VERSION ""

NS_ :

BS_:

BU_: SGCP MCPB MCPA IDCM EVCU2 ECM BPCM

BO_ 292 BATTERY_HV_STATUS1: 64 BPCM
 SG_ MessageCounter_BATT_HV_STATUS1 : 435|4@0+ (1,0) [0|15] "-"  SGCP,EVCU2,MCPB,MCPA,IDCM
 SG_ CRC_BATT_HV_STATUS1 : 447|8@0+ (1,0) [0|255] "-"  SGCP,EVCU2,MCPB,MCPA,IDCM
 SG_ HVBatContactorWeldCheck : 302|1@0+ (1,0) [0|1] "" EVCU2
 SG_ HVBatReady : 268|1@0+ (1,0) [0|1] "" EVCU2
 SG_ BPCM_DC_CntctrsMidTrmOpeningWarn : 267|1@0+ (1,0) [0|1] "" EVCU2
 SG_ BPCM_DC_CntctrsShtTrmOpeningWarn : 266|1@0+ (1,0) [0|1] "" EVCU2
 SG_ BPCM_HV_Char_Main_Contac_Sts : 178|3@0+ (1,0) [0|7] "" EVCU2
 SG_ BPCM_HV_Trac_Main_Contac_Sts : 181|3@0+ (1,0) [0|7] "" SGCP,EVCU2,MCPB,MCPA,IDCM
 SG_ BPCM_HV_BalancingMode : 164|2@0+ (1,0) [0|3] "" EVCU2
 SG_ BPCM_HV_ChargingBusVoltage : 162|11@0+ (1,0) [0|2047] "V"  EVCU2
 SG_ BPCM_HV_TractionBusVoltage : 146|11@0+ (1,0) [0|2047] "V"  SGCP,EVCU2,MCPB,MCPA,IDCM
 SG_ BPCM_Pwr_Limp_Home_On : 55|1@0+ (1,0) [0|1] "" EVCU2
 SG_ BPCM_HV_Trac_Bus_Sts : 36|3@0+ (1,0) [0|7] "" SGCP,EVCU2,MCPB,MCPA,IDCM
 SG_ BPCM_HV_Char_Bus_Sts : 39|3@0+ (1,0) [0|7] "" EVCU2
 SG_ BPCM_HV_SOH_Low : 30|7@0+ (1,0) [0|127] "" EVCU2
 SG_ BPCM_HV_SOH : 22|7@0+ (1,0) [0|127] "" EVCU2
 SG_ HVBatContactorOpenTime : 15|8@0+ (0.2,0) [0|51] "Hours"  EVCU2
 SG_ HVBatLastSlept : 7|8@0+ (0.2,0) [0|51] "Days"  EVCU2
 SG_ BPCMInterlockSts : 54|3@0+ (1,0) [0|4] "" EVCU2
 SG_ BPCM_HV_BatIntrlk_InternalStat : 271|3@0+ (1,0) [0|3] "" EVCU2
 SG_ BPCM_HV_Temperature_Min : 218|11@0+ (0.1,-40) [-40|164.7] "°C"  EVCU2
 SG_ BPCM_HV_Temperature_Max : 202|11@0+ (0.1,-40) [-40|164.7] "°C"  EVCU2
 SG_ BPCM_HV_Temperature_Avg : 186|11@0+ (0.1,-40) [-40|164.7] "°C"  EVCU2
 SG_ BPCM_HV_SOC : 33|10@0+ (0.1,0) [0|102.3] "%"  EVCU2
 SG_ BPCM_HV_Outlet_Temp : 250|11@0+ (0.1,-40) [-40|164.7] "°C"  EVCU2
 SG_ BPCM_HV_InternalVoltage : 133|14@0+ (0.1,90.9) [90.9|1729.2] "V"  EVCU2
 SG_ BPCM_HV_Inlet_Temp : 234|11@0+ (0.1,-40) [-40|164.7] "°C"  EVCU2
 SG_ BPCM_HV_Current : 71|16@0+ (0.1,-3276.7) [-3276.7|3276.8] "A"  EVCU2
 SG_ BPCM_HV_Capacity : 51|12@0+ (0.15,0) [0|614.25] "Ah"  EVCU2
 SG_ BPCM_HV_Battery_GFD_Sts : 149|3@0+ (1,0) [0|4] "" EVCU2
 SG_ BPCM_Wakeup_Request : 23|1@0+ (1,0) [0|1] "" EVCU2
 SG_ BPCM_HV_ThermalRunaway : 135|2@0+ (1,0) [0|3] "" EVCU2
 SG_ HVBP_Busbar_Temp : 423|8@0+ (1,-40) [-40|215] "°C"  EVCU2
 SG_ HVBP_BDU_Busbar_Temp : 415|8@0+ (1,-40) [-40|215] "°C"  EVCU2
 SG_ DC_Charge_Type_Status : 319|3@0+ (1,0) [0|7] "" EVCU2
 SG_ BPCM_Series_Voltage : 367|13@0+ (0.1,90.9) [90.9|910] "V"  EVCU2
 SG_ BPCM_Request_for_Aux_Load_off : 313|1@0+ (1,0) [0|1] "" EVCU2
 SG_ BPCM_HV_Trac_Main_Contac_Config : 316|3@0+ (1,0) [0|7] "" EVCU2
 SG_ BPCM_HV_InternalVoltageString2 : 351|13@0+ (0.1,90.9) [90.9|910] "V"  EVCU2
 SG_ BPCM_HV_InternalVoltageString1 : 335|13@0+ (0.1,90.9) [90.9|910] "V"  EVCU2
 SG_ BPCM_HV_DCFC_Isolation_Sts : 167|3@0+ (1,0) [0|7] "" EVCU2
 SG_ BPCM_HV_Trac_PreCha_Contac_Sts : 354|3@0+ (1,0) [0|7] "" EVCU2
 SG_ BPCM_HV_Current_String2 : 399|16@0+ (0.1,-3276.7) [-3276.7|3276.8] "A"  EVCU2

BO_ 485 BATTERY_HV_VLIMITS: 64 BPCM
 SG_ MessageCounter_BATT_HV_VLIMITS : 435|4@0+ (1,0) [0|15] "-"  EVCU2
 SG_ CRC_BATT_HV_VLIMITS : 447|8@0+ (1,0) [0|255] "-"  EVCU2
 SG_ BPCM_HV_NumCellMinTemp : 224|9@0+ (1,0) [0|511] "" EVCU2
 SG_ BPCM_HV_NumCellMaxTemp : 192|9@0+ (1,0) [0|511] "" EVCU2
 SG_ BPCM_HV_NumCellMinVolt : 80|9@0+ (1,0) [0|511] "" EVCU2
 SG_ BPCM_HV_NumCellMaxVolt : 64|9@0+ (1,0) [0|511] "" EVCU2
 SG_ BPCM_Min_Pk_Volt_Allowed : 50|11@0+ (1,0) [0|2047] "V"  EVCU2
 SG_ BPCM_Max_Pk_Volt_Allowed : 18|11@0+ (1,0) [0|2047] "V"  EVCU2
 SG_ BPCM_OCV_Min_Cell_Volt : 180|13@0+ (0.001,0) [0|8.191] "V"  EVCU2
 SG_ BPCM_OCV_Max_Cell_Volt : 164|13@0+ (0.001,0) [0|8.191] "V"  EVCU2
 SG_ BPCM_OCV_Avg_Cell_Volt : 148|13@0+ (0.001,0) [0|8.191] "V"  EVCU2
 SG_ BPCM_Min_Cell_Volt_Allowed : 36|13@0+ (0.001,0) [0|8.191] "V"  EVCU2
 SG_ BPCM_Max_Cell_Volt_Allowed : 132|13@0+ (0.001,0) [0|8.191] "V"  EVCU2
 SG_ BPCM_HV_Insulation_Resistance : 215|16@0+ (1,0) [0|65535] "kOhm"  EVCU2
 SG_ BPCM_Cell_Volt_Min : 116|13@0+ (0.001,0) [0|8.191] "V"  EVCU2
 SG_ BPCM_Cell_Volt_Max : 100|13@0+ (0.001,0) [0|8.191] "V"  EVCU2
 SG_ BPCM_Cell_Volt_Avg : 4|13@0+ (0.001,0) [0|8.191] "V"  EVCU2

BO_ 288 BATTERY_HV_POWERLIMITS: 64 BPCM
 SG_ BPCM_HV_HVBatChargeStat : 215|3@0+ (1,0) [0|7] "" EVCU2
 SG_ BPCM_HV_PwrLmtInstDschg : 245|14@0+ (0.1,0) [0|1638.3] "" EVCU2
 SG_ BPCM_HV_PwrLmtInstChrg : 309|14@0+ (0.1,0) [0|1638.3] "" EVCU2
 SG_ BPCM_HV_Pwr_MaxDischrg_ShrTrm : 69|14@0+ (0.1,0) [0|1638.3] "kW"  EVCU2
 SG_ BPCM_HV_Power_MaxDischarge_MdTrm : 133|14@0+ (0.1,0) [0|1638.3] "kW"  EVCU2
 SG_ BPCM_HV_Power_MaxDischarge_LgTrm : 197|14@0+ (0.1,0) [0|1638.3] "kW"  EVCU2
 SG_ BPCM_HV_Power_MaxCharge_ShrTrm : 53|14@0+ (0.1,0) [0|1638.3] "kW"  EVCU2
 SG_ BPCM_HV_Power_MaxCharge_MdTrm : 117|14@0+ (0.1,0) [0|1638.3] "kW"  EVCU2
 SG_ BPCM_HV_Power_MaxCharge_LgTrm : 181|14@0+ (0.1,0) [0|1638.3] "kW"  EVCU2
 SG_ BPCM_HV_CrntLmtInstDschg : 374|15@0+ (0.1,0) [0|3276.7] "A"  EVCU2
 SG_ BPCM_HV_CrntLmtInstChrg : 390|15@0+ (0.1,0) [0|3276.7] "A"  EVCU2
 SG_ BPCM_HV_ChargingCurrentProfile : 6|15@0+ (0.1,0) [0|3276.7] "A"  EVCU2
 SG_ BPCM_HV_Cell_MinDischrg_Imped : 228|13@0+ (0.01,0) [0|81.91] "Ohm"  EVCU2
 SG_ BPCM_HV_Cell_MaxDischrg_Imped : 212|13@0+ (0.01,0) [0|81.91] "Ohm"  EVCU2
 SG_ BPCM_CntctrsShtTrmOpeningWarn : 417|1@0+ (1,0) [0|1] "" EVCU2,IDCM
 SG_ BPCM_CntctrsMidTrmOpeningWarn : 416|1@0+ (1,0) [0|1] "" EVCU2
 SG_ MessageCounter_BATT_HV_POWERLIMS : 435|4@0+ (1,0) [0|15] "-"  EVCU2
 SG_ CRC_BATT_HV_POWERLIMS : 447|8@0+ (1,0) [0|255] "-"  EVCU2

BO_ 2654339273 PDC_INFO_FD_SGCP: 32 SGCP
 SG_ WakeupSource_FD16_SGCP : 95|8@0+ (1,0) [0|255] "" EVCU2
 SG_ WakeupSource_FD05_SGCP : 23|8@0+ (1,0) [0|255] "" EVCU2
 SG_ StayActiveSource_FD16_SGCP : 111|64@0+ (1,0) [0|0] "" EVCU2
 SG_ StayActiveSource_FD05_SGCP : 31|64@0+ (1,0) [0|0] "" EVCU2
 SG_ PreviousCanNMState_FD16_SGCP : 103|4@0+ (1,0) [0|15] "" EVCU2
 SG_ PreviousCanNMState_FD05_SGCP : 11|4@0+ (1,0) [0|15] "" EVCU2
 SG_ GenericFailSts_FD16_SGCP : 180|1@0+ (1,0) [0|1] "" EVCU2
 SG_ GenericFailSts_FD05_SGCP : 5|1@0+ (1,0) [0|1] "" EVCU2
 SG_ EOL_FD16_SGCP : 2|1@0+ (1,0) [0|1] "-"  EVCU2
 SG_ EOL_FD05_SGCP : 7|1@0+ (1,0) [0|1] "-"  EVCU2
 SG_ DES_FD16_SGCP : 183|2@0+ (1,0) [0|3] "" EVCU2
 SG_ DES_FD05_SGCP : 4|2@0+ (1,0) [0|3] "" EVCU2
 SG_ CurrentFailSts_FD16_SGCP : 181|1@0+ (1,0) [0|1] "" EVCU2
 SG_ CurrentFailSts_FD05_SGCP : 6|1@0+ (1,0) [0|1] "" EVCU2
 SG_ CurrentCanNMState_FD16_SGCP : 99|4@0+ (1,0) [0|15] "" EVCU2
 SG_ CurrentCanNMState_FD05_SGCP : 15|4@0+ (1,0) [0|15] "" EVCU2

BO_ 2654339161 PDC_INFO_FD_MCPB: 32 MCPB
 SG_ WakeupSource_FD16_MCPB : 95|8@0+ (1,0) [0|255] "" EVCU2
 SG_ WakeupSource_FD05_MCPB : 23|8@0+ (1,0) [0|255] "" EVCU2
 SG_ StayActiveSource_FD16_MCPB : 111|64@0+ (1,0) [0|0] "" EVCU2
 SG_ StayActiveSource_FD05_MCPB : 31|64@0+ (1,0) [0|0] "" EVCU2
 SG_ PreviousCanNMState_FD16_MCPB : 103|4@0+ (1,0) [0|15] "" EVCU2
 SG_ PreviousCanNMState_FD05_MCPB : 11|4@0+ (1,0) [0|15] "" EVCU2
 SG_ GenericFailSts_FD05_MCPB : 5|1@0+ (1,0) [0|1] "" EVCU2
 SG_ EOL_FD16_MCPB : 2|1@0+ (1,0) [0|1] "-"  EVCU2
 SG_ EOL_FD05_MCPB : 7|1@0+ (1,0) [0|1] "-"  EVCU2
 SG_ DES_FD05_MCPB : 4|2@0+ (1,0) [0|3] "" EVCU2
 SG_ CurrentFailSts_FD05_MCPB : 6|1@0+ (1,0) [0|1] "" EVCU2
 SG_ CurrentCanNMState_FD16_MCPB : 99|4@0+ (1,0) [0|15] "" EVCU2
 SG_ CurrentCanNMState_FD05_MCPB : 15|4@0+ (1,0) [0|15] "" EVCU2
 SG_ GenericFailSts_FD16_MCPB : 172|1@0+ (1,0) [0|1] "" EVCU2
 SG_ DES_FD16_MCPB : 175|2@0+ (1,0) [0|3] "" EVCU2
 SG_ CurrentFailSts_FD16_MCPB : 173|1@0+ (1,0) [0|1] "" EVCU2

BO_ 2654339160 PDC_INFO_FD_MCPA: 32 MCPA
 SG_ WakeupSource_FD16_MCPA : 95|8@0+ (1,0) [0|255] "" EVCU2
 SG_ WakeupSource_FD05_MCPA : 23|8@0+ (1,0) [0|255] "" EVCU2
 SG_ StayActiveSource_FD16_MCPA : 111|64@0+ (1,0) [0|0] "" EVCU2
 SG_ StayActiveSource_FD05_MCPA : 31|64@0+ (1,0) [0|0] "" EVCU2
 SG_ PreviousCanNMState_FD16_MCPA : 103|4@0+ (1,0) [0|15] "" EVCU2
 SG_ PreviousCanNMState_FD05_MCPA : 11|4@0+ (1,0) [0|15] "" EVCU2
 SG_ GenericFailSts_FD05_MCPA : 5|1@0+ (1,0) [0|1] "" EVCU2
 SG_ EOL_FD16_MCPA : 2|1@0+ (1,0) [0|1] "-"  EVCU2
 SG_ EOL_FD05_MCPA : 7|1@0+ (1,0) [0|1] "-"  EVCU2
 SG_ DES_FD05_MCPA : 4|2@0+ (1,0) [0|3] "" EVCU2
 SG_ CurrentFailSts_FD05_MCPA : 6|1@0+ (1,0) [0|1] "" EVCU2
 SG_ CurrentCanNMState_FD16_MCPA : 99|4@0+ (1,0) [0|15] "" EVCU2
 SG_ CurrentCanNMState_FD05_MCPA : 15|4@0+ (1,0) [0|15] "" EVCU2
 SG_ GenericFailSts_FD16_MCPA : 172|1@0+ (1,0) [0|1] "" EVCU2
 SG_ DES_FD16_MCPA : 175|2@0+ (1,0) [0|3] "" EVCU2
 SG_ CurrentFailSts_FD16_MCPA : 173|1@0+ (1,0) [0|1] "" EVCU2

BO_ 2654339142 PDC_INFO_FD_BPCM: 32 BPCM
 SG_ WakeupSource_FD05_BPCM : 175|8@0+ (1,0) [0|255] "" EVCU2
 SG_ StayActiveSource_FD05_BPCM : 99|64@0+ (1,0) [0|0] "" EVCU2
 SG_ PreviousCanNMState_FD05_BPCM : 103|4@0+ (1,0) [0|15] "" EVCU2
 SG_ GenericFailSts_FD05_BPCM : 89|1@0+ (1,0) [0|1] "" EVCU2
 SG_ EOL_FD05_BPCM : 1|1@0+ (1,0) [0|1] "-"  EVCU2
 SG_ DES_FD05_BPCM : 91|2@0+ (1,0) [0|3] "" EVCU2
 SG_ CurrentFailSts_FD05_BPCM : 6|1@0+ (1,0) [0|1] "" EVCU2
 SG_ CurrentCanNMState_FD05_BPCM : 95|4@0+ (1,0) [0|15] "" EVCU2

BO_ 2564682108 DIAGNOSTIC_ROE_SGCP: 8 SGCP
 SG_ N_PDU_18DDF17C : 7|64@0+ (1,0) [0|0] "" EVCU2

BO_ 2564682364 DIAGNOSTIC_ROE_FD_SGCP: 64 SGCP
 SG_ N_PDU_18DDF27C : 7|64@0+ (1,0) [0|0] "" EVCU2

BO_ 2564485500 DIAGNOSTIC_RESPONSE_SGCP: 8 SGCP
 SG_ N_PDU_18DAF17C : 7|64@0+ (1,0) [0|0] "" EVCU2

BO_ 2564485756 DIAGNOSTIC_RESPONSE_FD_SGCP: 64 SGCP
 SG_ N_PDU_18DAF27C : 7|64@0+ (1,0) [0|0] "" EVCU2

BO_ 2564455665 DIAGNOSTIC_REQUEST_SGCP: 8 EVCU2
 SG_ N_PDU_18DA7CF1 : 7|64@0+ (1,0) [0|0] "" SGCP

BO_ 2564455666 DIAGNOSTIC_REQUEST_FD_SGCP: 64 EVCU2
 SG_ N_PDU_18DA7CF2 : 7|64@0+ (1,0) [0|0] "" SGCP

BO_ 263 PT_SYSTEM_FD_1: 64 EVCU2
 SG_ OptimdStrtReqdActr : 2|3@0+ (1,0) [0|7] "" ECM
 SG_ OptimdEngStrtStpType : 7|5@0+ (1,0) [0|31] "" ECM
 SG_ OptimdEngOnOffCmd : 15|1@0+ (1,0) [0|1] "" ECM
 SG_ Hyb_ProducingTorque : 13|1@0+ (1,0) [0|1] "" ECM
 SG_ HCPFuelDisable : 14|1@0+ (1,0) [0|1] "" ECM
 SG_ PowertrainPrplsnActv_PT : 146|1@0+ (1,0) [0|1] "" MCPB,MCPA,BPCM
 SG_ GearEngagedForDisplay_PT : 12|5@0+ (1,0) [0|31] "" SGCP,MCPB,MCPA,BPCM
 SG_ GearEngaged_PT : 132|4@0+ (1,0) [0|15] "" MCPB
 SG_ DriveReady_PT : 166|1@0+ (1,0) [0|1] "" BPCM
 SG_ MessageCounter_PT_SYSTEM_FD_1 : 435|4@0+ (1,0) [0|15] "-"  SGCP,MCPB,MCPA,ECM
 SG_ GasPedalPositionFailSts_PT : 145|1@0+ (1,0) [0|1] "" ECM
 SG_ GasPedalPosition_PT : 31|8@0+ (0.392,0) [0|99.96] "%"  ECM
 SG_ CRC_PT_SYSTEM_FD_1 : 447|8@0+ (1,0) [0|255] "-"  SGCP,MCPB,MCPA,ECM
 SG_ PropulsionMode_PT : 314|3@0+ (1,0) [0|7] "" ECM
 SG_ PropulsionSystemActive_PT : 209|1@0+ (1,0) [0|1] "-"  ECM

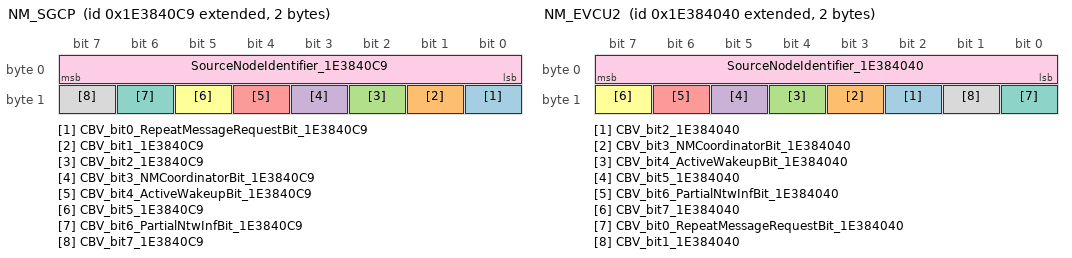
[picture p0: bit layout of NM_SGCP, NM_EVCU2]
BO_ 2654486729 NM_SGCP: 2 SGCP
 SG_ CBV_bit0_RepeatMessageRequestBit_1E3840C9 : 8|1@0+ (1,0) [0|1] "" EVCU2,MCPB,MCPA,IDCM,BPCM,ECM
 SG_ CBV_bit1_1E3840C9 : 9|1@0+ (1,0) [0|1] "" EVCU2,MCPB,MCPA,IDCM,BPCM,ECM
 SG_ CBV_bit2_1E3840C9 : 10|1@0+ (1,0) [0|1] "" EVCU2,MCPB,MCPA,IDCM,BPCM,ECM
 SG_ CBV_bit3_NMCoordinatorBit_1E3840C9 : 11|1@0+ (1,0) [0|1] "" EVCU2,MCPB,MCPA,IDCM,BPCM,ECM
 SG_ CBV_bit4_ActiveWakeupBit_1E3840C9 : 12|1@0+ (1,0) [0|1] "" EVCU2,MCPB,MCPA,IDCM,BPCM,ECM
 SG_ CBV_bit5_1E3840C9 : 13|1@0+ (1,0) [0|1] "" EVCU2,MCPB,MCPA,IDCM,BPCM,ECM
 SG_ CBV_bit6_PartialNtwInfBit_1E3840C9 : 14|1@0+ (1,0) [0|1] "" EVCU2,MCPB,MCPA,IDCM,BPCM,ECM
 SG_ CBV_bit7_1E3840C9 : 15|1@0+ (1,0) [0|1] "" EVCU2,MCPB,MCPA,IDCM,BPCM,ECM
 SG_ SourceNodeIdentifier_1E3840C9 : 7|8@0+ (1,0) [0|255] "-"  EVCU2,MCPB,MCPA,IDCM,BPCM,ECM

BO_ 216 PT_ENERGY_FD_1: 64 EVCU2
 SG_ MC_PT_ENERGY_FD_1 : 435|4@0+ (1,0) [0|15] "-"  IDCM,BPCM
 SG_ DCChrgVoltMin_PT : 55|14@0+ (0.1,0) [0|1638.30] "" Vector__XXX
 SG_ DCChrgVoltMax_PT : 151|14@0+ (0.1,0) [0|1638.30] "V"  Vector__XXX
 SG_ DCChrgPwrLim_PT : 119|14@0+ (0.1,-815) [-815|823.30] "kW"  Vector__XXX
 SG_ DCChrgCurrentRq_PT : 95|14@0+ (0.1,-815) [-815|823.30] "A"  Vector__XXX
 SG_ DCChrgCurrentLimit_PT : 21|14@0+ (0.1,-815) [-815|823.30] "A"  Vector__XXX
 SG_ DCChargeInitialized_PT : 56|1@0+ (1,0) [0|1] "" BPCM
 SG_ DCChargeEnRq_PT : 38|1@0+ (1,0) [0|1] "" Vector__XXX
 SG_ CRC_PT_ENERGY_FD_1 : 447|8@0+ (1,0) [0|255] "-"  IDCM,BPCM
 SG_ BPCM_OBCM_AC_ContactorCmd_PT : 140|3@0+ (1,0) [0|7] "" IDCM,BPCM
 SG_ BMS_HV_TracCntctr_Cmd_PT : 4|3@0+ (1,0) [0|7] "" MCPB,MCPA,IDCM,BPCM
 SG_ BMS_HV_RefTracHVBus_V_Vldty_PT : 23|1@0+ (1,0) [0|1] "" BPCM
 SG_ BMS_HV_RefTracHVBus_V_PT : 1|10@0+ (1,0) [0|1023] "" BPCM
 SG_ BMS_HV_GFD_Inhibition_PT : 39|1@0+ (1,0) [0|1] "" BPCM
 SG_ BMS_HV_DC_Chrgng_Cntct_K_Cmd_PT : 82|3@0+ (1,0) [0|7] "" MCPB,MCPA,IDCM,BPCM
 SG_ BatteryVoltage_Raw_PT : 97|10@0+ (0.2,0) [0|204.60] "V"  MCPB,MCPA,IDCM,BPCM
 SG_ APM_LV_VsetPoint_PT : 135|11@0+ (0.01,0) [0|20.47] "V"  IDCM
 SG_ APM_LV_VActual_PT : 71|9@0+ (0.04,0) [0|20.44] "V"  IDCM
 SG_ APM_LV_IMax_PT : 167|9@0+ (1,0) [0|511] "A"  IDCM
 SG_ APM_HV_IMax_PT : 87|5@0+ (0.8,0) [0|24.8] "A"  IDCM
 SG_ APM_TypeCtrl_PT : 78|4@0+ (1,0) [0|15] "" IDCM
 SG_ EVCU_Resp_AUX_LoadTurned_Off : 174|1@0+ (1,0) [0|1] "" BPCM
 SG_ DC_Charge_Type_Command : 121|2@0+ (1,0) [0|3] "" BPCM
 SG_ BMS_HV_Char_Main_Contac_Cmd_PT : 173|3@0+ (1,0) [0|7] "" BPCM

BO_ 1042 IDCM_ISO15118_STATUS1: 64 IDCM
 SG_ Contract_Certificate_Present : 244|1@0+ (1,0) [0|1] "" EVCU2
 SG_ EVSE_Offered_AC_Single_Phase : 234|1@0+ (1,0) [0|1] "" EVCU2
 SG_ EVSE_Offered_AC_Three_Phase : 233|1@0+ (1,0) [0|1] "" EVCU2

BO_ 1041 EVCU_ISO15118_STATUS1: 64 EVCU2
 SG_ EVMinCurrent : 264|9@0+ (1,0) [0|511] "A"  IDCM
 SG_ EVMaxVoltage : 233|10@0+ (1,0) [0|1023] "V"  IDCM
 SG_ EVMaxCurrent : 248|9@0+ (1,0) [0|511] "A"  IDCM
 SG_ Eamount : 281|18@0+ (1,0) [0|262143] "Wh"  IDCM

BO_ 2654486592 NM_EVCU2: 2 EVCU2
 SG_ CBV_bit2_1E384040 : 10|1@0+ (1,0) [0|1] "" SGCP,MCPB,MCPA,IDCM,BPCM,ECM
 SG_ CBV_bit3_NMCoordinatorBit_1E384040 : 11|1@0+ (1,0) [0|1] "" SGCP,MCPB,MCPA,IDCM,BPCM,ECM
 SG_ CBV_bit4_ActiveWakeupBit_1E384040 : 12|1@0+ (1,0) [0|1] "" SGCP,MCPB,MCPA,IDCM,BPCM,ECM
 SG_ CBV_bit5_1E384040 : 13|1@0+ (1,0) [0|1] "" SGCP,MCPB,MCPA,IDCM,BPCM,ECM
 SG_ CBV_bit6_PartialNtwInfBit_1E384040 : 14|1@0+ (1,0) [0|1] "" SGCP,MCPB,MCPA,IDCM,BPCM,ECM
 SG_ CBV_bit7_1E384040 : 15|1@0+ (1,0) [0|1] "" SGCP,MCPB,MCPA,IDCM,BPCM,ECM
 SG_ CBV_bit0_RepeatMessageRequestBit_1E384040 : 8|1@0+ (1,0) [0|1] "" SGCP,MCPB,MCPA,IDCM,BPCM,ECM
 SG_ CBV_bit1_1E384040 : 9|1@0+ (1,0) [0|1] "" SGCP,MCPB,MCPA,IDCM,BPCM,ECM
 SG_ SourceNodeIdentifier_1E384040 : 7|8@0+ (1,0) [0|255] "-"  SGCP,MCPB,MCPA,IDCM,BPCM,ECM

BO_ 2564455444 DIAGNOSTIC_RESPONSE_FOTA_SGCP: 64 SGCP
 SG_ N_PDU_18DA7C14 : 7|64@0+ (1,0) [0|0] "" EVCU2

BO_ 2564455669 DIAGNOSTIC_REQUEST_FOTA_SGCP: 64 EVCU2
 SG_ N_PDU_18DA7CF5 : 7|64@0+ (1,0) [0|0] "" SGCP

BO_ 1048 RPF_FD_3: 64 EVCU2
 SG_ V2H_HVCMS_EVMax_P_Limit : 21|14@0+ (0.1,-819.1) [-819.1|819.2] "kW"  IDCM

BO_ 1046 RPF_FD_1: 64 IDCM
 SG_ V2H_HVCMS_EVSEMaxPowerLimit : 7|14@0+ (0.1,-819.1) [-819.1|819.2] "kW"  EVCU2

BO_ 1811 REAL_TIME_CLOCK: 64 EVCU2
 SG_ Real_Time_Validity : 39|1@0+ (1,0) [0|1] "" SGCP,MCPB,MCPA
 SG_ Real_Time_Clock : 7|32@0+ (1,0) [0|4294967295] "" SGCP,MCPB,MCPA

BO_ 1070 SGCP_OBD_DTC: 32 SGCP
 SG_ SGCP_DTC_Stat2 : 26|3@0+ (1,0) [0|7] "" EVCU2
 SG_ SGCP_DTC_Stat1 : 18|3@0+ (1,0) [0|7] "" EVCU2
 SG_ SGCP_DTC_Idx2 : 31|5@0+ (1,0) [0|31] "" EVCU2
 SG_ SGCP_DTC_Idx1 : 23|5@0+ (1,0) [0|31] "" EVCU2
 SG_ SGCP_CalChar : 15|8@0+ (1,0) [0|255] "" EVCU2
 SG_ SGCP_Cal_ID_Idx : 7|6@0+ (1,0) [0|63] "" EVCU2
 SG_ MessageCounter_SGCP_OBD_DTC : 179|4@0+ (1,0) [0|15] ""  EVCU2
 SG_ CRC_SGCP_OBD_DTC : 191|8@0+ (1,0) [0|255] ""  EVCU2

BO_ 1065 MCPB_OBD_DTC: 32 MCPB
 SG_ MessageCounter_MCPB_OBD_DTC : 179|4@0+ (1,0) [0|15] ""  EVCU2
 SG_ MCPB_DTC_Stat2 : 26|3@0+ (1,0) [0|7] "" EVCU2
 SG_ MCPB_DTC_Stat1 : 18|3@0+ (1,0) [0|7] "" EVCU2
 SG_ MCPB_DTC_Idx2 : 31|5@0+ (1,0) [0|31] "" EVCU2
 SG_ MCPB_DTC_Idx1 : 23|5@0+ (1,0) [0|31] "" EVCU2
 SG_ MCPB_CalChar : 15|8@0+ (1,0) [0|255] "" EVCU2
 SG_ MCPB_Cal_ID_Idx : 7|6@0+ (1,0) [0|63] "" EVCU2
 SG_ CRC_MCPB_OBD_DTC : 191|8@0+ (1,0) [0|255] ""  EVCU2

BO_ 1057 MCPA_OBD_DTC: 32 MCPA
 SG_ MessageCounter_MCPA_OBD_DTC : 179|4@0+ (1,0) [0|15] ""  EVCU2
 SG_ MCPA_DTC_Stat2 : 26|3@0+ (1,0) [0|7] "" EVCU2
 SG_ MCPA_DTC_Stat1 : 18|3@0+ (1,0) [0|7] "" EVCU2
 SG_ MCPA_DTC_Idx2 : 31|5@0+ (1,0) [0|31] "" EVCU2
 SG_ MCPA_DTC_Idx1 : 23|5@0+ (1,0) [0|31] "" EVCU2
 SG_ MCPA_CalChar : 15|8@0+ (1,0) [0|255] "" EVCU2
 SG_ MCPA_Cal_ID_Idx : 7|6@0+ (1,0) [0|63] "" EVCU2
 SG_ CRC_MCPA_OBD_DTC : 191|8@0+ (1,0) [0|255] ""  EVCU2

CM_ SG_ 292 MessageCounter_BATT_HV_STATUS1 "This signal is a counter used for safety checks strategies. This counter is incremented of 1 (one) unit at each frame transmission.";
CM_ SG_ 292 CRC_BATT_HV_STATUS1 "CRC according to SAE J1850 standard at each frame transmission.";
CM_ SG_ 292 HVBatContactorWeldCheck "Contactor weld check report from BPCM for DC charging.";
CM_ SG_ 292 HVBatReady "High Voltage Battery Ready";
CM_ SG_ 292 BPCM_HV_Char_Main_Contac_Sts "DC Charging main contactor physical relay status.";
CM_ SG_ 292 BPCM_HV_Trac_Main_Contac_Sts "Traction main contactor physical relay status";
CM_ SG_ 292 BPCM_HV_BalancingMode "Balancing Mode";
CM_ SG_ 292 BPCM_HV_ChargingBusVoltage "Voltage measurement between positive main bus (after contactor) and negative charging branch.";
CM_ SG_ 292 BPCM_HV_TractionBusVoltage "Battery link traction bus voltage.";
CM_ SG_ 292 BPCM_Pwr_Limp_Home_On "Traction Battery Limp Home mode flag.";
CM_ SG_ 292 BPCM_HV_SOH_Low "State of Health calculated at low SOC.";
CM_ SG_ 292 BPCM_HV_SOH "Status of Healt";
CM_ SG_ 292 HVBatContactorOpenTime "Time Since Bat contactors last transitioned to Open.";
CM_ SG_ 292 HVBatLastSlept "Time since BPCM last went to sleep.";
CM_ SG_ 485 MessageCounter_BATT_HV_VLIMITS "This signal is a counter used for safety checks strategies. This counter is incremented of 1 (one) unit at each frame transmission.";
CM_ SG_ 485 CRC_BATT_HV_VLIMITS "CRC according to SAE J1850 standard at each frame transmission.";
CM_ SG_ 485 BPCM_HV_NumCellMinTemp "This signal indicates the Numner of the battery cell with the lowest temperature.";
CM_ SG_ 485 BPCM_HV_NumCellMaxTemp "This signal indicates the Number of the battery cell with the highest temperature.";
CM_ SG_ 485 BPCM_HV_NumCellMinVolt "This signal indicates the ID No. of cell with min. voltage";
CM_ SG_ 485 BPCM_HV_NumCellMaxVolt "This signal indicates the ID No. of cell with max. voltage";
CM_ SG_ 485 BPCM_Min_Pk_Volt_Allowed "This signal indicates the Minimum battery peak pack voltage.";
CM_ SG_ 485 BPCM_Max_Pk_Volt_Allowed "This signal indicates the Maximum battery pack voltage allowed.";
CM_ SG_ 292 BPCMInterlockSts "BPCM interlock state";
CM_ SG_ 292 BPCM_HV_BatIntrlk_InternalStat "HVIL Status internal";
CM_ SG_ 485 BPCM_OCV_Min_Cell_Volt "This signal indicates the Cell open circuit minimum voltage.";
CM_ SG_ 485 BPCM_OCV_Max_Cell_Volt "This signal indicates the Cell open circuit  maximum voltage.";
CM_ SG_ 485 BPCM_OCV_Avg_Cell_Volt "This signal indicates the Cell open circuit average voltage .";
CM_ SG_ 485 BPCM_Min_Cell_Volt_Allowed "This signal indicates the Minimum battery pack voltage.";
CM_ SG_ 485 BPCM_Max_Cell_Volt_Allowed "This signal indicates the Max cell voltage allowed.";
CM_ SG_ 485 BPCM_HV_Insulation_Resistance "This signal indicates the Insulation resistance.";
CM_ SG_ 485 BPCM_Cell_Volt_Min "This signal indicates the Min cell voltage.";
CM_ SG_ 485 BPCM_Cell_Volt_Max "This signal indicates the Max cell voltage.";
CM_ SG_ 485 BPCM_Cell_Volt_Avg "This signal indicates the Cell average voltage.";
CM_ SG_ 292 BPCM_HV_Temperature_Min "Battery Minimum Temperature 22/06/2020 Allegra Giordano - changes: Value, Max (previous values: 164,7 - 164,6) (Daniele Zaharia's request)";
CM_ SG_ 292 BPCM_HV_Temperature_Max "Battery Max Temperature 22/06/2020 Allegra Giordano - changes: Value, Max (previous values: 164,7 - 164,6) (Daniele Zaharia's request)";
CM_ SG_ 292 BPCM_HV_Temperature_Avg "Battery Average Temperature 22/06/2020 Allegra Giordano - changes: Value, Max (previous values: 164,7 - 164,6) (Daniele Zaharia' request)";
CM_ SG_ 292 BPCM_HV_SOC "State of Charge";
CM_ SG_ 292 BPCM_HV_Outlet_Temp "Outlet Temperature";
CM_ SG_ 292 BPCM_HV_InternalVoltage "Battery internal voltage.";
CM_ SG_ 292 BPCM_HV_Inlet_Temp "Inlet temperature";
CM_ SG_ 292 BPCM_HV_Current "Battery Current";
CM_ SG_ 292 BPCM_HV_Capacity "Battery Capacity";
CM_ SG_ 292 BPCM_HV_Battery_GFD_Sts "HV Battery ground fault detection(Isolation).";
CM_ SG_ 288 BPCM_HV_PwrLmtInstDschg "Instantaneous power prediction limit in discharge";
CM_ SG_ 288 BPCM_HV_PwrLmtInstChrg "Instantaneous power prediction limit in charge";
CM_ SG_ 288 BPCM_HV_Pwr_MaxDischrg_ShrTrm "This signal indicates the Maximum discharge power available for the next short term.";
CM_ SG_ 288 BPCM_HV_Power_MaxDischarge_MdTrm "This signal indicates the Maximum discharge power available for the next mid term.";
CM_ SG_ 288 BPCM_HV_Power_MaxDischarge_LgTrm "This signal indicates the Maximum discharge power available for the next long term.";
CM_ SG_ 288 BPCM_HV_Power_MaxCharge_ShrTrm "This signal indicates the Maximum charge power available for the next short term.";
CM_ SG_ 288 BPCM_HV_Power_MaxCharge_MdTrm "This signal indicates the Maximum charge power available for the next mid term.";
CM_ SG_ 288 BPCM_HV_Power_MaxCharge_LgTrm "This signal indicates the Maximum charge power available for the next long term.";
CM_ SG_ 288 BPCM_HV_CrntLmtInstDschg "BPCM_HV_CrntLmtInstDschg";
CM_ SG_ 288 BPCM_HV_CrntLmtInstChrg "BPCM_HV_CrntLmtInstChrg";
CM_ SG_ 288 BPCM_HV_ChargingCurrentProfile "This signal indicates the Charging current profile.";
CM_ SG_ 288 BPCM_HV_Cell_MinDischrg_Imped "This signal indicates the Maximum cell discharge impedance.";
CM_ SG_ 288 BPCM_HV_Cell_MaxDischrg_Imped "This signal indicates the Maximum cell discharge impedance.";
CM_ SG_ 288 BPCM_CntctrsShtTrmOpeningWarn "This signal indicates the Battery warning imminent emergency contactors opening.";
CM_ SG_ 288 BPCM_CntctrsMidTrmOpeningWarn "This signal indicates the Battery warning mid term emergency contactors opening.";
CM_ SG_ 2654339273 WakeupSource_FD16_SGCP "Indicates the reason the ECU was most recently awakened";
CM_ SG_ 2654339273 WakeupSource_FD05_SGCP "Indicates the reason the ECU was most recently awakened";
CM_ SG_ 2654339273 StayActiveSource_FD16_SGCP "Indicates the source that requests the ECU to stay active";
CM_ SG_ 2654339273 StayActiveSource_FD05_SGCP "Indicates the source that requests the ECU to stay active";
CM_ SG_ 2654339273 PreviousCanNMState_FD16_SGCP "Indicates the last CanNM state that the ECU existed in";
CM_ SG_ 2654339273 PreviousCanNMState_FD05_SGCP "Indicates the last CanNM state that the ECU existed in";
CM_ SG_ 2654339273 GenericFailSts_FD16_SGCP "Indicates the presence/absent of at least one DTC in the System Memory";
CM_ SG_ 2654339273 GenericFailSts_FD05_SGCP "Indicates the presence/absent of at least one DTC in the System Memory";
CM_ SG_ 2654339273 EOL_FD16_SGCP "Indicates if the ECU requires configuration data at the assembly plant End Of Line";
CM_ SG_ 2654339273 EOL_FD05_SGCP "Indicates if the ECU requires configuration data at the assembly plant End Of Line";
CM_ SG_ 2654339273 DES_FD16_SGCP "Indicates whether the ECU?s CAN cell is in either ErrorActive, or ErrorPassive state OR has just now recovered from a BusOff condition";
CM_ SG_ 2654339273 DES_FD05_SGCP "Indicates whether the ECU?s CAN cell is in either ErrorActive, or ErrorPassive state OR has just now recovered from a BusOff condition";
CM_ SG_ 2654339273 CurrentFailSts_FD16_SGCP "Indicates the presence/absence of at least one DTC with DTCStatus = present in the System Memory";
CM_ SG_ 2654339273 CurrentFailSts_FD05_SGCP "Indicates the presence/absence of at least one DTC with DTCStatus = present in the System Memory";
CM_ SG_ 2654339273 CurrentCanNMState_FD16_SGCP "Indicates that CanNM state the ECU is currently executing";
CM_ SG_ 2654339273 CurrentCanNMState_FD05_SGCP "Indicates that CanNM state the ECU is currently executing";
CM_ SG_ 2654339161 WakeupSource_FD16_MCPB "Indicates the reason the ECU was most recently awakened";
CM_ SG_ 2654339161 WakeupSource_FD05_MCPB "Indicates the reason the ECU was most recently awakened";
CM_ SG_ 2654339161 StayActiveSource_FD16_MCPB "Indicates the source that requests the ECU to stay active";
CM_ SG_ 2654339161 StayActiveSource_FD05_MCPB "Indicates the source that requests the ECU to stay active";
CM_ SG_ 2654339161 PreviousCanNMState_FD16_MCPB "Indicates the last CanNM state that the ECU existed in";
CM_ SG_ 2654339161 PreviousCanNMState_FD05_MCPB "Indicates the last CanNM state that the ECU existed in";
CM_ SG_ 2654339161 GenericFailSts_FD05_MCPB "Indicates the presence/absent of at least one DTC in the System Memory";
CM_ SG_ 2654339161 EOL_FD16_MCPB "Indicates if the ECU requires configuration data at the assembly plant End Of Line";
CM_ SG_ 2654339161 EOL_FD05_MCPB "Indicates if the ECU requires configuration data at the assembly plant End Of Line";
CM_ SG_ 2654339161 DES_FD05_MCPB "Indicates whether the ECU?s CAN cell is in either ErrorActive, or ErrorPassive state OR has just now recovered from a BusOff condition";
CM_ SG_ 2654339161 CurrentFailSts_FD05_MCPB "Indicates the presence/absence of at least one DTC with DTCStatus = present in the System Memory";
CM_ SG_ 2654339161 CurrentCanNMState_FD16_MCPB "Indicates that CanNM state the ECU is currently executing";
CM_ SG_ 2654339161 CurrentCanNMState_FD05_MCPB "Indicates that CanNM state the ECU is currently executing";
CM_ SG_ 2654339160 WakeupSource_FD16_MCPA "Indicates the reason the ECU was most recently awakened";
CM_ SG_ 2654339160 WakeupSource_FD05_MCPA "Indicates the reason the ECU was most recently awakened";
CM_ SG_ 2654339160 StayActiveSource_FD16_MCPA "Indicates the source that requests the ECU to stay active";
CM_ SG_ 2654339160 StayActiveSource_FD05_MCPA "Indicates the source that requests the ECU to stay active";
CM_ SG_ 2654339160 PreviousCanNMState_FD16_MCPA "Indicates the last CanNM state that the ECU existed in";
CM_ SG_ 2654339160 PreviousCanNMState_FD05_MCPA "Indicates the last CanNM state that the ECU existed in";
CM_ SG_ 2654339160 GenericFailSts_FD05_MCPA "Indicates the presence/absent of at least one DTC in the System Memory";
CM_ SG_ 2654339160 EOL_FD16_MCPA "Indicates if the ECU requires configuration data at the assembly plant End Of Line";
CM_ SG_ 2654339160 EOL_FD05_MCPA "Indicates if the ECU requires configuration data at the assembly plant End Of Line";
CM_ SG_ 2654339160 DES_FD05_MCPA "Indicates whether the ECU?s CAN cell is in either ErrorActive, or ErrorPassive state OR has just now recovered from a BusOff condition";
CM_ SG_ 2654339160 CurrentFailSts_FD05_MCPA "Indicates the presence/absence of at least one DTC with DTCStatus = present in the System Memory";
CM_ SG_ 2654339160 CurrentCanNMState_FD16_MCPA "Indicates that CanNM state the ECU is currently executing";
CM_ SG_ 2654339160 CurrentCanNMState_FD05_MCPA "Indicates that CanNM state the ECU is currently executing";
CM_ SG_ 263 OptimdStrtReqdActr "Signal to determine which actuator will be used to spin/crank the engine";
CM_ SG_ 263 OptimdEngStrtStpType "This signal indicates the type of engine start";
CM_ SG_ 263 OptimdEngOnOffCmd "Signal to give the final command on if the engine should be On or Off";
CM_ SG_ 263 Hyb_ProducingTorque "This signal indicates that hybrid control unit is declaring enging producing torque";
CM_ SG_ 263 HCPFuelDisable "Signal to disable fueling for engine ramp or ramp down purposes";
CM_ SG_ 263 PowertrainPrplsnActv_PT "Powertrain Propulsion System Status";
CM_ SG_ 263 GearEngagedForDisplay_PT "Transmission Gear Engaged signal for the instrument cluster display";
CM_ SG_ 263 GearEngaged_PT "Current engaged gear";
CM_ SG_ 263 DriveReady_PT "Drive Ready allowed status";
CM_ SG_ 216 MC_PT_ENERGY_FD_1 "Message counter according to SAE J1850 standard that has to be calculated from bit 63 to bit 8 at each frame transmission.";
CM_ SG_ 216 DCChrgVoltMin_PT "This signal indicates the DC charging voltage min for DC-DC";
CM_ SG_ 216 DCChrgVoltMax_PT "This signal indicates the DC charging voltage max for DC-DC";
CM_ SG_ 216 DCChrgPwrLim_PT "This signal indicates the DC Charging power limit for the DC-DC";
CM_ SG_ 216 DCChrgCurrentRq_PT "This signal indicates the Requested charging current to DC-DC";
CM_ SG_ 216 DCChrgCurrentLimit_PT "This signal indicates the DC charging current limit to DC-DC";
CM_ SG_ 216 DCChargeEnRq_PT "This signal indicates the DC charge enable request";
CM_ SG_ 216 CRC_PT_ENERGY_FD_1 "CRC according to SAE J1850 standard that has to be calculated from bit 63 to bit 8 at each frame transmission.";
CM_ SG_ 216 BPCM_OBCM_AC_ContactorCmd_PT "AC Charging Strategy Status";
CM_ SG_ 216 BMS_HV_TracCntctr_Cmd_PT "This signal indicates the contactor closure command";
CM_ SG_ 216 BMS_HV_RefTracHVBus_V_Vldty_PT "This signal indicates the HV bus voltage reference for HV Precharge validity";
CM_ SG_ 216 BMS_HV_RefTracHVBus_V_PT "This signal indicates the HV bus volatage reference for HV Precharge";
CM_ SG_ 216 BMS_HV_GFD_Inhibition_PT "This signal indicates the Battery GFD Inhibition, used when an external GFD detection is performed";
CM_ SG_ 216 BMS_HV_DC_Chrgng_Cntct_K_Cmd_PT "DC Charging K7 contactor command signal";
CM_ SG_ 216 BatteryVoltage_Raw_PT "Battery Voltage value measured from the electrified powertrain control module pin";
CM_ SG_ 216 APM_LV_VsetPoint_PT "The signal indicates the desired Low Voltage Set Point of Electronic Voltage Regulator";
CM_ SG_ 216 APM_LV_VActual_PT "This signal indicates the Low Voltage bus actual voltage";
CM_ SG_ 216 APM_LV_IMax_PT "This signal indicates the DC-DC maximun current limitations from the LV";
CM_ SG_ 216 APM_HV_IMax_PT "This signal indicates the DC-DC maximum current limitation from HV";
CM_ SG_ 2654339142 WakeupSource_FD05_BPCM "Indicates the reason the ECU was most recently awakened";
CM_ SG_ 2654339142 StayActiveSource_FD05_BPCM "Indicates the source that requests the ECU to stay active";
CM_ SG_ 2654339142 PreviousCanNMState_FD05_BPCM "Indicates the last CanNM state that the ECU existed in";
CM_ SG_ 2654339142 GenericFailSts_FD05_BPCM "Indicates the presence/absent of at least one DTC in the System Memory";
CM_ SG_ 2654339142 EOL_FD05_BPCM "Indicates if the ECU requires configuration data at the assembly plant End Of Line";
CM_ SG_ 2654339142 DES_FD05_BPCM "Indicates whether the ECU?s CAN cell is in either ErrorActive, or ErrorPassive state OR has just now recovered from a BusOff condition";
CM_ SG_ 2654339142 CurrentFailSts_FD05_BPCM "Indicates the presence/absence of at least one DTC with DTCStatus = present in the System Memory";
CM_ SG_ 2654339142 CurrentCanNMState_FD05_BPCM "Indicates that CanNM state the ECU is currently executing";
CM_ SG_ 292 BPCM_Wakeup_Request "BPCM Wakeup event";
CM_ SG_ 292 BPCM_HV_ThermalRunaway "Thermal runaway status";
CM_ SG_ 288 MessageCounter_BATT_HV_POWERLIMS "This signal is a counter used for safety checks strategies. This counter is incremented of 1 (one) unit at each frame transmission.";
CM_ SG_ 288 CRC_BATT_HV_POWERLIMS "CRC according to SAE J1850 standard at each frame transmission.";
CM_ SG_ 2654339161 GenericFailSts_FD16_MCPB "Indicates the presence/absent of at least one DTC in the System Memory";
CM_ SG_ 2654339161 DES_FD16_MCPB "Indicates whether the ECU?s CAN cell is in either ErrorActive, or ErrorPassive state OR has just now recovered from a BusOff condition";
CM_ SG_ 2654339161 CurrentFailSts_FD16_MCPB "Indicates the presence/absence of at least one DTC with DTCStatus = present in the System Memory";
CM_ SG_ 2654339160 GenericFailSts_FD16_MCPA "Indicates the presence/absent of at least one DTC in the System Memory";
CM_ SG_ 2654339160 DES_FD16_MCPA "Indicates whether the ECU?s CAN cell is in either ErrorActive, or ErrorPassive state OR has just now recovered from a BusOff condition";
CM_ SG_ 2654339160 CurrentFailSts_FD16_MCPA "Indicates the presence/absence of at least one DTC with DTCStatus = present in the System Memory";
CM_ SG_ 263 MessageCounter_PT_SYSTEM_FD_1 "This signal is a counter used for safety checks strategies. This counter is incremented of 1 (one) unit at each frame transmission.";
CM_ SG_ 263 GasPedalPositionFailSts_PT "Gas Pedal Position Failure Status";
CM_ SG_ 263 GasPedalPosition_PT "Gas Pedal Position in percentage";
CM_ SG_ 263 CRC_PT_SYSTEM_FD_1 "CRC according to SAE J1850 standard at each frame transmission.";
CM_ SG_ 2564682108 N_PDU_18DDF17C "This signal is used for diagnostic purposes";
CM_ SG_ 2564682364 N_PDU_18DDF27C "This signal is used for diagnostic purposes";
CM_ SG_ 2564485500 N_PDU_18DAF17C "This signal is used for diagnostic purposes";
CM_ SG_ 2564485756 N_PDU_18DAF27C "This signal is used for diagnostic purposes";
CM_ SG_ 2564455665 N_PDU_18DA7CF1 "This signal is used for diagnostic purposes";
CM_ SG_ 2564455666 N_PDU_18DA7CF2 "This signal is used for diagnostic purposes";
CM_ SG_ 2654486729 CBV_bit0_RepeatMessageRequestBit_1E3840C9 "Repeat Message Request Bit";
CM_ SG_ 2654486729 CBV_bit3_NMCoordinatorBit_1E3840C9 "NM Coordinator Sleep Bit";
CM_ SG_ 2654486729 CBV_bit4_ActiveWakeupBit_1E3840C9 "Active Wakeup Bit";
CM_ SG_ 2654486729 CBV_bit6_PartialNtwInfBit_1E3840C9 "Partial Network Information Bit (PNI)";
CM_ SG_ 2654486729 SourceNodeIdentifier_1E3840C9 "Source Node Identifier";
CM_ SG_ 2564455444 N_PDU_18DA7C14 "This signal is used for diagnostic purposes";
CM_ SG_ 2564455669 N_PDU_18DA7CF5 "This signal is used for diagnostic purposes";
CM_ SG_ 1048 V2H_HVCMS_EVMax_P_Limit "This signal indicates the HVCMS EV Max Power Limit.";
CM_ SG_ 1046 V2H_HVCMS_EVSEMaxPowerLimit "This signal indicates the HVCMS EVSE Max Power Limit.";
CM_ SG_ 1041 EVMinCurrent "EV Minumum current below which it is not energy or cost efficient";
CM_ SG_ 1041 EVMaxVoltage "RMS of the maximum voltage vehicle can accept";
CM_ SG_ 1041 EVMaxCurrent "EV Maximum current supported per Phase";
CM_ SG_ 1041 Eamount "Estimated Energy to Full charge";
CM_ SG_ 1811 Real_Time_Validity "EVCU Real Time Clock Validity";
CM_ SG_ 1811 Real_Time_Clock "EVCU Real Time Clock";
CM_ SG_ 216 APM_TypeCtrl_PT "This signal indicates the DC-DC request mode";
CM_ SG_ 292 HVBP_Busbar_Temp "HVBP Busbar temp";
CM_ SG_ 292 HVBP_BDU_Busbar_Temp "HVBP BDU Busbar temp";
CM_ SG_ 1070 SGCP_DTC_Stat2 "SGCP diagnostic trouble code status 1";
CM_ SG_ 1070 SGCP_DTC_Stat1 "SGCP diagnostic trouble code status 1";
CM_ SG_ 1070 SGCP_DTC_Idx2 "SGCP diagnostic trouble code index 2";
CM_ SG_ 1070 SGCP_DTC_Idx1 "SGCP diagnostic trouble code index 1";
CM_ SG_ 1070 SGCP_CalChar "SGCP Calibration CVN";
CM_ SG_ 1070 SGCP_Cal_ID_Idx "SGCP Calibration ID Index";
CM_ SG_ 1070 MessageCounter_SGCP_OBD_DTC "This signal is a counter used for safety checks strategies. This counter is incremented of 1 (one) unit at each frame transmission.";
CM_ SG_ 1070 CRC_SGCP_OBD_DTC "CRC according to SAE J1850 standard at each frame transmission.";
CM_ SG_ 263 PropulsionMode_PT "Propulsion mode of the vehicle";
CM_ SG_ 216 EVCU_Resp_AUX_LoadTurned_Off "Status of AUX load turned off";
CM_ SG_ 216 DC_Charge_Type_Command "800 V charging type information";
CM_ SG_ 1065 MessageCounter_MCPB_OBD_DTC "This signal is a counter used for safety checks strategies. This counter is incremented of 1 (one) unit at each frame transmission.";
CM_ SG_ 1065 MCPB_DTC_Stat2 "MCPB diagnostic trouble code status 1";
CM_ SG_ 1065 MCPB_DTC_Stat1 "MCPB diagnostic trouble code status 1";
CM_ SG_ 1065 MCPB_DTC_Idx2 "MCPB diagnostic trouble code index 2";
CM_ SG_ 1065 MCPB_DTC_Idx1 "MCPB diagnostic trouble code index 1";
CM_ SG_ 1065 MCPB_CalChar "MCPB Calibration CVN";
CM_ SG_ 1065 MCPB_Cal_ID_Idx "MCPB Calibration ID Index";
CM_ SG_ 1065 CRC_MCPB_OBD_DTC "CRC according to SAE J1850 standard at each frame transmission.";
CM_ SG_ 1057 MessageCounter_MCPA_OBD_DTC "This signal is a counter used for safety checks strategies. This counter is incremented of 1 (one) unit at each frame transmission.";
CM_ SG_ 1057 MCPA_DTC_Stat2 "MCPA diagnostic trouble code status 1";
CM_ SG_ 1057 MCPA_DTC_Stat1 "MCPA diagnostic trouble code status 1";
CM_ SG_ 1057 MCPA_DTC_Idx2 "MCPA diagnostic trouble code index 2";
CM_ SG_ 1057 MCPA_DTC_Idx1 "MCPA diagnostic trouble code index 1";
CM_ SG_ 1057 MCPA_CalChar "MCPA Calibration CVN";
CM_ SG_ 1057 MCPA_Cal_ID_Idx "MCPA Calibration ID Index";
CM_ SG_ 1057 CRC_MCPA_OBD_DTC "CRC according to SAE J1850 standard at each frame transmission.";
CM_ SG_ 292 DC_Charge_Type_Status "800 V charging type acknowledgement";
CM_ SG_ 292 BPCM_Series_Voltage "Voltage value of batery pack as per configuration";
CM_ SG_ 292 BPCM_Request_for_Aux_Load_off "Request to turn off AUX load for battery switching operation about to commence";
CM_ SG_ 292 BPCM_HV_Trac_Main_Contac_Config "Breaktor contactor configuration status to confirm DCFC control sequence";
CM_ SG_ 292 BPCM_HV_InternalVoltageString2 "Voltage measured  on battery side of DCFC breaktor";
CM_ SG_ 292 BPCM_HV_InternalVoltageString1 "Voltage measured  on battery side of DCFC breaktor";
CM_ SG_ 263 PropulsionSystemActive_PT "Propulsion system active, [1] = active";
CM_ SG_ 292 BPCM_HV_DCFC_Isolation_Sts "Status of DC Circuit isolation failure";
CM_ SG_ 216 BMS_HV_Char_Main_Contac_Cmd_PT "DC charging main contactor command";
CM_ SG_ 292 BPCM_HV_Trac_PreCha_Contac_Sts "Status of DC Circuit isolation failure";
CM_ SG_ 1042 Contract_Certificate_Present "If a contract certifiacte is available";
CM_ SG_ 1042 EVSE_Offered_AC_Single_Phase "AC Single Phase is offered";
CM_ SG_ 1042 EVSE_Offered_AC_Three_Phase "AC Three Phase is offered";
CM_ SG_ 292 BPCM_HV_Current_String2 "Battery Current (2nd String)";
BA_DEF_ SG_ "GenSigStartValue" INT 0 2147483647;
BA_DEF_ SG_ "GenSigInactiveValue" INT 0 2147483647;
BA_DEF_ SG_ "GenSigSendType" ENUM "NotUsed","OnWrite","OnWriteWithRepetition","OnChange","OnChangeWithRepetition","IfActive","IfActiveWithRepetition","NoSigSendType";
BA_DEF_ SG_ "SystemSignalLongSymbol" STRING ;
BA_DEF_ SG_ "GenSigTimeoutTime_BPCM" INT 0 65535;
BA_DEF_ SG_ "GenSigTimeoutTime_ECM" INT 0 65535;
BA_DEF_ SG_ "GenSigTimeoutTime_EVCU2" INT 0 65535;
BA_DEF_ SG_ "GenSigTimeoutTime_IDCM" INT 0 65535;
BA_DEF_ SG_ "GenSigTimeoutTime_MCPA" INT 0 65535;
BA_DEF_ SG_ "GenSigTimeoutTime_MCPB" INT 0 65535;
BA_DEF_ SG_ "GenSigTimeoutTime_SGCP" INT 0 65535;
BA_DEF_ BO_ "DiagRequest" ENUM "No","Yes";
BA_DEF_ BO_ "Type" ENUM "P","C","PE","COC","PE_Cntrl","E","E_Cntrl","OC","S","BAF","DC","EM","MM","ISO-TP","-";
BA_DEF_ BO_ "DiagResponse" ENUM "No","Yes";
BA_DEF_ BO_ "NmMessage" ENUM "No","Yes";
BA_DEF_ BO_ "GenMsgSendType" ENUM "Cyclic","NotUsed","NotUsed","NotUsed","NotUsed","NotUsed","NotUsed","NotUsed","NoMsgSendType";
BA_DEF_ BO_ "GenMsgNrOfRepetition" INT 0 255;
BA_DEF_ BO_ "GenMsgILSupport" ENUM "No","Yes";
BA_DEF_ BO_ "GenMsgStartDelayTime" INT 0 65535;
BA_DEF_ BO_ "GenMsgCycleTimeFast" INT 0 65535;
BA_DEF_ BO_ "GenMsgCycleTime" INT 0 65535;
BA_DEF_ BO_ "GenMsgDelayTime" INT 0 65535;
BA_DEF_ BO_ "NmAsrMessage" ENUM "No","Yes";
BA_DEF_ BO_ "DiagState" ENUM "No","Yes";
BA_DEF_ BO_ "DiagConnection" HEX 0 65535;
BA_DEF_ BO_ "VFrameFormat" ENUM "StandardCAN","ExtendedCAN","reserved","reserved","reserved","reserved","reserved","reserved","reserved","reserved","reserved","reserved","reserved","reserved","StandardCAN_FD","ExtendedCAN_FD";
BA_DEF_ BO_ "CANFD_BRS" ENUM "0","1";
BA_DEF_DEF_ "GenSigStartValue" 0;
BA_DEF_DEF_ "GenSigInactiveValue" 0;
BA_DEF_DEF_ "GenSigSendType" "NoSigSendType";
BA_DEF_DEF_ "SystemSignalLongSymbol" "";
BA_DEF_DEF_ "GenSigTimeoutTime_BPCM" 2500;
BA_DEF_DEF_ "GenSigTimeoutTime_ECM" 2500;
BA_DEF_DEF_ "GenSigTimeoutTime_EVCU2" 2500;
BA_DEF_DEF_ "GenSigTimeoutTime_IDCM" 2500;
BA_DEF_DEF_ "GenSigTimeoutTime_MCPA" 2500;
BA_DEF_DEF_ "GenSigTimeoutTime_MCPB" 2500;
BA_DEF_DEF_ "GenSigTimeoutTime_SGCP" 2500;
BA_DEF_DEF_ "DiagRequest" "No";
BA_DEF_DEF_ "Type" "-";
BA_DEF_DEF_ "DiagResponse" "No";
BA_DEF_DEF_ "NmMessage" "No";
BA_DEF_DEF_ "GenMsgSendType" "NoMsgSendType";
BA_DEF_DEF_ "GenMsgNrOfRepetition" 0;
BA_DEF_DEF_ "GenMsgILSupport" "No";
BA_DEF_DEF_ "GenMsgStartDelayTime" 0;
BA_DEF_DEF_ "GenMsgCycleTimeFast" 0;
BA_DEF_DEF_ "GenMsgCycleTime" 0;
BA_DEF_DEF_ "GenMsgDelayTime" 0;
BA_DEF_DEF_ "NmAsrMessage" "No";
BA_DEF_DEF_ "DiagState" "No";
BA_DEF_DEF_ "DiagConnection" 0;
BA_DEF_DEF_ "VFrameFormat" "StandardCAN_FD";
BA_DEF_DEF_ "CANFD_BRS" "0";
BA_ "Type" BO_ 292 1;
BA_ "GenMsgSendType" BO_ 292 0;
BA_ "GenMsgILSupport" BO_ 292 1;
BA_ "GenMsgCycleTime" BO_ 292 10;
BA_ "CANFD_BRS" BO_ 292 1;
BA_ "Type" BO_ 485 1;
BA_ "GenMsgSendType" BO_ 485 0;
BA_ "GenMsgILSupport" BO_ 485 1;
BA_ "GenMsgCycleTime" BO_ 485 20;
BA_ "CANFD_BRS" BO_ 485 1;
BA_ "Type" BO_ 288 1;
BA_ "GenMsgSendType" BO_ 288 0;
BA_ "GenMsgILSupport" BO_ 288 1;
BA_ "GenMsgCycleTime" BO_ 288 10;
BA_ "CANFD_BRS" BO_ 288 1;
BA_ "GenMsgSendType" BO_ 2654339273 0;
BA_ "GenMsgILSupport" BO_ 2654339273 1;
BA_ "GenMsgCycleTime" BO_ 2654339273 1000;
BA_ "VFrameFormat" BO_ 2654339273 15;
BA_ "CANFD_BRS" BO_ 2654339273 1;
BA_ "Type" BO_ 2654339273 1;
BA_ "Type" BO_ 2654339161 1;
BA_ "GenMsgSendType" BO_ 2654339161 0;
BA_ "GenMsgILSupport" BO_ 2654339161 1;
BA_ "GenMsgCycleTime" BO_ 2654339161 1000;
BA_ "VFrameFormat" BO_ 2654339161 15;
BA_ "CANFD_BRS" BO_ 2654339161 1;
BA_ "Type" BO_ 2654339160 1;
BA_ "GenMsgSendType" BO_ 2654339160 0;
BA_ "GenMsgILSupport" BO_ 2654339160 1;
BA_ "GenMsgCycleTime" BO_ 2654339160 1000;
BA_ "VFrameFormat" BO_ 2654339160 15;
BA_ "CANFD_BRS" BO_ 2654339160 1;
BA_ "Type" BO_ 2654339142 1;
BA_ "GenMsgSendType" BO_ 2654339142 0;
BA_ "GenMsgILSupport" BO_ 2654339142 1;
BA_ "GenMsgCycleTime" BO_ 2654339142 1000;
BA_ "VFrameFormat" BO_ 2654339142 15;
BA_ "CANFD_BRS" BO_ 2654339142 1;
BA_ "Type" BO_ 2564682108 8;
BA_ "DiagResponse" BO_ 2564682108 1;
BA_ "DiagConnection" BO_ 2564682108 61820;
BA_ "VFrameFormat" BO_ 2564682108 1;
BA_ "Type" BO_ 2564682364 8;
BA_ "DiagResponse" BO_ 2564682364 1;
BA_ "DiagConnection" BO_ 2564682364 62076;
BA_ "VFrameFormat" BO_ 2564682364 15;
BA_ "CANFD_BRS" BO_ 2564682364 1;
BA_ "Type" BO_ 2564485500 8;
BA_ "DiagResponse" BO_ 2564485500 1;
BA_ "DiagConnection" BO_ 2564485500 61820;
BA_ "VFrameFormat" BO_ 2564485500 1;
BA_ "Type" BO_ 2564485756 8;
BA_ "DiagResponse" BO_ 2564485756 1;
BA_ "DiagConnection" BO_ 2564485756 62076;
BA_ "VFrameFormat" BO_ 2564485756 15;
BA_ "CANFD_BRS" BO_ 2564485756 1;
BA_ "DiagRequest" BO_ 2564455665 1;
BA_ "Type" BO_ 2564455665 8;
BA_ "DiagConnection" BO_ 2564455665 61820;
BA_ "VFrameFormat" BO_ 2564455665 1;
BA_ "DiagRequest" BO_ 2564455666 1;
BA_ "Type" BO_ 2564455666 8;
BA_ "DiagConnection" BO_ 2564455666 62076;
BA_ "VFrameFormat" BO_ 2564455666 15;
BA_ "CANFD_BRS" BO_ 2564455666 1;
BA_ "Type" BO_ 263 1;
BA_ "GenMsgSendType" BO_ 263 0;
BA_ "GenMsgILSupport" BO_ 263 1;
BA_ "GenMsgCycleTime" BO_ 263 10;
BA_ "CANFD_BRS" BO_ 263 1;
BA_ "Type" BO_ 2654486729 8;
BA_ "NmMessage" BO_ 2654486729 1;
BA_ "NmAsrMessage" BO_ 2654486729 1;
BA_ "VFrameFormat" BO_ 2654486729 15;
BA_ "CANFD_BRS" BO_ 2654486729 1;
BA_ "Type" BO_ 216 1;
BA_ "GenMsgSendType" BO_ 216 0;
BA_ "GenMsgILSupport" BO_ 216 1;
BA_ "GenMsgCycleTime" BO_ 216 10;
BA_ "CANFD_BRS" BO_ 216 1;
BA_ "Type" BO_ 1042 1;
BA_ "GenMsgSendType" BO_ 1042 0;
BA_ "GenMsgILSupport" BO_ 1042 1;
BA_ "GenMsgCycleTime" BO_ 1042 100;
BA_ "CANFD_BRS" BO_ 1042 1;
BA_ "Type" BO_ 1041 1;
BA_ "GenMsgSendType" BO_ 1041 0;
BA_ "GenMsgILSupport" BO_ 1041 1;
BA_ "GenMsgCycleTime" BO_ 1041 100;
BA_ "CANFD_BRS" BO_ 1041 1;
BA_ "Type" BO_ 2654486592 8;
BA_ "NmMessage" BO_ 2654486592 1;
BA_ "NmAsrMessage" BO_ 2654486592 1;
BA_ "VFrameFormat" BO_ 2654486592 15;
BA_ "CANFD_BRS" BO_ 2654486592 1;
BA_ "Type" BO_ 2564455444 8;
BA_ "DiagResponse" BO_ 2564455444 1;
BA_ "DiagConnection" BO_ 2564455444 31764;
BA_ "VFrameFormat" BO_ 2564455444 15;
BA_ "CANFD_BRS" BO_ 2564455444 1;
BA_ "DiagRequest" BO_ 2564455669 1;
BA_ "Type" BO_ 2564455669 8;
BA_ "DiagConnection" BO_ 2564455669 62844;
BA_ "VFrameFormat" BO_ 2564455669 15;
BA_ "CANFD_BRS" BO_ 2564455669 1;
BA_ "Type" BO_ 1048 1;
BA_ "GenMsgSendType" BO_ 1048 0;
BA_ "GenMsgILSupport" BO_ 1048 1;
BA_ "GenMsgCycleTime" BO_ 1048 100;
BA_ "CANFD_BRS" BO_ 1048 1;
BA_ "Type" BO_ 1046 1;
BA_ "GenMsgSendType" BO_ 1046 0;
BA_ "GenMsgILSupport" BO_ 1046 1;
BA_ "GenMsgCycleTime" BO_ 1046 100;
BA_ "CANFD_BRS" BO_ 1046 1;
BA_ "Type" BO_ 1811 1;
BA_ "GenMsgSendType" BO_ 1811 0;
BA_ "GenMsgILSupport" BO_ 1811 1;
BA_ "GenMsgCycleTime" BO_ 1811 1000;
BA_ "GenMsgDelayTime" BO_ 1811 20;
BA_ "CANFD_BRS" BO_ 1811 1;
BA_ "Type" BO_ 1070 1;
BA_ "GenMsgSendType" BO_ 1070 0;
BA_ "GenMsgILSupport" BO_ 1070 1;
BA_ "GenMsgCycleTime" BO_ 1070 100;
BA_ "CANFD_BRS" BO_ 1070 1;
BA_ "CANFD_BRS" BO_ 1065 1;
BA_ "Type" BO_ 1065 1;
BA_ "GenMsgSendType" BO_ 1065 0;
BA_ "GenMsgILSupport" BO_ 1065 1;
BA_ "GenMsgCycleTime" BO_ 1065 100;
BA_ "Type" BO_ 1057 1;
BA_ "GenMsgSendType" BO_ 1057 0;
BA_ "GenMsgILSupport" BO_ 1057 1;
BA_ "GenMsgCycleTime" BO_ 1057 100;
BA_ "CANFD_BRS" BO_ 1057 1;
BA_ "GenSigTimeoutTime_ECM" SG_ 216 BMS_HV_Char_Main_Contac_Cmd_PT 0;
BA_ "GenSigTimeoutTime_EVCU2" SG_ 216 BMS_HV_Char_Main_Contac_Cmd_PT 0;
BA_ "GenSigTimeoutTime_IDCM" SG_ 216 BMS_HV_Char_Main_Contac_Cmd_PT 0;
BA_ "GenSigTimeoutTime_MCPA" SG_ 216 BMS_HV_Char_Main_Contac_Cmd_PT 0;
BA_ "GenSigTimeoutTime_MCPB" SG_ 216 BMS_HV_Char_Main_Contac_Cmd_PT 0;
BA_ "GenSigTimeoutTime_SGCP" SG_ 216 BMS_HV_Char_Main_Contac_Cmd_PT 0;
BA_ "GenSigTimeoutTime_BPCM" SG_ 216 APM_TypeCtrl_PT 0;
BA_ "GenSigTimeoutTime_ECM" SG_ 216 APM_TypeCtrl_PT 0;
BA_ "GenSigTimeoutTime_EVCU2" SG_ 216 APM_TypeCtrl_PT 0;
BA_ "GenSigTimeoutTime_MCPA" SG_ 216 APM_TypeCtrl_PT 0;
BA_ "GenSigTimeoutTime_MCPB" SG_ 216 APM_TypeCtrl_PT 0;
BA_ "GenSigTimeoutTime_SGCP" SG_ 216 APM_TypeCtrl_PT 0;
BA_ "GenSigTimeoutTime_BPCM" SG_ 2654486729 CBV_bit0_RepeatMessageRequestBit_1E3840C9 0;
BA_ "GenSigTimeoutTime_ECM" SG_ 2654486729 CBV_bit0_RepeatMessageRequestBit_1E3840C9 0;
BA_ "GenSigTimeoutTime_EVCU2" SG_ 2654486729 CBV_bit0_RepeatMessageRequestBit_1E3840C9 0;
BA_ "GenSigTimeoutTime_IDCM" SG_ 2654486729 CBV_bit0_RepeatMessageRequestBit_1E3840C9 0;
BA_ "GenSigTimeoutTime_MCPA" SG_ 2654486729 CBV_bit0_RepeatMessageRequestBit_1E3840C9 0;
BA_ "GenSigTimeoutTime_MCPB" SG_ 2654486729 CBV_bit0_RepeatMessageRequestBit_1E3840C9 0;
BA_ "GenSigTimeoutTime_SGCP" SG_ 2654486729 CBV_bit0_RepeatMessageRequestBit_1E3840C9 0;
BA_ "GenSigTimeoutTime_BPCM" SG_ 2654486729 CBV_bit1_1E3840C9 0;
BA_ "GenSigTimeoutTime_ECM" SG_ 2654486729 CBV_bit1_1E3840C9 0;
BA_ "GenSigTimeoutTime_EVCU2" SG_ 2654486729 CBV_bit1_1E3840C9 0;
BA_ "GenSigTimeoutTime_IDCM" SG_ 2654486729 CBV_bit1_1E3840C9 0;
BA_ "GenSigTimeoutTime_MCPA" SG_ 2654486729 CBV_bit1_1E3840C9 0;
BA_ "GenSigTimeoutTime_MCPB" SG_ 2654486729 CBV_bit1_1E3840C9 0;
BA_ "GenSigTimeoutTime_SGCP" SG_ 2654486729 CBV_bit1_1E3840C9 0;
BA_ "GenSigTimeoutTime_BPCM" SG_ 2654486729 CBV_bit2_1E3840C9 0;
BA_ "GenSigTimeoutTime_ECM" SG_ 2654486729 CBV_bit2_1E3840C9 0;
BA_ "GenSigTimeoutTime_EVCU2" SG_ 2654486729 CBV_bit2_1E3840C9 0;
BA_ "GenSigTimeoutTime_IDCM" SG_ 2654486729 CBV_bit2_1E3840C9 0;
BA_ "GenSigTimeoutTime_MCPA" SG_ 2654486729 CBV_bit2_1E3840C9 0;
BA_ "GenSigTimeoutTime_MCPB" SG_ 2654486729 CBV_bit2_1E3840C9 0;
BA_ "GenSigTimeoutTime_SGCP" SG_ 2654486729 CBV_bit2_1E3840C9 0;
BA_ "GenSigTimeoutTime_BPCM" SG_ 2654486729 CBV_bit3_NMCoordinatorBit_1E3840C9 0;
BA_ "GenSigTimeoutTime_ECM" SG_ 2654486729 CBV_bit3_NMCoordinatorBit_1E3840C9 0;
BA_ "GenSigTimeoutTime_EVCU2" SG_ 2654486729 CBV_bit3_NMCoordinatorBit_1E3840C9 0;
BA_ "GenSigTimeoutTime_IDCM" SG_ 2654486729 CBV_bit3_NMCoordinatorBit_1E3840C9 0;
BA_ "GenSigTimeoutTime_MCPA" SG_ 2654486729 CBV_bit3_NMCoordinatorBit_1E3840C9 0;
BA_ "GenSigTimeoutTime_MCPB" SG_ 2654486729 CBV_bit3_NMCoordinatorBit_1E3840C9 0;
BA_ "GenSigTimeoutTime_SGCP" SG_ 2654486729 CBV_bit3_NMCoordinatorBit_1E3840C9 0;
BA_ "GenSigTimeoutTime_BPCM" SG_ 2654486729 CBV_bit4_ActiveWakeupBit_1E3840C9 0;
BA_ "GenSigTimeoutTime_ECM" SG_ 2654486729 CBV_bit4_ActiveWakeupBit_1E3840C9 0;
BA_ "GenSigTimeoutTime_EVCU2" SG_ 2654486729 CBV_bit4_ActiveWakeupBit_1E3840C9 0;
BA_ "GenSigTimeoutTime_IDCM" SG_ 2654486729 CBV_bit4_ActiveWakeupBit_1E3840C9 0;
BA_ "GenSigTimeoutTime_MCPA" SG_ 2654486729 CBV_bit4_ActiveWakeupBit_1E3840C9 0;
BA_ "GenSigTimeoutTime_MCPB" SG_ 2654486729 CBV_bit4_ActiveWakeupBit_1E3840C9 0;
BA_ "GenSigTimeoutTime_SGCP" SG_ 2654486729 CBV_bit4_ActiveWakeupBit_1E3840C9 0;
BA_ "GenSigTimeoutTime_BPCM" SG_ 2654486729 CBV_bit5_1E3840C9 0;
BA_ "GenSigTimeoutTime_ECM" SG_ 2654486729 CBV_bit5_1E3840C9 0;
BA_ "GenSigTimeoutTime_EVCU2" SG_ 2654486729 CBV_bit5_1E3840C9 0;
BA_ "GenSigTimeoutTime_IDCM" SG_ 2654486729 CBV_bit5_1E3840C9 0;
BA_ "GenSigTimeoutTime_MCPA" SG_ 2654486729 CBV_bit5_1E3840C9 0;
BA_ "GenSigTimeoutTime_MCPB" SG_ 2654486729 CBV_bit5_1E3840C9 0;
BA_ "GenSigTimeoutTime_SGCP" SG_ 2654486729 CBV_bit5_1E3840C9 0;
BA_ "GenSigTimeoutTime_ECM" SG_ 2654486729 CBV_bit6_PartialNtwInfBit_1E3840C9 0;
BA_ "GenSigTimeoutTime_EVCU2" SG_ 2654486729 CBV_bit6_PartialNtwInfBit_1E3840C9 0;
BA_ "GenSigTimeoutTime_IDCM" SG_ 2654486729 CBV_bit6_PartialNtwInfBit_1E3840C9 0;
BA_ "GenSigTimeoutTime_MCPA" SG_ 2654486729 CBV_bit6_PartialNtwInfBit_1E3840C9 0;
BA_ "GenSigTimeoutTime_MCPB" SG_ 2654486729 CBV_bit6_PartialNtwInfBit_1E3840C9 0;
BA_ "GenSigTimeoutTime_SGCP" SG_ 2654486729 CBV_bit6_PartialNtwInfBit_1E3840C9 0;
BA_ "GenSigTimeoutTime_BPCM" SG_ 2654486729 CBV_bit6_PartialNtwInfBit_1E3840C9 0;
BA_ "GenSigTimeoutTime_MCPA" SG_ 2654339161 DES_FD16_MCPB 0;
BA_ "GenSigTimeoutTime_MCPB" SG_ 2654339161 DES_FD16_MCPB 0;
BA_ "GenSigTimeoutTime_SGCP" SG_ 2654339161 DES_FD16_MCPB 0;
BA_ "GenSigTimeoutTime_BPCM" SG_ 2654339161 GenericFailSts_FD16_MCPB 0;
BA_ "GenSigTimeoutTime_ECM" SG_ 2654339161 GenericFailSts_FD16_MCPB 0;
BA_ "GenSigTimeoutTime_IDCM" SG_ 2654339161 GenericFailSts_FD16_MCPB 0;
BA_ "GenSigTimeoutTime_MCPA" SG_ 2654339161 GenericFailSts_FD16_MCPB 0;
BA_ "GenSigTimeoutTime_MCPB" SG_ 2654339161 GenericFailSts_FD16_MCPB 0;
BA_ "GenSigTimeoutTime_SGCP" SG_ 2654339161 GenericFailSts_FD16_MCPB 0;
BA_ "GenSigTimeoutTime_BPCM" SG_ 2654339161 CurrentCanNMState_FD05_MCPB 0;
BA_ "GenSigTimeoutTime_ECM" SG_ 2654339161 CurrentCanNMState_FD05_MCPB 0;
BA_ "GenSigTimeoutTime_IDCM" SG_ 2654339161 CurrentCanNMState_FD05_MCPB 0;
BA_ "GenSigTimeoutTime_MCPA" SG_ 2654339161 CurrentCanNMState_FD05_MCPB 0;
BA_ "GenSigTimeoutTime_MCPB" SG_ 2654339161 CurrentCanNMState_FD05_MCPB 0;
BA_ "GenSigTimeoutTime_SGCP" SG_ 2654339161 CurrentCanNMState_FD05_MCPB 0;
BA_ "GenSigTimeoutTime_BPCM" SG_ 2654339161 CurrentCanNMState_FD16_MCPB 0;
BA_ "GenSigTimeoutTime_ECM" SG_ 2654339161 CurrentCanNMState_FD16_MCPB 0;
BA_ "GenSigTimeoutTime_IDCM" SG_ 2654339161 CurrentCanNMState_FD16_MCPB 0;
BA_ "GenSigTimeoutTime_MCPA" SG_ 2654339161 CurrentCanNMState_FD16_MCPB 0;
BA_ "GenSigTimeoutTime_MCPB" SG_ 2654339161 CurrentCanNMState_FD16_MCPB 0;
BA_ "GenSigTimeoutTime_SGCP" SG_ 2654339161 CurrentCanNMState_FD16_MCPB 0;
BA_ "GenSigTimeoutTime_BPCM" SG_ 2654339161 CurrentFailSts_FD05_MCPB 0;
BA_ "GenSigTimeoutTime_ECM" SG_ 2654339161 CurrentFailSts_FD05_MCPB 0;
BA_ "GenSigTimeoutTime_IDCM" SG_ 2654339161 CurrentFailSts_FD05_MCPB 0;
BA_ "GenSigTimeoutTime_MCPA" SG_ 2654339161 CurrentFailSts_FD05_MCPB 0;
BA_ "GenSigTimeoutTime_MCPB" SG_ 2654339161 CurrentFailSts_FD05_MCPB 0;
BA_ "GenSigTimeoutTime_SGCP" SG_ 2654339161 CurrentFailSts_FD05_MCPB 0;
BA_ "GenSigTimeoutTime_BPCM" SG_ 2654339161 DES_FD05_MCPB 0;
BA_ "GenSigTimeoutTime_ECM" SG_ 2654339161 DES_FD05_MCPB 0;
BA_ "GenSigTimeoutTime_IDCM" SG_ 2654339161 DES_FD05_MCPB 0;
BA_ "GenSigTimeoutTime_MCPA" SG_ 2654339161 DES_FD05_MCPB 0;
BA_ "GenSigTimeoutTime_MCPB" SG_ 2654339161 DES_FD05_MCPB 0;
BA_ "GenSigTimeoutTime_SGCP" SG_ 2654339161 DES_FD05_MCPB 0;
BA_ "GenSigTimeoutTime_BPCM" SG_ 2654339161 EOL_FD05_MCPB 0;
BA_ "GenSigTimeoutTime_ECM" SG_ 2654339161 EOL_FD05_MCPB 0;
BA_ "GenSigTimeoutTime_IDCM" SG_ 2654339161 EOL_FD05_MCPB 0;
BA_ "GenSigTimeoutTime_MCPA" SG_ 2654339161 EOL_FD05_MCPB 0;
BA_ "GenSigTimeoutTime_MCPB" SG_ 2654339161 EOL_FD05_MCPB 0;
BA_ "GenSigTimeoutTime_SGCP" SG_ 2654339161 EOL_FD05_MCPB 0;
BA_ "GenSigTimeoutTime_BPCM" SG_ 2654339161 EOL_FD16_MCPB 0;
BA_ "GenSigTimeoutTime_ECM" SG_ 2654339161 EOL_FD16_MCPB 0;
BA_ "GenSigTimeoutTime_IDCM" SG_ 2654339161 EOL_FD16_MCPB 0;
BA_ "GenSigTimeoutTime_MCPA" SG_ 2654339161 EOL_FD16_MCPB 0;
BA_ "GenSigTimeoutTime_MCPB" SG_ 2654339161 EOL_FD16_MCPB 0;
BA_ "GenSigTimeoutTime_SGCP" SG_ 2654339161 EOL_FD16_MCPB 0;
BA_ "GenSigTimeoutTime_BPCM" SG_ 2654339161 GenericFailSts_FD05_MCPB 0;
BA_ "GenSigTimeoutTime_ECM" SG_ 2654339161 GenericFailSts_FD05_MCPB 0;
BA_ "GenSigTimeoutTime_IDCM" SG_ 2654339161 GenericFailSts_FD05_MCPB 0;
BA_ "GenSigTimeoutTime_MCPA" SG_ 2654339161 GenericFailSts_FD05_MCPB 0;
BA_ "GenSigTimeoutTime_MCPB" SG_ 2654339161 GenericFailSts_FD05_MCPB 0;
BA_ "GenSigTimeoutTime_SGCP" SG_ 2654339161 GenericFailSts_FD05_MCPB 0;
BA_ "GenSigTimeoutTime_BPCM" SG_ 2654339161 PreviousCanNMState_FD05_MCPB 0;
BA_ "GenSigTimeoutTime_ECM" SG_ 2654339161 PreviousCanNMState_FD05_MCPB 0;
BA_ "GenSigTimeoutTime_IDCM" SG_ 2654339161 PreviousCanNMState_FD05_MCPB 0;
BA_ "GenSigTimeoutTime_MCPA" SG_ 2654339161 PreviousCanNMState_FD05_MCPB 0;
BA_ "GenSigTimeoutTime_MCPB" SG_ 2654339161 PreviousCanNMState_FD05_MCPB 0;
BA_ "GenSigTimeoutTime_SGCP" SG_ 2654339161 PreviousCanNMState_FD05_MCPB 0;
BA_ "GenSigTimeoutTime_BPCM" SG_ 2654339161 PreviousCanNMState_FD16_MCPB 0;
BA_ "GenSigTimeoutTime_ECM" SG_ 2654339161 PreviousCanNMState_FD16_MCPB 0;
BA_ "GenSigTimeoutTime_IDCM" SG_ 2654339161 PreviousCanNMState_FD16_MCPB 0;
BA_ "GenSigTimeoutTime_MCPA" SG_ 2654339161 PreviousCanNMState_FD16_MCPB 0;
BA_ "GenSigTimeoutTime_MCPB" SG_ 2654339161 PreviousCanNMState_FD16_MCPB 0;
BA_ "GenSigTimeoutTime_SGCP" SG_ 2654339161 PreviousCanNMState_FD16_MCPB 0;
BA_ "GenSigTimeoutTime_BPCM" SG_ 2654339161 StayActiveSource_FD05_MCPB 0;
BA_ "GenSigTimeoutTime_ECM" SG_ 2654339161 StayActiveSource_FD05_MCPB 0;
BA_ "GenSigTimeoutTime_IDCM" SG_ 2654339161 StayActiveSource_FD05_MCPB 0;
BA_ "GenSigTimeoutTime_MCPA" SG_ 2654339161 StayActiveSource_FD05_MCPB 0;
BA_ "GenSigTimeoutTime_MCPB" SG_ 2654339161 StayActiveSource_FD05_MCPB 0;
BA_ "GenSigTimeoutTime_SGCP" SG_ 2654339161 StayActiveSource_FD05_MCPB 0;
BA_ "GenSigTimeoutTime_BPCM" SG_ 2654339161 StayActiveSource_FD16_MCPB 0;
BA_ "GenSigTimeoutTime_ECM" SG_ 2654339161 StayActiveSource_FD16_MCPB 0;
BA_ "GenSigTimeoutTime_IDCM" SG_ 2654339161 StayActiveSource_FD16_MCPB 0;
BA_ "GenSigTimeoutTime_MCPA" SG_ 2654339161 StayActiveSource_FD16_MCPB 0;
BA_ "GenSigTimeoutTime_MCPB" SG_ 2654339161 StayActiveSource_FD16_MCPB 0;
BA_ "GenSigTimeoutTime_SGCP" SG_ 2654339161 StayActiveSource_FD16_MCPB 0;
BA_ "GenSigTimeoutTime_BPCM" SG_ 2654339161 WakeupSource_FD05_MCPB 0;
BA_ "GenSigTimeoutTime_ECM" SG_ 2654339161 WakeupSource_FD05_MCPB 0;
BA_ "GenSigTimeoutTime_IDCM" SG_ 2654339161 WakeupSource_FD05_MCPB 0;
BA_ "GenSigTimeoutTime_MCPA" SG_ 2654339161 WakeupSource_FD05_MCPB 0;
BA_ "GenSigTimeoutTime_MCPB" SG_ 2654339161 WakeupSource_FD05_MCPB 0;
BA_ "GenSigTimeoutTime_SGCP" SG_ 2654339161 WakeupSource_FD05_MCPB 0;
BA_ "GenSigTimeoutTime_BPCM" SG_ 2654339161 WakeupSource_FD16_MCPB 0;
BA_ "GenSigTimeoutTime_ECM" SG_ 2654339161 WakeupSource_FD16_MCPB 0;
BA_ "GenSigTimeoutTime_IDCM" SG_ 2654339161 WakeupSource_FD16_MCPB 0;
BA_ "GenSigTimeoutTime_MCPA" SG_ 2654339161 WakeupSource_FD16_MCPB 0;
BA_ "GenSigTimeoutTime_MCPB" SG_ 2654339161 WakeupSource_FD16_MCPB 0;
BA_ "GenSigTimeoutTime_SGCP" SG_ 2654339161 WakeupSource_FD16_MCPB 0;
BA_ "GenSigTimeoutTime_BPCM" SG_ 2654339273 CurrentCanNMState_FD05_SGCP 0;
BA_ "GenSigTimeoutTime_ECM" SG_ 2654339273 CurrentCanNMState_FD05_SGCP 0;
BA_ "GenSigTimeoutTime_IDCM" SG_ 2654339273 CurrentCanNMState_FD05_SGCP 0;
BA_ "GenSigTimeoutTime_MCPA" SG_ 2654339273 CurrentCanNMState_FD05_SGCP 0;
BA_ "GenSigTimeoutTime_MCPB" SG_ 2654339273 CurrentCanNMState_FD05_SGCP 0;
BA_ "GenSigTimeoutTime_SGCP" SG_ 2654339273 CurrentCanNMState_FD05_SGCP 0;
BA_ "GenSigTimeoutTime_BPCM" SG_ 2654339273 CurrentCanNMState_FD16_SGCP 0;
BA_ "GenSigTimeoutTime_ECM" SG_ 2654339273 CurrentCanNMState_FD16_SGCP 0;
BA_ "GenSigTimeoutTime_IDCM" SG_ 2654339273 CurrentCanNMState_FD16_SGCP 0;
BA_ "GenSigTimeoutTime_MCPA" SG_ 2654339273 CurrentCanNMState_FD16_SGCP 0;
BA_ "GenSigTimeoutTime_MCPB" SG_ 2654339273 CurrentCanNMState_FD16_SGCP 0;
BA_ "GenSigTimeoutTime_SGCP" SG_ 2654339273 CurrentCanNMState_FD16_SGCP 0;
BA_ "GenSigTimeoutTime_BPCM" SG_ 2654339160 CurrentFailSts_FD05_MCPA 0;
BA_ "GenSigTimeoutTime_ECM" SG_ 2654339160 CurrentFailSts_FD05_MCPA 0;
BA_ "GenSigTimeoutTime_IDCM" SG_ 2654339160 CurrentFailSts_FD05_MCPA 0;
BA_ "GenSigTimeoutTime_MCPA" SG_ 2654339160 CurrentFailSts_FD05_MCPA 0;
BA_ "GenSigTimeoutTime_MCPB" SG_ 2654339160 CurrentFailSts_FD05_MCPA 0;
BA_ "GenSigTimeoutTime_SGCP" SG_ 2654339160 CurrentFailSts_FD05_MCPA 0;
BA_ "GenSigTimeoutTime_ECM" SG_ 2654339160 CurrentCanNMState_FD05_MCPA 0;
BA_ "GenSigTimeoutTime_IDCM" SG_ 2654339160 CurrentCanNMState_FD05_MCPA 0;
BA_ "GenSigTimeoutTime_MCPA" SG_ 2654339160 CurrentCanNMState_FD05_MCPA 0;
BA_ "GenSigTimeoutTime_MCPB" SG_ 2654339160 CurrentCanNMState_FD05_MCPA 0;
BA_ "GenSigTimeoutTime_SGCP" SG_ 2654339160 CurrentCanNMState_FD05_MCPA 0;
BA_ "GenSigTimeoutTime_BPCM" SG_ 2654339160 CurrentCanNMState_FD16_MCPA 0;
BA_ "GenSigTimeoutTime_ECM" SG_ 2654339160 CurrentCanNMState_FD16_MCPA 0;
BA_ "GenSigTimeoutTime_IDCM" SG_ 2654339160 CurrentCanNMState_FD16_MCPA 0;
BA_ "GenSigTimeoutTime_MCPA" SG_ 2654339160 CurrentCanNMState_FD16_MCPA 0;
BA_ "GenSigTimeoutTime_MCPB" SG_ 2654339160 CurrentCanNMState_FD16_MCPA 0;
BA_ "GenSigTimeoutTime_SGCP" SG_ 2654339160 CurrentCanNMState_FD16_MCPA 0;
BA_ "GenSigTimeoutTime_BPCM" SG_ 2654339273 EOL_FD05_SGCP 0;
BA_ "GenSigTimeoutTime_ECM" SG_ 2654339273 EOL_FD05_SGCP 0;
BA_ "GenSigTimeoutTime_IDCM" SG_ 2654339273 EOL_FD05_SGCP 0;
BA_ "GenSigTimeoutTime_MCPA" SG_ 2654339273 EOL_FD05_SGCP 0;
BA_ "GenSigTimeoutTime_MCPB" SG_ 2654339273 EOL_FD05_SGCP 0;
BA_ "GenSigTimeoutTime_SGCP" SG_ 2654339273 EOL_FD05_SGCP 0;
BA_ "GenSigTimeoutTime_BPCM" SG_ 2654339273 EOL_FD16_SGCP 0;
BA_ "GenSigTimeoutTime_ECM" SG_ 2654339273 EOL_FD16_SGCP 0;
BA_ "GenSigTimeoutTime_IDCM" SG_ 2654339273 EOL_FD16_SGCP 0;
BA_ "GenSigTimeoutTime_MCPA" SG_ 2654339273 EOL_FD16_SGCP 0;
BA_ "GenSigTimeoutTime_MCPB" SG_ 2654339273 EOL_FD16_SGCP 0;
BA_ "GenSigTimeoutTime_SGCP" SG_ 2654339273 EOL_FD16_SGCP 0;
BA_ "GenSigTimeoutTime_BPCM" SG_ 2654339273 GenericFailSts_FD05_SGCP 0;
BA_ "GenSigTimeoutTime_ECM" SG_ 2654339273 GenericFailSts_FD05_SGCP 0;
BA_ "GenSigTimeoutTime_IDCM" SG_ 2654339273 GenericFailSts_FD05_SGCP 0;
BA_ "GenSigTimeoutTime_MCPA" SG_ 2654339273 GenericFailSts_FD05_SGCP 0;
BA_ "GenSigTimeoutTime_MCPB" SG_ 2654339273 GenericFailSts_FD05_SGCP 0;
BA_ "GenSigTimeoutTime_SGCP" SG_ 2654339273 GenericFailSts_FD05_SGCP 0;
BA_ "GenSigTimeoutTime_BPCM" SG_ 2654339273 GenericFailSts_FD16_SGCP 0;
BA_ "GenSigTimeoutTime_ECM" SG_ 2654339273 GenericFailSts_FD16_SGCP 0;
BA_ "GenSigTimeoutTime_IDCM" SG_ 2654339273 GenericFailSts_FD16_SGCP 0;
BA_ "GenSigTimeoutTime_MCPA" SG_ 2654339273 GenericFailSts_FD16_SGCP 0;
BA_ "GenSigTimeoutTime_MCPB" SG_ 2654339273 GenericFailSts_FD16_SGCP 0;
BA_ "GenSigTimeoutTime_SGCP" SG_ 2654339273 GenericFailSts_FD16_SGCP 0;
BA_ "GenSigTimeoutTime_BPCM" SG_ 2654339273 DES_FD05_SGCP 0;
BA_ "GenSigTimeoutTime_ECM" SG_ 2654339273 DES_FD05_SGCP 0;
BA_ "GenSigTimeoutTime_IDCM" SG_ 2654339273 DES_FD05_SGCP 0;
BA_ "GenSigTimeoutTime_MCPA" SG_ 2654339273 DES_FD05_SGCP 0;
BA_ "GenSigTimeoutTime_MCPB" SG_ 2654339273 DES_FD05_SGCP 0;
BA_ "GenSigTimeoutTime_SGCP" SG_ 2654339273 DES_FD05_SGCP 0;
BA_ "GenSigTimeoutTime_BPCM" SG_ 2654339273 DES_FD16_SGCP 0;
BA_ "GenSigTimeoutTime_ECM" SG_ 2654339273 DES_FD16_SGCP 0;
BA_ "GenSigTimeoutTime_IDCM" SG_ 2654339273 DES_FD16_SGCP 0;
BA_ "GenSigTimeoutTime_MCPA" SG_ 2654339273 DES_FD16_SGCP 0;
BA_ "GenSigTimeoutTime_MCPB" SG_ 2654339273 DES_FD16_SGCP 0;
BA_ "GenSigTimeoutTime_SGCP" SG_ 2654339273 DES_FD16_SGCP 0;
BA_ "GenSigTimeoutTime_SGCP" SG_ 2654339273 CurrentFailSts_FD16_SGCP 0;
BA_ "GenSigTimeoutTime_BPCM" SG_ 2654339273 CurrentFailSts_FD16_SGCP 0;
BA_ "GenSigTimeoutTime_ECM" SG_ 2654339273 CurrentFailSts_FD16_SGCP 0;
BA_ "GenSigTimeoutTime_IDCM" SG_ 2654339273 CurrentFailSts_FD16_SGCP 0;
BA_ "GenSigTimeoutTime_MCPA" SG_ 2654339273 CurrentFailSts_FD16_SGCP 0;
BA_ "GenSigTimeoutTime_MCPB" SG_ 2654339273 CurrentFailSts_FD16_SGCP 0;
BA_ "GenSigTimeoutTime_BPCM" SG_ 2654339273 CurrentFailSts_FD05_SGCP 0;
BA_ "GenSigTimeoutTime_ECM" SG_ 2654339273 CurrentFailSts_FD05_SGCP 0;
BA_ "GenSigTimeoutTime_IDCM" SG_ 2654339273 CurrentFailSts_FD05_SGCP 0;
BA_ "GenSigTimeoutTime_MCPA" SG_ 2654339273 CurrentFailSts_FD05_SGCP 0;
BA_ "GenSigTimeoutTime_MCPB" SG_ 2654339273 CurrentFailSts_FD05_SGCP 0;
BA_ "GenSigTimeoutTime_SGCP" SG_ 2654339273 CurrentFailSts_FD05_SGCP 0;
BA_ "GenSigTimeoutTime_BPCM" SG_ 2654339273 StayActiveSource_FD16_SGCP 0;
BA_ "GenSigTimeoutTime_ECM" SG_ 2654339273 StayActiveSource_FD16_SGCP 0;
BA_ "GenSigTimeoutTime_IDCM" SG_ 2654339273 StayActiveSource_FD16_SGCP 0;
BA_ "GenSigTimeoutTime_MCPA" SG_ 2654339273 StayActiveSource_FD16_SGCP 0;
BA_ "GenSigTimeoutTime_MCPB" SG_ 2654339273 StayActiveSource_FD16_SGCP 0;
BA_ "GenSigTimeoutTime_SGCP" SG_ 2654339273 StayActiveSource_FD16_SGCP 0;
BA_ "GenSigTimeoutTime_BPCM" SG_ 2654339273 StayActiveSource_FD05_SGCP 0;
BA_ "GenSigTimeoutTime_ECM" SG_ 2654339273 StayActiveSource_FD05_SGCP 0;
BA_ "GenSigTimeoutTime_IDCM" SG_ 2654339273 StayActiveSource_FD05_SGCP 0;
BA_ "GenSigTimeoutTime_MCPA" SG_ 2654339273 StayActiveSource_FD05_SGCP 0;
BA_ "GenSigTimeoutTime_MCPB" SG_ 2654339273 StayActiveSource_FD05_SGCP 0;
BA_ "GenSigTimeoutTime_SGCP" SG_ 2654339273 StayActiveSource_FD05_SGCP 0;
BA_ "GenSigTimeoutTime_BPCM" SG_ 2654339273 PreviousCanNMState_FD05_SGCP 0;
BA_ "GenSigTimeoutTime_ECM" SG_ 2654339273 PreviousCanNMState_FD05_SGCP 0;
BA_ "GenSigTimeoutTime_IDCM" SG_ 2654339273 PreviousCanNMState_FD05_SGCP 0;
BA_ "GenSigTimeoutTime_MCPA" SG_ 2654339273 PreviousCanNMState_FD05_SGCP 0;
BA_ "GenSigTimeoutTime_MCPB" SG_ 2654339273 PreviousCanNMState_FD05_SGCP 0;
BA_ "GenSigTimeoutTime_SGCP" SG_ 2654339273 PreviousCanNMState_FD05_SGCP 0;
BA_ "GenSigTimeoutTime_BPCM" SG_ 2654339273 PreviousCanNMState_FD16_SGCP 0;
BA_ "GenSigTimeoutTime_ECM" SG_ 2654339273 PreviousCanNMState_FD16_SGCP 0;
BA_ "GenSigTimeoutTime_IDCM" SG_ 2654339273 PreviousCanNMState_FD16_SGCP 0;
BA_ "GenSigTimeoutTime_MCPA" SG_ 2654339273 PreviousCanNMState_FD16_SGCP 0;
BA_ "GenSigTimeoutTime_MCPB" SG_ 2654339273 PreviousCanNMState_FD16_SGCP 0;
BA_ "GenSigTimeoutTime_SGCP" SG_ 2654339273 PreviousCanNMState_FD16_SGCP 0;
BA_ "GenSigTimeoutTime_BPCM" SG_ 292 BPCM_HV_Battery_GFD_Sts 0;
BA_ "GenSigTimeoutTime_ECM" SG_ 292 BPCM_HV_Battery_GFD_Sts 0;
BA_ "GenSigTimeoutTime_IDCM" SG_ 292 BPCM_HV_Battery_GFD_Sts 0;
BA_ "GenSigTimeoutTime_MCPA" SG_ 292 BPCM_HV_Battery_GFD_Sts 0;
BA_ "GenSigTimeoutTime_MCPB" SG_ 292 BPCM_HV_Battery_GFD_Sts 0;
BA_ "GenSigTimeoutTime_SGCP" SG_ 292 BPCM_HV_Battery_GFD_Sts 0;
BA_ "GenSigTimeoutTime_BPCM" SG_ 292 BPCM_HV_Capacity 0;
BA_ "GenSigTimeoutTime_ECM" SG_ 292 BPCM_HV_Capacity 0;
BA_ "GenSigTimeoutTime_IDCM" SG_ 292 BPCM_HV_Capacity 0;
BA_ "GenSigTimeoutTime_MCPA" SG_ 292 BPCM_HV_Capacity 0;
BA_ "GenSigTimeoutTime_MCPB" SG_ 292 BPCM_HV_Capacity 0;
BA_ "GenSigTimeoutTime_SGCP" SG_ 292 BPCM_HV_Capacity 0;
BA_ "GenSigTimeoutTime_BPCM" SG_ 292 BPCM_HV_Current 0;
BA_ "GenSigTimeoutTime_ECM" SG_ 292 BPCM_HV_Current 0;
BA_ "GenSigTimeoutTime_IDCM" SG_ 292 BPCM_HV_Current 0;
BA_ "GenSigTimeoutTime_MCPA" SG_ 292 BPCM_HV_Current 0;
BA_ "GenSigTimeoutTime_MCPB" SG_ 292 BPCM_HV_Current 0;
BA_ "GenSigTimeoutTime_SGCP" SG_ 292 BPCM_HV_Current 0;
BA_ "GenSigTimeoutTime_BPCM" SG_ 292 HVBatLastSlept 0;
BA_ "GenSigTimeoutTime_ECM" SG_ 292 HVBatLastSlept 0;
BA_ "GenSigTimeoutTime_IDCM" SG_ 292 HVBatLastSlept 0;
BA_ "GenSigTimeoutTime_MCPA" SG_ 292 HVBatLastSlept 0;
BA_ "GenSigTimeoutTime_MCPB" SG_ 292 HVBatLastSlept 0;
BA_ "GenSigTimeoutTime_SGCP" SG_ 292 HVBatLastSlept 0;
BA_ "GenSigTimeoutTime_BPCM" SG_ 292 HVBatContactorOpenTime 0;
BA_ "GenSigTimeoutTime_ECM" SG_ 292 HVBatContactorOpenTime 0;
BA_ "GenSigTimeoutTime_IDCM" SG_ 292 HVBatContactorOpenTime 0;
BA_ "GenSigTimeoutTime_MCPA" SG_ 292 HVBatContactorOpenTime 0;
BA_ "GenSigTimeoutTime_MCPB" SG_ 292 HVBatContactorOpenTime 0;
BA_ "GenSigTimeoutTime_SGCP" SG_ 292 HVBatContactorOpenTime 0;
BA_ "GenSigTimeoutTime_BPCM" SG_ 292 BPCM_HV_BatIntrlk_InternalStat 0;
BA_ "GenSigTimeoutTime_ECM" SG_ 292 BPCM_HV_BatIntrlk_InternalStat 0;
BA_ "GenSigTimeoutTime_IDCM" SG_ 292 BPCM_HV_BatIntrlk_InternalStat 0;
BA_ "GenSigTimeoutTime_MCPA" SG_ 292 BPCM_HV_BatIntrlk_InternalStat 0;
BA_ "GenSigTimeoutTime_MCPB" SG_ 292 BPCM_HV_BatIntrlk_InternalStat 0;
BA_ "GenSigTimeoutTime_SGCP" SG_ 292 BPCM_HV_BatIntrlk_InternalStat 0;
BA_ "GenSigTimeoutTime_BPCM" SG_ 292 BPCMInterlockSts 0;
BA_ "GenSigTimeoutTime_ECM" SG_ 292 BPCMInterlockSts 0;
BA_ "GenSigTimeoutTime_IDCM" SG_ 292 BPCMInterlockSts 0;
BA_ "GenSigTimeoutTime_MCPA" SG_ 292 BPCMInterlockSts 0;
BA_ "GenSigTimeoutTime_MCPB" SG_ 292 BPCMInterlockSts 0;
BA_ "GenSigTimeoutTime_SGCP" SG_ 292 BPCMInterlockSts 0;
BA_ "GenSigTimeoutTime_BPCM" SG_ 485 BPCM_Max_Cell_Volt_Allowed 0;
BA_ "GenSigTimeoutTime_ECM" SG_ 485 BPCM_Max_Cell_Volt_Allowed 0;
BA_ "GenSigTimeoutTime_IDCM" SG_ 485 BPCM_Max_Cell_Volt_Allowed 0;
BA_ "GenSigTimeoutTime_MCPA" SG_ 485 BPCM_Max_Cell_Volt_Allowed 0;
BA_ "GenSigTimeoutTime_MCPB" SG_ 485 BPCM_Max_Cell_Volt_Allowed 0;
BA_ "GenSigTimeoutTime_SGCP" SG_ 485 BPCM_Max_Cell_Volt_Allowed 0;
BA_ "GenSigTimeoutTime_BPCM" SG_ 485 BPCM_HV_Insulation_Resistance 0;
BA_ "GenSigTimeoutTime_ECM" SG_ 485 BPCM_HV_Insulation_Resistance 0;
BA_ "GenSigTimeoutTime_IDCM" SG_ 485 BPCM_HV_Insulation_Resistance 0;
BA_ "GenSigTimeoutTime_MCPA" SG_ 485 BPCM_HV_Insulation_Resistance 0;
BA_ "GenSigTimeoutTime_MCPB" SG_ 485 BPCM_HV_Insulation_Resistance 0;
BA_ "GenSigTimeoutTime_SGCP" SG_ 485 BPCM_HV_Insulation_Resistance 0;
BA_ "GenSigTimeoutTime_BPCM" SG_ 485 BPCM_Cell_Volt_Max 0;
BA_ "GenSigTimeoutTime_ECM" SG_ 485 BPCM_Cell_Volt_Max 0;
BA_ "GenSigTimeoutTime_IDCM" SG_ 485 BPCM_Cell_Volt_Max 0;
BA_ "GenSigTimeoutTime_MCPA" SG_ 485 BPCM_Cell_Volt_Max 0;
BA_ "GenSigTimeoutTime_MCPB" SG_ 485 BPCM_Cell_Volt_Max 0;
BA_ "GenSigTimeoutTime_SGCP" SG_ 485 BPCM_Cell_Volt_Max 0;
BA_ "GenSigTimeoutTime_BPCM" SG_ 485 BPCM_Cell_Volt_Min 0;
BA_ "GenSigTimeoutTime_ECM" SG_ 485 BPCM_Cell_Volt_Min 0;
BA_ "GenSigTimeoutTime_IDCM" SG_ 485 BPCM_Cell_Volt_Min 0;
BA_ "GenSigTimeoutTime_MCPA" SG_ 485 BPCM_Cell_Volt_Min 0;
BA_ "GenSigTimeoutTime_MCPB" SG_ 485 BPCM_Cell_Volt_Min 0;
BA_ "GenSigTimeoutTime_SGCP" SG_ 485 BPCM_Cell_Volt_Min 0;
BA_ "GenSigTimeoutTime_BPCM" SG_ 292 BPCM_HV_Temperature_Min 0;
BA_ "GenSigTimeoutTime_ECM" SG_ 292 BPCM_HV_Temperature_Min 0;
BA_ "GenSigTimeoutTime_IDCM" SG_ 292 BPCM_HV_Temperature_Min 0;
BA_ "GenSigTimeoutTime_MCPA" SG_ 292 BPCM_HV_Temperature_Min 0;
BA_ "GenSigTimeoutTime_MCPB" SG_ 292 BPCM_HV_Temperature_Min 0;
BA_ "GenSigTimeoutTime_SGCP" SG_ 292 BPCM_HV_Temperature_Min 0;
BA_ "GenSigTimeoutTime_BPCM" SG_ 292 BPCM_HV_Temperature_Avg 0;
BA_ "GenSigTimeoutTime_ECM" SG_ 292 BPCM_HV_Temperature_Avg 0;
BA_ "GenSigTimeoutTime_IDCM" SG_ 292 BPCM_HV_Temperature_Avg 0;
BA_ "GenSigTimeoutTime_MCPA" SG_ 292 BPCM_HV_Temperature_Avg 0;
BA_ "GenSigTimeoutTime_MCPB" SG_ 292 BPCM_HV_Temperature_Avg 0;
BA_ "GenSigTimeoutTime_SGCP" SG_ 292 BPCM_HV_Temperature_Avg 0;
BA_ "GenSigTimeoutTime_BPCM" SG_ 292 BPCM_HV_Temperature_Max 0;
BA_ "GenSigTimeoutTime_ECM" SG_ 292 BPCM_HV_Temperature_Max 0;
BA_ "GenSigTimeoutTime_IDCM" SG_ 292 BPCM_HV_Temperature_Max 0;
BA_ "GenSigTimeoutTime_MCPA" SG_ 292 BPCM_HV_Temperature_Max 0;
BA_ "GenSigTimeoutTime_MCPB" SG_ 292 BPCM_HV_Temperature_Max 0;
BA_ "GenSigTimeoutTime_SGCP" SG_ 292 BPCM_HV_Temperature_Max 0;
BA_ "GenSigStartValue" SG_ 292 BPCM_HV_Inlet_Temp 40;
BA_ "GenSigTimeoutTime_BPCM" SG_ 292 BPCM_HV_Inlet_Temp 0;
BA_ "GenSigTimeoutTime_ECM" SG_ 292 BPCM_HV_Inlet_Temp 0;
BA_ "GenSigTimeoutTime_IDCM" SG_ 292 BPCM_HV_Inlet_Temp 0;
BA_ "GenSigTimeoutTime_MCPA" SG_ 292 BPCM_HV_Inlet_Temp 0;
BA_ "GenSigTimeoutTime_MCPB" SG_ 292 BPCM_HV_Inlet_Temp 0;
BA_ "GenSigTimeoutTime_SGCP" SG_ 292 BPCM_HV_Inlet_Temp 0;
BA_ "GenSigTimeoutTime_BPCM" SG_ 292 BPCM_HV_InternalVoltage 0;
BA_ "GenSigTimeoutTime_ECM" SG_ 292 BPCM_HV_InternalVoltage 0;
BA_ "GenSigTimeoutTime_IDCM" SG_ 292 BPCM_HV_InternalVoltage 0;
BA_ "GenSigTimeoutTime_MCPA" SG_ 292 BPCM_HV_InternalVoltage 0;
BA_ "GenSigTimeoutTime_MCPB" SG_ 292 BPCM_HV_InternalVoltage 0;
BA_ "GenSigTimeoutTime_SGCP" SG_ 292 BPCM_HV_InternalVoltage 0;
BA_ "GenSigStartValue" SG_ 292 BPCM_HV_Outlet_Temp 40;
BA_ "GenSigTimeoutTime_BPCM" SG_ 292 BPCM_HV_Outlet_Temp 0;
BA_ "GenSigTimeoutTime_BPCM" SG_ 292 BPCM_HV_SOC 0;
BA_ "GenSigTimeoutTime_ECM" SG_ 292 BPCM_HV_SOC 0;
BA_ "GenSigTimeoutTime_IDCM" SG_ 292 BPCM_HV_SOC 0;
BA_ "GenSigTimeoutTime_MCPA" SG_ 292 BPCM_HV_SOC 0;
BA_ "GenSigTimeoutTime_MCPB" SG_ 292 BPCM_HV_SOC 0;
BA_ "GenSigTimeoutTime_SGCP" SG_ 292 BPCM_HV_SOC 0;
BA_ "GenSigTimeoutTime_BPCM" SG_ 292 BPCM_HV_Char_Main_Contac_Sts 0;
BA_ "GenSigTimeoutTime_ECM" SG_ 292 BPCM_HV_Char_Main_Contac_Sts 0;
BA_ "GenSigTimeoutTime_IDCM" SG_ 292 BPCM_HV_Char_Main_Contac_Sts 0;
BA_ "GenSigTimeoutTime_MCPA" SG_ 292 BPCM_HV_Char_Main_Contac_Sts 0;
BA_ "GenSigTimeoutTime_MCPB" SG_ 292 BPCM_HV_Char_Main_Contac_Sts 0;
BA_ "GenSigTimeoutTime_SGCP" SG_ 292 BPCM_HV_Char_Main_Contac_Sts 0;
BA_ "GenSigTimeoutTime_BPCM" SG_ 292 BPCM_HV_SOH 0;
BA_ "GenSigTimeoutTime_ECM" SG_ 292 BPCM_HV_SOH 0;
BA_ "GenSigTimeoutTime_IDCM" SG_ 292 BPCM_HV_SOH 0;
BA_ "GenSigTimeoutTime_MCPA" SG_ 292 BPCM_HV_SOH 0;
BA_ "GenSigTimeoutTime_MCPB" SG_ 292 BPCM_HV_SOH 0;
BA_ "GenSigTimeoutTime_SGCP" SG_ 292 BPCM_HV_SOH 0;
BA_ "GenSigTimeoutTime_BPCM" SG_ 292 BPCM_HV_SOH_Low 0;
BA_ "GenSigTimeoutTime_ECM" SG_ 292 BPCM_HV_SOH_Low 0;
BA_ "GenSigTimeoutTime_IDCM" SG_ 292 BPCM_HV_SOH_Low 0;
BA_ "GenSigTimeoutTime_MCPA" SG_ 292 BPCM_HV_SOH_Low 0;
BA_ "GenSigTimeoutTime_MCPB" SG_ 292 BPCM_HV_SOH_Low 0;
BA_ "GenSigTimeoutTime_SGCP" SG_ 292 BPCM_HV_SOH_Low 0;
BA_ "GenSigTimeoutTime_BPCM" SG_ 292 BPCM_HV_Char_Bus_Sts 0;
BA_ "GenSigTimeoutTime_ECM" SG_ 292 BPCM_HV_Char_Bus_Sts 0;
BA_ "GenSigTimeoutTime_IDCM" SG_ 292 BPCM_HV_Char_Bus_Sts 0;
BA_ "GenSigTimeoutTime_MCPA" SG_ 292 BPCM_HV_Char_Bus_Sts 0;
BA_ "GenSigTimeoutTime_MCPB" SG_ 292 BPCM_HV_Char_Bus_Sts 0;
BA_ "GenSigTimeoutTime_SGCP" SG_ 292 BPCM_HV_Char_Bus_Sts 0;
BA_ "GenSigTimeoutTime_BPCM" SG_ 292 BPCM_HV_Trac_Bus_Sts 0;
BA_ "GenSigTimeoutTime_ECM" SG_ 292 BPCM_HV_Trac_Bus_Sts 0;
BA_ "GenSigTimeoutTime_BPCM" SG_ 292 BPCM_HV_TractionBusVoltage 0;
BA_ "GenSigTimeoutTime_ECM" SG_ 292 BPCM_HV_TractionBusVoltage 0;
BA_ "GenSigTimeoutTime_BPCM" SG_ 292 BPCM_Pwr_Limp_Home_On 0;
BA_ "GenSigTimeoutTime_ECM" SG_ 292 BPCM_Pwr_Limp_Home_On 0;
BA_ "GenSigTimeoutTime_IDCM" SG_ 292 BPCM_Pwr_Limp_Home_On 0;
BA_ "GenSigTimeoutTime_MCPA" SG_ 292 BPCM_Pwr_Limp_Home_On 0;
BA_ "GenSigTimeoutTime_MCPB" SG_ 292 BPCM_Pwr_Limp_Home_On 0;
BA_ "GenSigTimeoutTime_SGCP" SG_ 292 BPCM_Pwr_Limp_Home_On 0;
BA_ "GenSigTimeoutTime_BPCM" SG_ 292 BPCM_HV_ChargingBusVoltage 0;
BA_ "GenSigTimeoutTime_ECM" SG_ 292 BPCM_HV_ChargingBusVoltage 0;
BA_ "GenSigTimeoutTime_IDCM" SG_ 292 BPCM_HV_ChargingBusVoltage 0;
BA_ "GenSigTimeoutTime_MCPA" SG_ 292 BPCM_HV_ChargingBusVoltage 0;
BA_ "GenSigTimeoutTime_MCPB" SG_ 292 BPCM_HV_ChargingBusVoltage 0;
BA_ "GenSigTimeoutTime_SGCP" SG_ 292 BPCM_HV_ChargingBusVoltage 0;
BA_ "GenSigTimeoutTime_BPCM" SG_ 292 BPCM_HV_BalancingMode 0;
BA_ "GenSigTimeoutTime_ECM" SG_ 292 BPCM_HV_BalancingMode 0;
BA_ "GenSigTimeoutTime_IDCM" SG_ 292 BPCM_HV_BalancingMode 0;
BA_ "GenSigTimeoutTime_MCPA" SG_ 292 BPCM_HV_BalancingMode 0;
BA_ "GenSigTimeoutTime_MCPB" SG_ 292 BPCM_HV_BalancingMode 0;
BA_ "GenSigTimeoutTime_SGCP" SG_ 292 BPCM_HV_BalancingMode 0;
BA_ "GenSigTimeoutTime_BPCM" SG_ 292 BPCM_HV_Trac_Main_Contac_Sts 0;
BA_ "GenSigTimeoutTime_ECM" SG_ 292 BPCM_HV_Trac_Main_Contac_Sts 0;
BA_ "GenSigTimeoutTime_BPCM" SG_ 292 BPCM_HV_InternalVoltageString1 0;
BA_ "GenSigTimeoutTime_ECM" SG_ 292 BPCM_HV_InternalVoltageString1 0;
BA_ "GenSigTimeoutTime_IDCM" SG_ 292 BPCM_HV_InternalVoltageString1 0;
BA_ "GenSigTimeoutTime_MCPA" SG_ 292 BPCM_HV_InternalVoltageString1 0;
BA_ "GenSigTimeoutTime_MCPB" SG_ 292 BPCM_HV_InternalVoltageString1 0;
BA_ "GenSigTimeoutTime_SGCP" SG_ 292 BPCM_HV_InternalVoltageString1 0;
BA_ "GenSigTimeoutTime_BPCM" SG_ 292 BPCM_HV_InternalVoltageString2 0;
BA_ "GenSigTimeoutTime_ECM" SG_ 292 BPCM_HV_InternalVoltageString2 0;
BA_ "GenSigTimeoutTime_IDCM" SG_ 292 BPCM_HV_InternalVoltageString2 0;
BA_ "GenSigTimeoutTime_MCPA" SG_ 292 BPCM_HV_InternalVoltageString2 0;
BA_ "GenSigTimeoutTime_MCPB" SG_ 292 BPCM_HV_InternalVoltageString2 0;
BA_ "GenSigTimeoutTime_SGCP" SG_ 292 BPCM_HV_InternalVoltageString2 0;
BA_ "GenSigStartValue" SG_ 292 BPCM_HV_Trac_Main_Contac_Config 1;
BA_ "GenSigTimeoutTime_BPCM" SG_ 292 BPCM_HV_Trac_Main_Contac_Config 0;
BA_ "GenSigTimeoutTime_ECM" SG_ 292 BPCM_HV_Trac_Main_Contac_Config 0;
BA_ "GenSigTimeoutTime_IDCM" SG_ 292 BPCM_HV_Trac_Main_Contac_Config 0;
BA_ "GenSigTimeoutTime_MCPA" SG_ 292 BPCM_HV_Trac_Main_Contac_Config 0;
BA_ "GenSigTimeoutTime_MCPB" SG_ 292 BPCM_HV_Trac_Main_Contac_Config 0;
BA_ "GenSigTimeoutTime_SGCP" SG_ 292 BPCM_HV_Trac_Main_Contac_Config 0;
BA_ "GenSigTimeoutTime_BPCM" SG_ 292 BPCM_Request_for_Aux_Load_off 0;
BA_ "GenSigTimeoutTime_ECM" SG_ 292 BPCM_Request_for_Aux_Load_off 0;
BA_ "GenSigTimeoutTime_IDCM" SG_ 292 BPCM_Request_for_Aux_Load_off 0;
BA_ "GenSigTimeoutTime_MCPA" SG_ 292 BPCM_Request_for_Aux_Load_off 0;
BA_ "GenSigTimeoutTime_MCPB" SG_ 292 BPCM_Request_for_Aux_Load_off 0;
BA_ "GenSigTimeoutTime_SGCP" SG_ 292 BPCM_Request_for_Aux_Load_off 0;
BA_ "GenSigTimeoutTime_BPCM" SG_ 292 DC_Charge_Type_Status 0;
BA_ "GenSigTimeoutTime_ECM" SG_ 292 DC_Charge_Type_Status 0;
BA_ "GenSigTimeoutTime_IDCM" SG_ 292 DC_Charge_Type_Status 0;
BA_ "GenSigTimeoutTime_MCPA" SG_ 292 DC_Charge_Type_Status 0;
BA_ "GenSigTimeoutTime_MCPB" SG_ 292 DC_Charge_Type_Status 0;
BA_ "GenSigTimeoutTime_SGCP" SG_ 292 DC_Charge_Type_Status 0;
BA_ "GenSigTimeoutTime_BPCM" SG_ 292 BPCM_Series_Voltage 0;
BA_ "GenSigTimeoutTime_ECM" SG_ 292 BPCM_Series_Voltage 0;
BA_ "GenSigTimeoutTime_IDCM" SG_ 292 BPCM_Series_Voltage 0;
BA_ "GenSigTimeoutTime_MCPA" SG_ 292 BPCM_Series_Voltage 0;
BA_ "GenSigTimeoutTime_MCPB" SG_ 292 BPCM_Series_Voltage 0;
BA_ "GenSigTimeoutTime_SGCP" SG_ 292 BPCM_Series_Voltage 0;
BA_ "GenSigTimeoutTime_BPCM" SG_ 292 BPCM_HV_Current_String2 0;
BA_ "GenSigTimeoutTime_ECM" SG_ 292 BPCM_HV_Current_String2 0;
BA_ "GenSigTimeoutTime_IDCM" SG_ 292 BPCM_HV_Current_String2 0;
BA_ "GenSigTimeoutTime_MCPA" SG_ 292 BPCM_HV_Current_String2 0;
BA_ "GenSigTimeoutTime_MCPB" SG_ 292 BPCM_HV_Current_String2 0;
BA_ "GenSigTimeoutTime_SGCP" SG_ 292 BPCM_HV_Current_String2 0;
BA_ "GenSigTimeoutTime_BPCM" SG_ 292 BPCM_HV_DCFC_Isolation_Sts 0;
BA_ "GenSigTimeoutTime_ECM" SG_ 292 BPCM_HV_DCFC_Isolation_Sts 0;
BA_ "GenSigTimeoutTime_IDCM" SG_ 292 BPCM_HV_DCFC_Isolation_Sts 0;
BA_ "GenSigTimeoutTime_MCPA" SG_ 292 BPCM_HV_DCFC_Isolation_Sts 0;
BA_ "GenSigTimeoutTime_MCPB" SG_ 292 BPCM_HV_DCFC_Isolation_Sts 0;
BA_ "GenSigTimeoutTime_SGCP" SG_ 292 BPCM_HV_DCFC_Isolation_Sts 0;
BA_ "GenSigTimeoutTime_BPCM" SG_ 292 BPCM_HV_Trac_PreCha_Contac_Sts 0;
BA_ "GenSigTimeoutTime_ECM" SG_ 292 BPCM_HV_Trac_PreCha_Contac_Sts 0;
BA_ "GenSigTimeoutTime_IDCM" SG_ 292 BPCM_HV_Trac_PreCha_Contac_Sts 0;
BA_ "GenSigTimeoutTime_MCPA" SG_ 292 BPCM_HV_Trac_PreCha_Contac_Sts 0;
BA_ "GenSigTimeoutTime_MCPB" SG_ 292 BPCM_HV_Trac_PreCha_Contac_Sts 0;
BA_ "GenSigTimeoutTime_SGCP" SG_ 292 BPCM_HV_Trac_PreCha_Contac_Sts 0;
BA_ "GenSigSendType" SG_ 292 BPCM_Wakeup_Request 3;
BA_ "GenSigTimeoutTime_BPCM" SG_ 292 BPCM_Wakeup_Request 0;
BA_ "GenSigTimeoutTime_ECM" SG_ 292 BPCM_Wakeup_Request 0;
BA_ "GenSigTimeoutTime_IDCM" SG_ 292 BPCM_Wakeup_Request 0;
BA_ "GenSigTimeoutTime_MCPA" SG_ 292 BPCM_Wakeup_Request 0;
BA_ "GenSigTimeoutTime_MCPB" SG_ 292 BPCM_Wakeup_Request 0;
BA_ "GenSigTimeoutTime_SGCP" SG_ 292 BPCM_Wakeup_Request 0;
BA_ "GenSigSendType" SG_ 292 BPCM_HV_ThermalRunaway 3;
BA_ "GenSigTimeoutTime_BPCM" SG_ 292 BPCM_HV_ThermalRunaway 0;
BA_ "GenSigTimeoutTime_ECM" SG_ 292 BPCM_HV_ThermalRunaway 0;
BA_ "GenSigTimeoutTime_IDCM" SG_ 292 BPCM_HV_ThermalRunaway 0;
BA_ "GenSigTimeoutTime_MCPA" SG_ 292 BPCM_HV_ThermalRunaway 0;
BA_ "GenSigTimeoutTime_MCPB" SG_ 292 BPCM_HV_ThermalRunaway 0;
BA_ "GenSigTimeoutTime_SGCP" SG_ 292 BPCM_HV_ThermalRunaway 0;
BA_ "GenSigTimeoutTime_BPCM" SG_ 292 HVBP_BDU_Busbar_Temp 0;
BA_ "GenSigTimeoutTime_ECM" SG_ 292 HVBP_BDU_Busbar_Temp 0;
BA_ "GenSigTimeoutTime_IDCM" SG_ 292 HVBP_BDU_Busbar_Temp 0;
BA_ "GenSigTimeoutTime_MCPA" SG_ 292 HVBP_BDU_Busbar_Temp 0;
BA_ "GenSigTimeoutTime_MCPB" SG_ 292 HVBP_BDU_Busbar_Temp 0;
BA_ "GenSigTimeoutTime_SGCP" SG_ 292 HVBP_BDU_Busbar_Temp 0;
BA_ "GenSigTimeoutTime_BPCM" SG_ 292 HVBP_Busbar_Temp 0;
BA_ "GenSigTimeoutTime_ECM" SG_ 292 HVBP_Busbar_Temp 0;
BA_ "GenSigTimeoutTime_IDCM" SG_ 292 HVBP_Busbar_Temp 0;
BA_ "GenSigTimeoutTime_MCPA" SG_ 292 HVBP_Busbar_Temp 0;
BA_ "GenSigTimeoutTime_MCPB" SG_ 292 HVBP_Busbar_Temp 0;
BA_ "GenSigTimeoutTime_SGCP" SG_ 292 HVBP_Busbar_Temp 0;
BA_ "GenSigTimeoutTime_BPCM" SG_ 292 CRC_BATT_HV_STATUS1 0;
BA_ "GenSigTimeoutTime_ECM" SG_ 292 CRC_BATT_HV_STATUS1 0;
BA_ "GenSigTimeoutTime_BPCM" SG_ 292 BPCM_DC_CntctrsShtTrmOpeningWarn 0;
BA_ "GenSigTimeoutTime_ECM" SG_ 292 BPCM_DC_CntctrsShtTrmOpeningWarn 0;
BA_ "GenSigTimeoutTime_IDCM" SG_ 292 BPCM_DC_CntctrsShtTrmOpeningWarn 0;
BA_ "GenSigTimeoutTime_MCPA" SG_ 292 BPCM_DC_CntctrsShtTrmOpeningWarn 0;
BA_ "GenSigTimeoutTime_MCPB" SG_ 292 BPCM_DC_CntctrsShtTrmOpeningWarn 0;
BA_ "GenSigTimeoutTime_SGCP" SG_ 292 BPCM_DC_CntctrsShtTrmOpeningWarn 0;
BA_ "GenSigTimeoutTime_BPCM" SG_ 292 BPCM_DC_CntctrsMidTrmOpeningWarn 0;
BA_ "GenSigTimeoutTime_ECM" SG_ 292 BPCM_DC_CntctrsMidTrmOpeningWarn 0;
BA_ "GenSigTimeoutTime_IDCM" SG_ 292 BPCM_DC_CntctrsMidTrmOpeningWarn 0;
BA_ "GenSigTimeoutTime_MCPA" SG_ 292 BPCM_DC_CntctrsMidTrmOpeningWarn 0;
BA_ "GenSigTimeoutTime_MCPB" SG_ 292 BPCM_DC_CntctrsMidTrmOpeningWarn 0;
BA_ "GenSigTimeoutTime_SGCP" SG_ 292 BPCM_DC_CntctrsMidTrmOpeningWarn 0;
BA_ "GenSigTimeoutTime_BPCM" SG_ 292 HVBatReady 0;
BA_ "GenSigTimeoutTime_ECM" SG_ 292 HVBatReady 0;
BA_ "GenSigTimeoutTime_IDCM" SG_ 292 HVBatReady 0;
BA_ "GenSigTimeoutTime_MCPA" SG_ 292 HVBatReady 0;
BA_ "GenSigTimeoutTime_MCPB" SG_ 292 HVBatReady 0;
BA_ "GenSigTimeoutTime_SGCP" SG_ 292 HVBatReady 0;
BA_ "GenSigTimeoutTime_BPCM" SG_ 292 MessageCounter_BATT_HV_STATUS1 0;
BA_ "GenSigTimeoutTime_ECM" SG_ 292 MessageCounter_BATT_HV_STATUS1 0;
BA_ "GenSigTimeoutTime_BPCM" SG_ 292 HVBatContactorWeldCheck 0;
BA_ "GenSigTimeoutTime_ECM" SG_ 292 HVBatContactorWeldCheck 0;
BA_ "GenSigTimeoutTime_IDCM" SG_ 292 HVBatContactorWeldCheck 0;
BA_ "GenSigTimeoutTime_MCPA" SG_ 292 HVBatContactorWeldCheck 0;
BA_ "GenSigTimeoutTime_MCPB" SG_ 292 HVBatContactorWeldCheck 0;
BA_ "GenSigTimeoutTime_SGCP" SG_ 292 HVBatContactorWeldCheck 0;
BA_ "GenSigTimeoutTime_ECM" SG_ 292 BPCM_HV_Outlet_Temp 0;
BA_ "GenSigTimeoutTime_IDCM" SG_ 292 BPCM_HV_Outlet_Temp 0;
BA_ "GenSigTimeoutTime_MCPA" SG_ 292 BPCM_HV_Outlet_Temp 0;
BA_ "GenSigTimeoutTime_MCPB" SG_ 292 BPCM_HV_Outlet_Temp 0;
BA_ "GenSigTimeoutTime_SGCP" SG_ 292 BPCM_HV_Outlet_Temp 0;
BA_ "GenSigTimeoutTime_BPCM" SG_ 2654486729 SourceNodeIdentifier_1E3840C9 0;
BA_ "GenSigTimeoutTime_ECM" SG_ 2654486729 SourceNodeIdentifier_1E3840C9 0;
BA_ "GenSigTimeoutTime_EVCU2" SG_ 2654486729 SourceNodeIdentifier_1E3840C9 0;
BA_ "GenSigTimeoutTime_IDCM" SG_ 2654486729 SourceNodeIdentifier_1E3840C9 0;
BA_ "GenSigTimeoutTime_MCPA" SG_ 2654486729 SourceNodeIdentifier_1E3840C9 0;
BA_ "GenSigTimeoutTime_MCPB" SG_ 2654486729 SourceNodeIdentifier_1E3840C9 0;
BA_ "GenSigTimeoutTime_SGCP" SG_ 2654486729 SourceNodeIdentifier_1E3840C9 0;
BA_ "GenSigTimeoutTime_BPCM" SG_ 2654486729 CBV_bit7_1E3840C9 0;
BA_ "GenSigTimeoutTime_ECM" SG_ 2654486729 CBV_bit7_1E3840C9 0;
BA_ "GenSigTimeoutTime_EVCU2" SG_ 2654486729 CBV_bit7_1E3840C9 0;
BA_ "GenSigTimeoutTime_IDCM" SG_ 2654486729 CBV_bit7_1E3840C9 0;
BA_ "GenSigTimeoutTime_MCPA" SG_ 2654486729 CBV_bit7_1E3840C9 0;
BA_ "GenSigTimeoutTime_MCPB" SG_ 2654486729 CBV_bit7_1E3840C9 0;
BA_ "GenSigTimeoutTime_SGCP" SG_ 2654486729 CBV_bit7_1E3840C9 0;
BA_ "GenSigTimeoutTime_ECM" SG_ 216 BatteryVoltage_Raw_PT 0;
BA_ "GenSigTimeoutTime_EVCU2" SG_ 216 BatteryVoltage_Raw_PT 0;
BA_ "GenSigTimeoutTime_SGCP" SG_ 216 BatteryVoltage_Raw_PT 0;
BA_ "GenSigTimeoutTime_MCPA" SG_ 263 MessageCounter_PT_SYSTEM_FD_1 0;
BA_ "GenSigTimeoutTime_MCPB" SG_ 263 MessageCounter_PT_SYSTEM_FD_1 0;
BA_ "GenSigTimeoutTime_SGCP" SG_ 263 MessageCounter_PT_SYSTEM_FD_1 0;
BA_ "GenSigTimeoutTime_MCPA" SG_ 263 CRC_PT_SYSTEM_FD_1 0;
BA_ "GenSigTimeoutTime_MCPB" SG_ 263 CRC_PT_SYSTEM_FD_1 0;
BA_ "GenSigTimeoutTime_SGCP" SG_ 263 CRC_PT_SYSTEM_FD_1 0;
BA_ "GenSigTimeoutTime_ECM" SG_ 216 BMS_HV_TracCntctr_Cmd_PT 0;
BA_ "GenSigTimeoutTime_EVCU2" SG_ 216 BMS_HV_TracCntctr_Cmd_PT 0;
BA_ "GenSigTimeoutTime_SGCP" SG_ 216 BMS_HV_TracCntctr_Cmd_PT 0;
BA_ "GenSigTimeoutTime_ECM" SG_ 216 BPCM_OBCM_AC_ContactorCmd_PT 0;
BA_ "GenSigTimeoutTime_EVCU2" SG_ 216 BPCM_OBCM_AC_ContactorCmd_PT 0;
BA_ "GenSigTimeoutTime_MCPA" SG_ 216 BPCM_OBCM_AC_ContactorCmd_PT 0;
BA_ "GenSigTimeoutTime_MCPB" SG_ 216 BPCM_OBCM_AC_ContactorCmd_PT 0;
BA_ "GenSigTimeoutTime_SGCP" SG_ 216 BPCM_OBCM_AC_ContactorCmd_PT 0;
BA_ "GenSigTimeoutTime_BPCM" SG_ 216 DCChargeEnRq_PT 0;
BA_ "GenSigTimeoutTime_ECM" SG_ 216 DCChargeEnRq_PT 0;
BA_ "GenSigTimeoutTime_EVCU2" SG_ 216 DCChargeEnRq_PT 0;
BA_ "GenSigTimeoutTime_IDCM" SG_ 216 DCChargeEnRq_PT 0;
BA_ "GenSigTimeoutTime_MCPA" SG_ 216 DCChargeEnRq_PT 0;
BA_ "GenSigTimeoutTime_MCPB" SG_ 216 DCChargeEnRq_PT 0;
BA_ "GenSigTimeoutTime_SGCP" SG_ 216 DCChargeEnRq_PT 0;
BA_ "GenSigTimeoutTime_ECM" SG_ 216 CRC_PT_ENERGY_FD_1 0;
BA_ "GenSigTimeoutTime_EVCU2" SG_ 216 CRC_PT_ENERGY_FD_1 0;
BA_ "GenSigTimeoutTime_MCPA" SG_ 216 CRC_PT_ENERGY_FD_1 0;
BA_ "GenSigTimeoutTime_MCPB" SG_ 216 CRC_PT_ENERGY_FD_1 0;
BA_ "GenSigTimeoutTime_SGCP" SG_ 216 CRC_PT_ENERGY_FD_1 0;
BA_ "GenSigStartValue" SG_ 216 DCChrgPwrLim_PT 815;
BA_ "GenSigTimeoutTime_BPCM" SG_ 216 DCChrgPwrLim_PT 0;
BA_ "GenSigTimeoutTime_ECM" SG_ 216 DCChrgPwrLim_PT 0;
BA_ "GenSigTimeoutTime_EVCU2" SG_ 216 DCChrgPwrLim_PT 0;
BA_ "GenSigTimeoutTime_IDCM" SG_ 216 DCChrgPwrLim_PT 0;
BA_ "GenSigTimeoutTime_MCPA" SG_ 216 DCChrgPwrLim_PT 0;
BA_ "GenSigTimeoutTime_MCPB" SG_ 216 DCChrgPwrLim_PT 0;
BA_ "GenSigTimeoutTime_SGCP" SG_ 216 DCChrgPwrLim_PT 0;
BA_ "GenSigStartValue" SG_ 216 DCChrgCurrentRq_PT 815;
BA_ "GenSigTimeoutTime_BPCM" SG_ 216 DCChrgCurrentRq_PT 0;
BA_ "GenSigTimeoutTime_ECM" SG_ 216 DCChrgCurrentRq_PT 0;
BA_ "GenSigTimeoutTime_EVCU2" SG_ 216 DCChrgCurrentRq_PT 0;
BA_ "GenSigTimeoutTime_IDCM" SG_ 216 DCChrgCurrentRq_PT 0;
BA_ "GenSigTimeoutTime_MCPA" SG_ 216 DCChrgCurrentRq_PT 0;
BA_ "GenSigTimeoutTime_MCPB" SG_ 216 DCChrgCurrentRq_PT 0;
BA_ "GenSigTimeoutTime_SGCP" SG_ 216 DCChrgCurrentRq_PT 0;
BA_ "GenSigStartValue" SG_ 216 DCChrgCurrentLimit_PT 815;
BA_ "GenSigTimeoutTime_BPCM" SG_ 216 DCChrgCurrentLimit_PT 0;
BA_ "GenSigTimeoutTime_ECM" SG_ 216 DCChrgCurrentLimit_PT 0;
BA_ "GenSigTimeoutTime_EVCU2" SG_ 216 DCChrgCurrentLimit_PT 0;
BA_ "GenSigTimeoutTime_IDCM" SG_ 216 DCChrgCurrentLimit_PT 0;
BA_ "GenSigTimeoutTime_MCPA" SG_ 216 DCChrgCurrentLimit_PT 0;
BA_ "GenSigTimeoutTime_MCPB" SG_ 216 DCChrgCurrentLimit_PT 0;
BA_ "GenSigTimeoutTime_SGCP" SG_ 216 DCChrgCurrentLimit_PT 0;
BA_ "GenSigTimeoutTime_ECM" SG_ 216 DCChargeInitialized_PT 0;
BA_ "GenSigTimeoutTime_EVCU2" SG_ 216 DCChargeInitialized_PT 0;
BA_ "GenSigTimeoutTime_IDCM" SG_ 216 DCChargeInitialized_PT 0;
BA_ "GenSigTimeoutTime_MCPA" SG_ 216 DCChargeInitialized_PT 0;
BA_ "GenSigTimeoutTime_MCPB" SG_ 216 DCChargeInitialized_PT 0;
BA_ "GenSigTimeoutTime_SGCP" SG_ 216 DCChargeInitialized_PT 0;
BA_ "GenSigTimeoutTime_EVCU2" SG_ 263 PowertrainPrplsnActv_PT 0;
BA_ "GenSigTimeoutTime_IDCM" SG_ 263 PowertrainPrplsnActv_PT 0;
BA_ "GenSigTimeoutTime_ECM" SG_ 216 MC_PT_ENERGY_FD_1 0;
BA_ "GenSigTimeoutTime_EVCU2" SG_ 216 MC_PT_ENERGY_FD_1 0;
BA_ "GenSigTimeoutTime_MCPA" SG_ 216 MC_PT_ENERGY_FD_1 0;
BA_ "GenSigTimeoutTime_MCPB" SG_ 216 MC_PT_ENERGY_FD_1 0;
BA_ "GenSigTimeoutTime_SGCP" SG_ 216 MC_PT_ENERGY_FD_1 0;
BA_ "GenSigTimeoutTime_BPCM" SG_ 216 DCChrgVoltMin_PT 0;
BA_ "GenSigTimeoutTime_ECM" SG_ 216 DCChrgVoltMin_PT 0;
BA_ "GenSigTimeoutTime_EVCU2" SG_ 216 DCChrgVoltMin_PT 0;
BA_ "GenSigTimeoutTime_IDCM" SG_ 216 DCChrgVoltMin_PT 0;
BA_ "GenSigTimeoutTime_MCPA" SG_ 216 DCChrgVoltMin_PT 0;
BA_ "GenSigTimeoutTime_MCPB" SG_ 216 DCChrgVoltMin_PT 0;
BA_ "GenSigTimeoutTime_SGCP" SG_ 216 DCChrgVoltMin_PT 0;
BA_ "GenSigTimeoutTime_BPCM" SG_ 216 DCChrgVoltMax_PT 0;
BA_ "GenSigTimeoutTime_ECM" SG_ 216 DCChrgVoltMax_PT 0;
BA_ "GenSigTimeoutTime_EVCU2" SG_ 216 DCChrgVoltMax_PT 0;
BA_ "GenSigTimeoutTime_IDCM" SG_ 216 DCChrgVoltMax_PT 0;
BA_ "GenSigTimeoutTime_MCPA" SG_ 216 DCChrgVoltMax_PT 0;
BA_ "GenSigTimeoutTime_MCPB" SG_ 216 DCChrgVoltMax_PT 0;
BA_ "GenSigTimeoutTime_SGCP" SG_ 216 DCChrgVoltMax_PT 0;
BA_ "GenSigTimeoutTime_ECM" SG_ 216 BMS_HV_RefTracHVBus_V_Vldty_PT 0;
BA_ "GenSigTimeoutTime_EVCU2" SG_ 216 BMS_HV_RefTracHVBus_V_Vldty_PT 0;
BA_ "GenSigTimeoutTime_IDCM" SG_ 216 BMS_HV_RefTracHVBus_V_Vldty_PT 0;
BA_ "GenSigTimeoutTime_MCPA" SG_ 216 BMS_HV_RefTracHVBus_V_Vldty_PT 0;
BA_ "GenSigTimeoutTime_MCPB" SG_ 216 BMS_HV_RefTracHVBus_V_Vldty_PT 0;
BA_ "GenSigTimeoutTime_SGCP" SG_ 216 BMS_HV_RefTracHVBus_V_Vldty_PT 0;
BA_ "GenSigTimeoutTime_ECM" SG_ 216 BMS_HV_RefTracHVBus_V_PT 0;
BA_ "GenSigTimeoutTime_EVCU2" SG_ 216 BMS_HV_RefTracHVBus_V_PT 0;
BA_ "GenSigTimeoutTime_IDCM" SG_ 216 BMS_HV_RefTracHVBus_V_PT 0;
BA_ "GenSigTimeoutTime_MCPA" SG_ 216 BMS_HV_RefTracHVBus_V_PT 0;
BA_ "GenSigTimeoutTime_MCPB" SG_ 216 BMS_HV_RefTracHVBus_V_PT 0;
BA_ "GenSigTimeoutTime_SGCP" SG_ 216 BMS_HV_RefTracHVBus_V_PT 0;
BA_ "GenSigTimeoutTime_ECM" SG_ 216 BMS_HV_GFD_Inhibition_PT 0;
BA_ "GenSigTimeoutTime_EVCU2" SG_ 216 BMS_HV_GFD_Inhibition_PT 0;
BA_ "GenSigTimeoutTime_IDCM" SG_ 216 BMS_HV_GFD_Inhibition_PT 0;
BA_ "GenSigTimeoutTime_MCPA" SG_ 216 BMS_HV_GFD_Inhibition_PT 0;
BA_ "GenSigTimeoutTime_MCPB" SG_ 216 BMS_HV_GFD_Inhibition_PT 0;
BA_ "GenSigTimeoutTime_SGCP" SG_ 216 BMS_HV_GFD_Inhibition_PT 0;
BA_ "GenSigTimeoutTime_ECM" SG_ 216 BMS_HV_DC_Chrgng_Cntct_K_Cmd_PT 0;
BA_ "GenSigTimeoutTime_EVCU2" SG_ 216 BMS_HV_DC_Chrgng_Cntct_K_Cmd_PT 0;
BA_ "GenSigTimeoutTime_SGCP" SG_ 216 BMS_HV_DC_Chrgng_Cntct_K_Cmd_PT 0;
BA_ "GenSigTimeoutTime_BPCM" SG_ 216 APM_LV_VsetPoint_PT 0;
BA_ "GenSigTimeoutTime_ECM" SG_ 216 APM_LV_VsetPoint_PT 0;
BA_ "GenSigTimeoutTime_EVCU2" SG_ 216 APM_LV_VsetPoint_PT 0;
BA_ "GenSigTimeoutTime_MCPA" SG_ 216 APM_LV_VsetPoint_PT 0;
BA_ "GenSigTimeoutTime_MCPB" SG_ 216 APM_LV_VsetPoint_PT 0;
BA_ "GenSigTimeoutTime_SGCP" SG_ 216 APM_LV_VsetPoint_PT 0;
BA_ "GenSigTimeoutTime_BPCM" SG_ 216 APM_LV_VActual_PT 0;
BA_ "GenSigTimeoutTime_ECM" SG_ 216 APM_LV_VActual_PT 0;
BA_ "GenSigTimeoutTime_EVCU2" SG_ 216 APM_LV_VActual_PT 0;
BA_ "GenSigTimeoutTime_MCPA" SG_ 216 APM_LV_VActual_PT 0;
BA_ "GenSigTimeoutTime_MCPB" SG_ 216 APM_LV_VActual_PT 0;
BA_ "GenSigTimeoutTime_SGCP" SG_ 216 APM_LV_VActual_PT 0;
BA_ "GenSigTimeoutTime_BPCM" SG_ 216 APM_LV_IMax_PT 0;
BA_ "GenSigTimeoutTime_ECM" SG_ 216 APM_LV_IMax_PT 0;
BA_ "GenSigTimeoutTime_EVCU2" SG_ 216 APM_LV_IMax_PT 0;
BA_ "GenSigTimeoutTime_MCPA" SG_ 216 APM_LV_IMax_PT 0;
BA_ "GenSigTimeoutTime_MCPB" SG_ 216 APM_LV_IMax_PT 0;
BA_ "GenSigTimeoutTime_SGCP" SG_ 216 APM_LV_IMax_PT 0;
BA_ "GenSigTimeoutTime_BPCM" SG_ 216 APM_HV_IMax_PT 0;
BA_ "GenSigTimeoutTime_ECM" SG_ 216 APM_HV_IMax_PT 0;
BA_ "GenSigTimeoutTime_EVCU2" SG_ 216 APM_HV_IMax_PT 0;
BA_ "GenSigTimeoutTime_MCPA" SG_ 216 APM_HV_IMax_PT 0;
BA_ "GenSigTimeoutTime_MCPB" SG_ 216 APM_HV_IMax_PT 0;
BA_ "GenSigTimeoutTime_SGCP" SG_ 216 APM_HV_IMax_PT 0;
BA_ "GenSigTimeoutTime_BPCM" SG_ 288 MessageCounter_BATT_HV_POWERLIMS 0;
BA_ "GenSigTimeoutTime_ECM" SG_ 288 MessageCounter_BATT_HV_POWERLIMS 0;
BA_ "GenSigTimeoutTime_IDCM" SG_ 288 MessageCounter_BATT_HV_POWERLIMS 0;
BA_ "GenSigTimeoutTime_MCPA" SG_ 288 MessageCounter_BATT_HV_POWERLIMS 0;
BA_ "GenSigTimeoutTime_MCPB" SG_ 288 MessageCounter_BATT_HV_POWERLIMS 0;
BA_ "GenSigTimeoutTime_SGCP" SG_ 288 MessageCounter_BATT_HV_POWERLIMS 0;
BA_ "GenSigTimeoutTime_BPCM" SG_ 288 CRC_BATT_HV_POWERLIMS 0;
BA_ "GenSigTimeoutTime_ECM" SG_ 288 CRC_BATT_HV_POWERLIMS 0;
BA_ "GenSigTimeoutTime_IDCM" SG_ 288 CRC_BATT_HV_POWERLIMS 0;
BA_ "GenSigTimeoutTime_MCPA" SG_ 288 CRC_BATT_HV_POWERLIMS 0;
BA_ "GenSigTimeoutTime_MCPB" SG_ 288 CRC_BATT_HV_POWERLIMS 0;
BA_ "GenSigTimeoutTime_SGCP" SG_ 288 CRC_BATT_HV_POWERLIMS 0;
BA_ "GenSigTimeoutTime_BPCM" SG_ 2654339273 WakeupSource_FD16_SGCP 0;
BA_ "GenSigTimeoutTime_ECM" SG_ 2654339273 WakeupSource_FD16_SGCP 0;
BA_ "GenSigTimeoutTime_IDCM" SG_ 2654339273 WakeupSource_FD16_SGCP 0;
BA_ "GenSigTimeoutTime_MCPA" SG_ 2654339273 WakeupSource_FD16_SGCP 0;
BA_ "GenSigTimeoutTime_MCPB" SG_ 2654339273 WakeupSource_FD16_SGCP 0;
BA_ "GenSigTimeoutTime_SGCP" SG_ 2654339273 WakeupSource_FD16_SGCP 0;
BA_ "GenSigTimeoutTime_BPCM" SG_ 2654339273 WakeupSource_FD05_SGCP 0;
BA_ "GenSigTimeoutTime_ECM" SG_ 2654339273 WakeupSource_FD05_SGCP 0;
BA_ "GenSigTimeoutTime_IDCM" SG_ 2654339273 WakeupSource_FD05_SGCP 0;
BA_ "GenSigTimeoutTime_MCPA" SG_ 2654339273 WakeupSource_FD05_SGCP 0;
BA_ "GenSigTimeoutTime_MCPB" SG_ 2654339273 WakeupSource_FD05_SGCP 0;
BA_ "GenSigTimeoutTime_SGCP" SG_ 2654339273 WakeupSource_FD05_SGCP 0;
BA_ "GenSigTimeoutTime_BPCM" SG_ 288 BPCM_CntctrsMidTrmOpeningWarn 0;
BA_ "GenSigTimeoutTime_ECM" SG_ 288 BPCM_CntctrsMidTrmOpeningWarn 0;
BA_ "GenSigTimeoutTime_IDCM" SG_ 288 BPCM_CntctrsMidTrmOpeningWarn 0;
BA_ "GenSigTimeoutTime_MCPA" SG_ 288 BPCM_CntctrsMidTrmOpeningWarn 0;
BA_ "GenSigTimeoutTime_MCPB" SG_ 288 BPCM_CntctrsMidTrmOpeningWarn 0;
BA_ "GenSigTimeoutTime_SGCP" SG_ 288 BPCM_CntctrsMidTrmOpeningWarn 0;
BA_ "GenSigTimeoutTime_IDCM" SG_ 288 BPCM_CntctrsShtTrmOpeningWarn 0;
BA_ "GenSigTimeoutTime_BPCM" SG_ 288 BPCM_CntctrsShtTrmOpeningWarn 0;
BA_ "GenSigTimeoutTime_ECM" SG_ 288 BPCM_CntctrsShtTrmOpeningWarn 0;
BA_ "GenSigTimeoutTime_MCPA" SG_ 288 BPCM_CntctrsShtTrmOpeningWarn 0;
BA_ "GenSigTimeoutTime_MCPB" SG_ 288 BPCM_CntctrsShtTrmOpeningWarn 0;
BA_ "GenSigTimeoutTime_SGCP" SG_ 288 BPCM_CntctrsShtTrmOpeningWarn 0;
BA_ "GenSigTimeoutTime_BPCM" SG_ 288 BPCM_HV_Cell_MaxDischrg_Imped 0;
BA_ "GenSigTimeoutTime_ECM" SG_ 288 BPCM_HV_Cell_MaxDischrg_Imped 0;
BA_ "GenSigTimeoutTime_IDCM" SG_ 288 BPCM_HV_Cell_MaxDischrg_Imped 0;
BA_ "GenSigTimeoutTime_MCPA" SG_ 288 BPCM_HV_Cell_MaxDischrg_Imped 0;
BA_ "GenSigTimeoutTime_MCPB" SG_ 288 BPCM_HV_Cell_MaxDischrg_Imped 0;
BA_ "GenSigTimeoutTime_SGCP" SG_ 288 BPCM_HV_Cell_MaxDischrg_Imped 0;
BA_ "GenSigTimeoutTime_BPCM" SG_ 288 BPCM_HV_Cell_MinDischrg_Imped 0;
BA_ "GenSigTimeoutTime_ECM" SG_ 288 BPCM_HV_Cell_MinDischrg_Imped 0;
BA_ "GenSigTimeoutTime_IDCM" SG_ 288 BPCM_HV_Cell_MinDischrg_Imped 0;
BA_ "GenSigTimeoutTime_MCPA" SG_ 288 BPCM_HV_Cell_MinDischrg_Imped 0;
BA_ "GenSigTimeoutTime_MCPB" SG_ 288 BPCM_HV_Cell_MinDischrg_Imped 0;
BA_ "GenSigTimeoutTime_SGCP" SG_ 288 BPCM_HV_Cell_MinDischrg_Imped 0;
BA_ "GenSigTimeoutTime_BPCM" SG_ 288 BPCM_HV_ChargingCurrentProfile 0;
BA_ "GenSigTimeoutTime_ECM" SG_ 288 BPCM_HV_ChargingCurrentProfile 0;
BA_ "GenSigTimeoutTime_IDCM" SG_ 288 BPCM_HV_ChargingCurrentProfile 0;
BA_ "GenSigTimeoutTime_MCPA" SG_ 288 BPCM_HV_ChargingCurrentProfile 0;
BA_ "GenSigTimeoutTime_MCPB" SG_ 288 BPCM_HV_ChargingCurrentProfile 0;
BA_ "GenSigTimeoutTime_SGCP" SG_ 288 BPCM_HV_ChargingCurrentProfile 0;
BA_ "GenSigTimeoutTime_BPCM" SG_ 288 BPCM_HV_CrntLmtInstChrg 0;
BA_ "GenSigTimeoutTime_ECM" SG_ 288 BPCM_HV_CrntLmtInstChrg 0;
BA_ "GenSigTimeoutTime_IDCM" SG_ 288 BPCM_HV_CrntLmtInstChrg 0;
BA_ "GenSigTimeoutTime_MCPA" SG_ 288 BPCM_HV_CrntLmtInstChrg 0;
BA_ "GenSigTimeoutTime_MCPB" SG_ 288 BPCM_HV_CrntLmtInstChrg 0;
BA_ "GenSigTimeoutTime_SGCP" SG_ 288 BPCM_HV_CrntLmtInstChrg 0;
BA_ "GenSigTimeoutTime_BPCM" SG_ 288 BPCM_HV_CrntLmtInstDschg 0;
BA_ "GenSigTimeoutTime_ECM" SG_ 288 BPCM_HV_CrntLmtInstDschg 0;
BA_ "GenSigTimeoutTime_IDCM" SG_ 288 BPCM_HV_CrntLmtInstDschg 0;
BA_ "GenSigTimeoutTime_MCPA" SG_ 288 BPCM_HV_CrntLmtInstDschg 0;
BA_ "GenSigTimeoutTime_MCPB" SG_ 288 BPCM_HV_CrntLmtInstDschg 0;
BA_ "GenSigTimeoutTime_SGCP" SG_ 288 BPCM_HV_CrntLmtInstDschg 0;
BA_ "GenSigTimeoutTime_BPCM" SG_ 288 BPCM_HV_Power_MaxCharge_LgTrm 0;
BA_ "GenSigTimeoutTime_ECM" SG_ 288 BPCM_HV_Power_MaxCharge_LgTrm 0;
BA_ "GenSigTimeoutTime_IDCM" SG_ 288 BPCM_HV_Power_MaxCharge_LgTrm 0;
BA_ "GenSigTimeoutTime_MCPA" SG_ 288 BPCM_HV_Power_MaxCharge_LgTrm 0;
BA_ "GenSigTimeoutTime_MCPB" SG_ 288 BPCM_HV_Power_MaxCharge_LgTrm 0;
BA_ "GenSigTimeoutTime_SGCP" SG_ 288 BPCM_HV_Power_MaxCharge_LgTrm 0;
BA_ "GenSigTimeoutTime_BPCM" SG_ 288 BPCM_HV_Power_MaxCharge_MdTrm 0;
BA_ "GenSigTimeoutTime_ECM" SG_ 288 BPCM_HV_Power_MaxCharge_MdTrm 0;
BA_ "GenSigTimeoutTime_IDCM" SG_ 288 BPCM_HV_Power_MaxCharge_MdTrm 0;
BA_ "GenSigTimeoutTime_MCPA" SG_ 288 BPCM_HV_Power_MaxCharge_MdTrm 0;
BA_ "GenSigTimeoutTime_MCPB" SG_ 288 BPCM_HV_Power_MaxCharge_MdTrm 0;
BA_ "GenSigTimeoutTime_SGCP" SG_ 288 BPCM_HV_Power_MaxCharge_MdTrm 0;
BA_ "GenSigTimeoutTime_BPCM" SG_ 288 BPCM_HV_Power_MaxCharge_ShrTrm 0;
BA_ "GenSigTimeoutTime_ECM" SG_ 288 BPCM_HV_Power_MaxCharge_ShrTrm 0;
BA_ "GenSigTimeoutTime_IDCM" SG_ 288 BPCM_HV_Power_MaxCharge_ShrTrm 0;
BA_ "GenSigTimeoutTime_MCPA" SG_ 288 BPCM_HV_Power_MaxCharge_ShrTrm 0;
BA_ "GenSigTimeoutTime_MCPB" SG_ 288 BPCM_HV_Power_MaxCharge_ShrTrm 0;
BA_ "GenSigTimeoutTime_SGCP" SG_ 288 BPCM_HV_Power_MaxCharge_ShrTrm 0;
BA_ "GenSigTimeoutTime_BPCM" SG_ 288 BPCM_HV_Power_MaxDischarge_LgTrm 0;
BA_ "GenSigTimeoutTime_ECM" SG_ 288 BPCM_HV_Power_MaxDischarge_LgTrm 0;
BA_ "GenSigTimeoutTime_IDCM" SG_ 288 BPCM_HV_Power_MaxDischarge_LgTrm 0;
BA_ "GenSigTimeoutTime_MCPA" SG_ 288 BPCM_HV_Power_MaxDischarge_LgTrm 0;
BA_ "GenSigTimeoutTime_MCPB" SG_ 288 BPCM_HV_Power_MaxDischarge_LgTrm 0;
BA_ "GenSigTimeoutTime_SGCP" SG_ 288 BPCM_HV_Power_MaxDischarge_LgTrm 0;
BA_ "GenSigTimeoutTime_BPCM" SG_ 288 BPCM_HV_Power_MaxDischarge_MdTrm 0;
BA_ "GenSigTimeoutTime_ECM" SG_ 288 BPCM_HV_Power_MaxDischarge_MdTrm 0;
BA_ "GenSigTimeoutTime_IDCM" SG_ 288 BPCM_HV_Power_MaxDischarge_MdTrm 0;
BA_ "GenSigTimeoutTime_MCPA" SG_ 288 BPCM_HV_Power_MaxDischarge_MdTrm 0;
BA_ "GenSigTimeoutTime_MCPB" SG_ 288 BPCM_HV_Power_MaxDischarge_MdTrm 0;
BA_ "GenSigTimeoutTime_SGCP" SG_ 288 BPCM_HV_Power_MaxDischarge_MdTrm 0;
BA_ "GenSigTimeoutTime_BPCM" SG_ 288 BPCM_HV_Pwr_MaxDischrg_ShrTrm 0;
BA_ "GenSigTimeoutTime_ECM" SG_ 288 BPCM_HV_Pwr_MaxDischrg_ShrTrm 0;
BA_ "GenSigTimeoutTime_IDCM" SG_ 288 BPCM_HV_Pwr_MaxDischrg_ShrTrm 0;
BA_ "GenSigTimeoutTime_MCPA" SG_ 288 BPCM_HV_Pwr_MaxDischrg_ShrTrm 0;
BA_ "GenSigTimeoutTime_MCPB" SG_ 288 BPCM_HV_Pwr_MaxDischrg_ShrTrm 0;
BA_ "GenSigTimeoutTime_SGCP" SG_ 288 BPCM_HV_Pwr_MaxDischrg_ShrTrm 0;
BA_ "GenSigTimeoutTime_BPCM" SG_ 288 BPCM_HV_PwrLmtInstChrg 0;
BA_ "GenSigTimeoutTime_ECM" SG_ 288 BPCM_HV_PwrLmtInstChrg 0;
BA_ "GenSigTimeoutTime_IDCM" SG_ 288 BPCM_HV_PwrLmtInstChrg 0;
BA_ "GenSigTimeoutTime_MCPA" SG_ 288 BPCM_HV_PwrLmtInstChrg 0;
BA_ "GenSigTimeoutTime_MCPB" SG_ 288 BPCM_HV_PwrLmtInstChrg 0;
BA_ "GenSigTimeoutTime_SGCP" SG_ 288 BPCM_HV_PwrLmtInstChrg 0;
BA_ "GenSigTimeoutTime_BPCM" SG_ 288 BPCM_HV_PwrLmtInstDschg 0;
BA_ "GenSigTimeoutTime_ECM" SG_ 288 BPCM_HV_PwrLmtInstDschg 0;
BA_ "GenSigTimeoutTime_IDCM" SG_ 288 BPCM_HV_PwrLmtInstDschg 0;
BA_ "GenSigTimeoutTime_MCPA" SG_ 288 BPCM_HV_PwrLmtInstDschg 0;
BA_ "GenSigTimeoutTime_MCPB" SG_ 288 BPCM_HV_PwrLmtInstDschg 0;
BA_ "GenSigTimeoutTime_SGCP" SG_ 288 BPCM_HV_PwrLmtInstDschg 0;
BA_ "GenSigTimeoutTime_BPCM" SG_ 485 BPCM_Cell_Volt_Avg 0;
BA_ "GenSigTimeoutTime_ECM" SG_ 485 BPCM_Cell_Volt_Avg 0;
BA_ "GenSigTimeoutTime_IDCM" SG_ 485 BPCM_Cell_Volt_Avg 0;
BA_ "GenSigTimeoutTime_MCPA" SG_ 485 BPCM_Cell_Volt_Avg 0;
BA_ "GenSigTimeoutTime_MCPB" SG_ 485 BPCM_Cell_Volt_Avg 0;
BA_ "GenSigTimeoutTime_SGCP" SG_ 485 BPCM_Cell_Volt_Avg 0;
BA_ "GenSigTimeoutTime_BPCM" SG_ 485 BPCM_OCV_Avg_Cell_Volt 0;
BA_ "GenSigTimeoutTime_ECM" SG_ 485 BPCM_OCV_Avg_Cell_Volt 0;
BA_ "GenSigTimeoutTime_IDCM" SG_ 485 BPCM_OCV_Avg_Cell_Volt 0;
BA_ "GenSigTimeoutTime_MCPA" SG_ 485 BPCM_OCV_Avg_Cell_Volt 0;
BA_ "GenSigTimeoutTime_MCPB" SG_ 485 BPCM_OCV_Avg_Cell_Volt 0;
BA_ "GenSigTimeoutTime_SGCP" SG_ 485 BPCM_OCV_Avg_Cell_Volt 0;
BA_ "GenSigTimeoutTime_BPCM" SG_ 485 BPCM_Min_Cell_Volt_Allowed 0;
BA_ "GenSigTimeoutTime_ECM" SG_ 485 BPCM_Min_Cell_Volt_Allowed 0;
BA_ "GenSigTimeoutTime_IDCM" SG_ 485 BPCM_Min_Cell_Volt_Allowed 0;
BA_ "GenSigTimeoutTime_MCPA" SG_ 485 BPCM_Min_Cell_Volt_Allowed 0;
BA_ "GenSigTimeoutTime_MCPB" SG_ 485 BPCM_Min_Cell_Volt_Allowed 0;
BA_ "GenSigTimeoutTime_SGCP" SG_ 485 BPCM_Min_Cell_Volt_Allowed 0;
BA_ "GenSigTimeoutTime_MCPB" SG_ 485 BPCM_OCV_Max_Cell_Volt 0;
BA_ "GenSigTimeoutTime_SGCP" SG_ 485 BPCM_OCV_Max_Cell_Volt 0;
BA_ "GenSigTimeoutTime_BPCM" SG_ 485 BPCM_OCV_Max_Cell_Volt 0;
BA_ "GenSigTimeoutTime_ECM" SG_ 485 BPCM_OCV_Max_Cell_Volt 0;
BA_ "GenSigTimeoutTime_IDCM" SG_ 485 BPCM_OCV_Max_Cell_Volt 0;
BA_ "GenSigTimeoutTime_MCPA" SG_ 485 BPCM_OCV_Max_Cell_Volt 0;
BA_ "GenSigTimeoutTime_BPCM" SG_ 485 BPCM_OCV_Min_Cell_Volt 0;
BA_ "GenSigTimeoutTime_ECM" SG_ 485 BPCM_OCV_Min_Cell_Volt 0;
BA_ "GenSigTimeoutTime_IDCM" SG_ 485 BPCM_OCV_Min_Cell_Volt 0;
BA_ "GenSigTimeoutTime_MCPA" SG_ 485 BPCM_OCV_Min_Cell_Volt 0;
BA_ "GenSigTimeoutTime_MCPB" SG_ 485 BPCM_OCV_Min_Cell_Volt 0;
BA_ "GenSigTimeoutTime_SGCP" SG_ 485 BPCM_OCV_Min_Cell_Volt 0;
BA_ "GenSigTimeoutTime_BPCM" SG_ 288 BPCM_HV_HVBatChargeStat 0;
BA_ "GenSigTimeoutTime_ECM" SG_ 288 BPCM_HV_HVBatChargeStat 0;
BA_ "GenSigTimeoutTime_IDCM" SG_ 288 BPCM_HV_HVBatChargeStat 0;
BA_ "GenSigTimeoutTime_MCPA" SG_ 288 BPCM_HV_HVBatChargeStat 0;
BA_ "GenSigTimeoutTime_MCPB" SG_ 288 BPCM_HV_HVBatChargeStat 0;
BA_ "GenSigTimeoutTime_SGCP" SG_ 288 BPCM_HV_HVBatChargeStat 0;
BA_ "GenSigTimeoutTime_BPCM" SG_ 485 BPCM_Max_Pk_Volt_Allowed 0;
BA_ "GenSigTimeoutTime_ECM" SG_ 485 BPCM_Max_Pk_Volt_Allowed 0;
BA_ "GenSigTimeoutTime_IDCM" SG_ 485 BPCM_Max_Pk_Volt_Allowed 0;
BA_ "GenSigTimeoutTime_MCPA" SG_ 485 BPCM_Max_Pk_Volt_Allowed 0;
BA_ "GenSigTimeoutTime_MCPB" SG_ 485 BPCM_Max_Pk_Volt_Allowed 0;
BA_ "GenSigTimeoutTime_SGCP" SG_ 485 BPCM_Max_Pk_Volt_Allowed 0;
BA_ "GenSigTimeoutTime_BPCM" SG_ 485 BPCM_Min_Pk_Volt_Allowed 0;
BA_ "GenSigTimeoutTime_ECM" SG_ 485 BPCM_Min_Pk_Volt_Allowed 0;
BA_ "GenSigTimeoutTime_IDCM" SG_ 485 BPCM_Min_Pk_Volt_Allowed 0;
BA_ "GenSigTimeoutTime_MCPA" SG_ 485 BPCM_Min_Pk_Volt_Allowed 0;
BA_ "GenSigTimeoutTime_MCPB" SG_ 485 BPCM_Min_Pk_Volt_Allowed 0;
BA_ "GenSigTimeoutTime_SGCP" SG_ 485 BPCM_Min_Pk_Volt_Allowed 0;
BA_ "GenSigTimeoutTime_BPCM" SG_ 485 BPCM_HV_NumCellMaxVolt 0;
BA_ "GenSigTimeoutTime_ECM" SG_ 485 BPCM_HV_NumCellMaxVolt 0;
BA_ "GenSigTimeoutTime_IDCM" SG_ 485 BPCM_HV_NumCellMaxVolt 0;
BA_ "GenSigTimeoutTime_MCPA" SG_ 485 BPCM_HV_NumCellMaxVolt 0;
BA_ "GenSigTimeoutTime_MCPB" SG_ 485 BPCM_HV_NumCellMaxVolt 0;
BA_ "GenSigTimeoutTime_SGCP" SG_ 485 BPCM_HV_NumCellMaxVolt 0;
BA_ "GenSigTimeoutTime_BPCM" SG_ 485 BPCM_HV_NumCellMinVolt 0;
BA_ "GenSigTimeoutTime_ECM" SG_ 485 BPCM_HV_NumCellMinVolt 0;
BA_ "GenSigTimeoutTime_IDCM" SG_ 485 BPCM_HV_NumCellMinVolt 0;
BA_ "GenSigTimeoutTime_MCPA" SG_ 485 BPCM_HV_NumCellMinVolt 0;
BA_ "GenSigTimeoutTime_MCPB" SG_ 485 BPCM_HV_NumCellMinVolt 0;
BA_ "GenSigTimeoutTime_SGCP" SG_ 485 BPCM_HV_NumCellMinVolt 0;
BA_ "GenSigTimeoutTime_BPCM" SG_ 485 BPCM_HV_NumCellMaxTemp 0;
BA_ "GenSigTimeoutTime_ECM" SG_ 485 BPCM_HV_NumCellMaxTemp 0;
BA_ "GenSigTimeoutTime_IDCM" SG_ 485 BPCM_HV_NumCellMaxTemp 0;
BA_ "GenSigTimeoutTime_MCPA" SG_ 485 BPCM_HV_NumCellMaxTemp 0;
BA_ "GenSigTimeoutTime_MCPB" SG_ 485 BPCM_HV_NumCellMaxTemp 0;
BA_ "GenSigTimeoutTime_SGCP" SG_ 485 BPCM_HV_NumCellMaxTemp 0;
BA_ "GenSigTimeoutTime_BPCM" SG_ 485 BPCM_HV_NumCellMinTemp 0;
BA_ "GenSigTimeoutTime_ECM" SG_ 485 BPCM_HV_NumCellMinTemp 0;
BA_ "GenSigTimeoutTime_IDCM" SG_ 485 BPCM_HV_NumCellMinTemp 0;
BA_ "GenSigTimeoutTime_MCPA" SG_ 485 BPCM_HV_NumCellMinTemp 0;
BA_ "GenSigTimeoutTime_MCPB" SG_ 485 BPCM_HV_NumCellMinTemp 0;
BA_ "GenSigTimeoutTime_SGCP" SG_ 485 BPCM_HV_NumCellMinTemp 0;
BA_ "GenSigTimeoutTime_BPCM" SG_ 485 CRC_BATT_HV_VLIMITS 0;
BA_ "GenSigTimeoutTime_ECM" SG_ 485 CRC_BATT_HV_VLIMITS 0;
BA_ "GenSigTimeoutTime_IDCM" SG_ 485 CRC_BATT_HV_VLIMITS 0;
BA_ "GenSigTimeoutTime_MCPA" SG_ 485 CRC_BATT_HV_VLIMITS 0;
BA_ "GenSigTimeoutTime_MCPB" SG_ 485 CRC_BATT_HV_VLIMITS 0;
BA_ "GenSigTimeoutTime_SGCP" SG_ 485 CRC_BATT_HV_VLIMITS 0;
BA_ "GenSigTimeoutTime_BPCM" SG_ 485 MessageCounter_BATT_HV_VLIMITS 0;
BA_ "GenSigTimeoutTime_ECM" SG_ 485 MessageCounter_BATT_HV_VLIMITS 0;
BA_ "GenSigTimeoutTime_IDCM" SG_ 485 MessageCounter_BATT_HV_VLIMITS 0;
BA_ "GenSigTimeoutTime_MCPA" SG_ 485 MessageCounter_BATT_HV_VLIMITS 0;
BA_ "GenSigTimeoutTime_MCPB" SG_ 485 MessageCounter_BATT_HV_VLIMITS 0;
BA_ "GenSigTimeoutTime_SGCP" SG_ 485 MessageCounter_BATT_HV_VLIMITS 0;
BA_ "GenSigTimeoutTime_BPCM" SG_ 1057 CRC_MCPA_OBD_DTC 0;
BA_ "GenSigTimeoutTime_ECM" SG_ 1057 CRC_MCPA_OBD_DTC 0;
BA_ "GenSigTimeoutTime_IDCM" SG_ 1057 CRC_MCPA_OBD_DTC 0;
BA_ "GenSigTimeoutTime_MCPA" SG_ 1057 CRC_MCPA_OBD_DTC 0;
BA_ "GenSigTimeoutTime_MCPB" SG_ 1057 CRC_MCPA_OBD_DTC 0;
BA_ "GenSigTimeoutTime_SGCP" SG_ 1057 CRC_MCPA_OBD_DTC 0;
BA_ "GenSigTimeoutTime_BPCM" SG_ 1057 MCPA_Cal_ID_Idx 0;
BA_ "GenSigTimeoutTime_ECM" SG_ 1057 MCPA_Cal_ID_Idx 0;
BA_ "GenSigTimeoutTime_IDCM" SG_ 1057 MCPA_Cal_ID_Idx 0;
BA_ "GenSigTimeoutTime_MCPA" SG_ 1057 MCPA_Cal_ID_Idx 0;
BA_ "GenSigTimeoutTime_MCPB" SG_ 1057 MCPA_Cal_ID_Idx 0;
BA_ "GenSigTimeoutTime_SGCP" SG_ 1057 MCPA_Cal_ID_Idx 0;
BA_ "GenSigTimeoutTime_BPCM" SG_ 1057 MCPA_CalChar 0;
BA_ "GenSigTimeoutTime_ECM" SG_ 1057 MCPA_CalChar 0;
BA_ "GenSigTimeoutTime_IDCM" SG_ 1057 MCPA_CalChar 0;
BA_ "GenSigTimeoutTime_MCPA" SG_ 1057 MCPA_CalChar 0;
BA_ "GenSigTimeoutTime_MCPB" SG_ 1057 MCPA_CalChar 0;
BA_ "GenSigTimeoutTime_SGCP" SG_ 1057 MCPA_CalChar 0;
BA_ "GenSigTimeoutTime_BPCM" SG_ 1057 MCPA_DTC_Idx1 0;
BA_ "GenSigTimeoutTime_ECM" SG_ 1057 MCPA_DTC_Idx1 0;
BA_ "GenSigTimeoutTime_IDCM" SG_ 1057 MCPA_DTC_Idx1 0;
BA_ "GenSigTimeoutTime_MCPA" SG_ 1057 MCPA_DTC_Idx1 0;
BA_ "GenSigTimeoutTime_MCPB" SG_ 1057 MCPA_DTC_Idx1 0;
BA_ "GenSigTimeoutTime_SGCP" SG_ 1057 MCPA_DTC_Idx1 0;
BA_ "GenSigTimeoutTime_BPCM" SG_ 1057 MCPA_DTC_Idx2 0;
BA_ "GenSigTimeoutTime_ECM" SG_ 1057 MCPA_DTC_Idx2 0;
BA_ "GenSigTimeoutTime_IDCM" SG_ 1057 MCPA_DTC_Idx2 0;
BA_ "GenSigTimeoutTime_MCPA" SG_ 1057 MCPA_DTC_Idx2 0;
BA_ "GenSigTimeoutTime_MCPB" SG_ 1057 MCPA_DTC_Idx2 0;
BA_ "GenSigTimeoutTime_SGCP" SG_ 1057 MCPA_DTC_Idx2 0;
BA_ "GenSigTimeoutTime_BPCM" SG_ 1057 MCPA_DTC_Stat1 0;
BA_ "GenSigTimeoutTime_ECM" SG_ 1057 MCPA_DTC_Stat1 0;
BA_ "GenSigTimeoutTime_IDCM" SG_ 1057 MCPA_DTC_Stat1 0;
BA_ "GenSigTimeoutTime_MCPA" SG_ 1057 MCPA_DTC_Stat1 0;
BA_ "GenSigTimeoutTime_MCPB" SG_ 1057 MCPA_DTC_Stat1 0;
BA_ "GenSigTimeoutTime_SGCP" SG_ 1057 MCPA_DTC_Stat1 0;
BA_ "GenSigTimeoutTime_BPCM" SG_ 1057 MCPA_DTC_Stat2 0;
BA_ "GenSigTimeoutTime_ECM" SG_ 1057 MCPA_DTC_Stat2 0;
BA_ "GenSigTimeoutTime_IDCM" SG_ 1057 MCPA_DTC_Stat2 0;
BA_ "GenSigTimeoutTime_MCPA" SG_ 1057 MCPA_DTC_Stat2 0;
BA_ "GenSigTimeoutTime_MCPB" SG_ 1057 MCPA_DTC_Stat2 0;
BA_ "GenSigTimeoutTime_SGCP" SG_ 1057 MCPA_DTC_Stat2 0;
BA_ "GenSigTimeoutTime_BPCM" SG_ 1057 MessageCounter_MCPA_OBD_DTC 0;
BA_ "GenSigTimeoutTime_ECM" SG_ 1057 MessageCounter_MCPA_OBD_DTC 0;
BA_ "GenSigTimeoutTime_IDCM" SG_ 1057 MessageCounter_MCPA_OBD_DTC 0;
BA_ "GenSigTimeoutTime_MCPA" SG_ 1057 MessageCounter_MCPA_OBD_DTC 0;
BA_ "GenSigTimeoutTime_MCPB" SG_ 1057 MessageCounter_MCPA_OBD_DTC 0;
BA_ "GenSigTimeoutTime_SGCP" SG_ 1057 MessageCounter_MCPA_OBD_DTC 0;
BA_ "GenSigTimeoutTime_BPCM" SG_ 1065 CRC_MCPB_OBD_DTC 0;
BA_ "GenSigTimeoutTime_ECM" SG_ 1065 CRC_MCPB_OBD_DTC 0;
BA_ "GenSigTimeoutTime_IDCM" SG_ 1065 CRC_MCPB_OBD_DTC 0;
BA_ "GenSigTimeoutTime_MCPA" SG_ 1065 CRC_MCPB_OBD_DTC 0;
BA_ "GenSigTimeoutTime_MCPB" SG_ 1065 CRC_MCPB_OBD_DTC 0;
BA_ "GenSigTimeoutTime_SGCP" SG_ 1065 CRC_MCPB_OBD_DTC 0;
BA_ "GenSigTimeoutTime_BPCM" SG_ 1065 MCPB_Cal_ID_Idx 0;
BA_ "GenSigTimeoutTime_ECM" SG_ 1065 MCPB_Cal_ID_Idx 0;
BA_ "GenSigTimeoutTime_IDCM" SG_ 1065 MCPB_Cal_ID_Idx 0;
BA_ "GenSigTimeoutTime_MCPA" SG_ 1065 MCPB_Cal_ID_Idx 0;
BA_ "GenSigTimeoutTime_MCPB" SG_ 1065 MCPB_Cal_ID_Idx 0;
BA_ "GenSigTimeoutTime_SGCP" SG_ 1065 MCPB_Cal_ID_Idx 0;
BA_ "GenSigTimeoutTime_BPCM" SG_ 1065 MCPB_CalChar 0;
BA_ "GenSigTimeoutTime_ECM" SG_ 1065 MCPB_CalChar 0;
BA_ "GenSigTimeoutTime_IDCM" SG_ 1065 MCPB_CalChar 0;
BA_ "GenSigTimeoutTime_MCPA" SG_ 1065 MCPB_CalChar 0;
BA_ "GenSigTimeoutTime_MCPB" SG_ 1065 MCPB_CalChar 0;
BA_ "GenSigTimeoutTime_SGCP" SG_ 1065 MCPB_CalChar 0;
BA_ "GenSigTimeoutTime_BPCM" SG_ 1065 MCPB_DTC_Idx1 0;
BA_ "GenSigTimeoutTime_ECM" SG_ 1065 MCPB_DTC_Idx1 0;
BA_ "GenSigTimeoutTime_IDCM" SG_ 1065 MCPB_DTC_Idx1 0;
BA_ "GenSigTimeoutTime_MCPA" SG_ 1065 MCPB_DTC_Idx1 0;
BA_ "GenSigTimeoutTime_MCPB" SG_ 1065 MCPB_DTC_Idx1 0;
BA_ "GenSigTimeoutTime_SGCP" SG_ 1065 MCPB_DTC_Idx1 0;
BA_ "GenSigTimeoutTime_BPCM" SG_ 1065 MessageCounter_MCPB_OBD_DTC 0;
BA_ "GenSigTimeoutTime_ECM" SG_ 1065 MessageCounter_MCPB_OBD_DTC 0;
BA_ "GenSigTimeoutTime_IDCM" SG_ 1065 MessageCounter_MCPB_OBD_DTC 0;
BA_ "GenSigTimeoutTime_MCPA" SG_ 1065 MessageCounter_MCPB_OBD_DTC 0;
BA_ "GenSigTimeoutTime_MCPB" SG_ 1065 MessageCounter_MCPB_OBD_DTC 0;
BA_ "GenSigTimeoutTime_SGCP" SG_ 1065 MessageCounter_MCPB_OBD_DTC 0;
BA_ "GenSigTimeoutTime_BPCM" SG_ 1065 MCPB_DTC_Stat2 0;
BA_ "GenSigTimeoutTime_ECM" SG_ 1065 MCPB_DTC_Stat2 0;
BA_ "GenSigTimeoutTime_IDCM" SG_ 1065 MCPB_DTC_Stat2 0;
BA_ "GenSigTimeoutTime_MCPA" SG_ 1065 MCPB_DTC_Stat2 0;
BA_ "GenSigTimeoutTime_MCPB" SG_ 1065 MCPB_DTC_Stat2 0;
BA_ "GenSigTimeoutTime_SGCP" SG_ 1065 MCPB_DTC_Stat2 0;
BA_ "GenSigTimeoutTime_IDCM" SG_ 1065 MCPB_DTC_Idx2 0;
BA_ "GenSigTimeoutTime_MCPA" SG_ 1065 MCPB_DTC_Idx2 0;
BA_ "GenSigTimeoutTime_MCPB" SG_ 1065 MCPB_DTC_Idx2 0;
BA_ "GenSigTimeoutTime_SGCP" SG_ 1065 MCPB_DTC_Idx2 0;
BA_ "GenSigTimeoutTime_BPCM" SG_ 1065 MCPB_DTC_Idx2 0;
BA_ "GenSigTimeoutTime_ECM" SG_ 1065 MCPB_DTC_Idx2 0;
BA_ "GenSigTimeoutTime_BPCM" SG_ 1065 MCPB_DTC_Stat1 0;
BA_ "GenSigTimeoutTime_ECM" SG_ 1065 MCPB_DTC_Stat1 0;
BA_ "GenSigTimeoutTime_IDCM" SG_ 1065 MCPB_DTC_Stat1 0;
BA_ "GenSigTimeoutTime_MCPA" SG_ 1065 MCPB_DTC_Stat1 0;
BA_ "GenSigTimeoutTime_MCPB" SG_ 1065 MCPB_DTC_Stat1 0;
BA_ "GenSigTimeoutTime_SGCP" SG_ 1065 MCPB_DTC_Stat1 0;
BA_ "GenSigTimeoutTime_BPCM" SG_ 1070 CRC_SGCP_OBD_DTC 0;
BA_ "GenSigTimeoutTime_ECM" SG_ 1070 CRC_SGCP_OBD_DTC 0;
BA_ "GenSigTimeoutTime_IDCM" SG_ 1070 CRC_SGCP_OBD_DTC 0;
BA_ "GenSigTimeoutTime_MCPA" SG_ 1070 CRC_SGCP_OBD_DTC 0;
BA_ "GenSigTimeoutTime_MCPB" SG_ 1070 CRC_SGCP_OBD_DTC 0;
BA_ "GenSigTimeoutTime_SGCP" SG_ 1070 CRC_SGCP_OBD_DTC 0;
BA_ "GenSigTimeoutTime_BPCM" SG_ 1070 MessageCounter_SGCP_OBD_DTC 0;
BA_ "GenSigTimeoutTime_ECM" SG_ 1070 MessageCounter_SGCP_OBD_DTC 0;
BA_ "GenSigTimeoutTime_IDCM" SG_ 1070 MessageCounter_SGCP_OBD_DTC 0;
BA_ "GenSigTimeoutTime_MCPA" SG_ 1070 MessageCounter_SGCP_OBD_DTC 0;
BA_ "GenSigTimeoutTime_MCPB" SG_ 1070 MessageCounter_SGCP_OBD_DTC 0;
BA_ "GenSigTimeoutTime_SGCP" SG_ 1070 MessageCounter_SGCP_OBD_DTC 0;
BA_ "GenSigTimeoutTime_BPCM" SG_ 1070 SGCP_Cal_ID_Idx 0;
BA_ "GenSigTimeoutTime_ECM" SG_ 1070 SGCP_Cal_ID_Idx 0;
BA_ "GenSigTimeoutTime_IDCM" SG_ 1070 SGCP_Cal_ID_Idx 0;
BA_ "GenSigTimeoutTime_MCPA" SG_ 1070 SGCP_Cal_ID_Idx 0;
BA_ "GenSigTimeoutTime_MCPB" SG_ 1070 SGCP_Cal_ID_Idx 0;
BA_ "GenSigTimeoutTime_SGCP" SG_ 1070 SGCP_Cal_ID_Idx 0;
BA_ "GenSigTimeoutTime_BPCM" SG_ 1070 SGCP_CalChar 0;
BA_ "GenSigTimeoutTime_ECM" SG_ 1070 SGCP_CalChar 0;
BA_ "GenSigTimeoutTime_IDCM" SG_ 1070 SGCP_CalChar 0;
BA_ "GenSigTimeoutTime_MCPA" SG_ 1070 SGCP_CalChar 0;
BA_ "GenSigTimeoutTime_MCPB" SG_ 1070 SGCP_CalChar 0;
BA_ "GenSigTimeoutTime_SGCP" SG_ 1070 SGCP_CalChar 0;
BA_ "GenSigTimeoutTime_BPCM" SG_ 1070 SGCP_DTC_Idx1 0;
BA_ "GenSigTimeoutTime_ECM" SG_ 1070 SGCP_DTC_Idx1 0;
BA_ "GenSigTimeoutTime_IDCM" SG_ 1070 SGCP_DTC_Idx1 0;
BA_ "GenSigTimeoutTime_MCPA" SG_ 1070 SGCP_DTC_Idx1 0;
BA_ "GenSigTimeoutTime_MCPB" SG_ 1070 SGCP_DTC_Idx1 0;
BA_ "GenSigTimeoutTime_SGCP" SG_ 1070 SGCP_DTC_Idx1 0;
BA_ "GenSigTimeoutTime_BPCM" SG_ 1070 SGCP_DTC_Idx2 0;
BA_ "GenSigTimeoutTime_ECM" SG_ 1070 SGCP_DTC_Idx2 0;
BA_ "GenSigTimeoutTime_IDCM" SG_ 1070 SGCP_DTC_Idx2 0;
BA_ "GenSigTimeoutTime_MCPA" SG_ 1070 SGCP_DTC_Idx2 0;
BA_ "GenSigTimeoutTime_MCPB" SG_ 1070 SGCP_DTC_Idx2 0;
BA_ "GenSigTimeoutTime_SGCP" SG_ 1070 SGCP_DTC_Idx2 0;
BA_ "GenSigTimeoutTime_BPCM" SG_ 1070 SGCP_DTC_Stat1 0;
BA_ "GenSigTimeoutTime_ECM" SG_ 1070 SGCP_DTC_Stat1 0;
BA_ "GenSigTimeoutTime_IDCM" SG_ 1070 SGCP_DTC_Stat1 0;
BA_ "GenSigTimeoutTime_MCPA" SG_ 1070 SGCP_DTC_Stat1 0;
BA_ "GenSigTimeoutTime_MCPB" SG_ 1070 SGCP_DTC_Stat1 0;
BA_ "GenSigTimeoutTime_SGCP" SG_ 1070 SGCP_DTC_Stat1 0;
BA_ "GenSigTimeoutTime_BPCM" SG_ 1070 SGCP_DTC_Stat2 0;
BA_ "GenSigTimeoutTime_ECM" SG_ 1070 SGCP_DTC_Stat2 0;
BA_ "GenSigTimeoutTime_IDCM" SG_ 1070 SGCP_DTC_Stat2 0;
BA_ "GenSigTimeoutTime_MCPA" SG_ 1070 SGCP_DTC_Stat2 0;
BA_ "GenSigTimeoutTime_MCPB" SG_ 1070 SGCP_DTC_Stat2 0;
BA_ "GenSigTimeoutTime_SGCP" SG_ 1070 SGCP_DTC_Stat2 0;
BA_ "GenSigTimeoutTime_ECM" SG_ 216 EVCU_Resp_AUX_LoadTurned_Off 0;
BA_ "GenSigTimeoutTime_EVCU2" SG_ 216 EVCU_Resp_AUX_LoadTurned_Off 0;
BA_ "GenSigTimeoutTime_IDCM" SG_ 216 EVCU_Resp_AUX_LoadTurned_Off 0;
BA_ "GenSigTimeoutTime_MCPA" SG_ 216 EVCU_Resp_AUX_LoadTurned_Off 0;
BA_ "GenSigTimeoutTime_MCPB" SG_ 216 EVCU_Resp_AUX_LoadTurned_Off 0;
BA_ "GenSigTimeoutTime_SGCP" SG_ 216 EVCU_Resp_AUX_LoadTurned_Off 0;
BA_ "GenSigTimeoutTime_ECM" SG_ 216 DC_Charge_Type_Command 0;
BA_ "GenSigTimeoutTime_EVCU2" SG_ 216 DC_Charge_Type_Command 0;
BA_ "GenSigTimeoutTime_IDCM" SG_ 216 DC_Charge_Type_Command 0;
BA_ "GenSigTimeoutTime_MCPA" SG_ 216 DC_Charge_Type_Command 0;
BA_ "GenSigTimeoutTime_MCPB" SG_ 216 DC_Charge_Type_Command 0;
BA_ "GenSigTimeoutTime_SGCP" SG_ 216 DC_Charge_Type_Command 0;
BA_ "GenSigTimeoutTime_BPCM" SG_ 2654486592 CBV_bit2_1E384040 0;
BA_ "GenSigTimeoutTime_ECM" SG_ 2654486592 CBV_bit2_1E384040 0;
BA_ "GenSigTimeoutTime_EVCU2" SG_ 2654486592 CBV_bit2_1E384040 0;
BA_ "GenSigTimeoutTime_IDCM" SG_ 2654486592 CBV_bit2_1E384040 0;
BA_ "GenSigTimeoutTime_MCPA" SG_ 2654486592 CBV_bit2_1E384040 0;
BA_ "GenSigTimeoutTime_MCPB" SG_ 2654486592 CBV_bit2_1E384040 0;
BA_ "GenSigTimeoutTime_SGCP" SG_ 2654486592 CBV_bit2_1E384040 0;
BA_ "GenSigTimeoutTime_BPCM" SG_ 2654486592 CBV_bit3_NMCoordinatorBit_1E384040 0;
BA_ "GenSigTimeoutTime_ECM" SG_ 2654486592 CBV_bit3_NMCoordinatorBit_1E384040 0;
BA_ "GenSigTimeoutTime_EVCU2" SG_ 2654486592 CBV_bit3_NMCoordinatorBit_1E384040 0;
BA_ "GenSigTimeoutTime_IDCM" SG_ 2654486592 CBV_bit3_NMCoordinatorBit_1E384040 0;
BA_ "GenSigTimeoutTime_MCPA" SG_ 2654486592 CBV_bit3_NMCoordinatorBit_1E384040 0;
BA_ "GenSigTimeoutTime_MCPB" SG_ 2654486592 CBV_bit3_NMCoordinatorBit_1E384040 0;
BA_ "GenSigTimeoutTime_SGCP" SG_ 2654486592 CBV_bit3_NMCoordinatorBit_1E384040 0;
BA_ "GenSigTimeoutTime_BPCM" SG_ 2654486592 CBV_bit5_1E384040 0;
BA_ "GenSigTimeoutTime_ECM" SG_ 2654486592 CBV_bit5_1E384040 0;
BA_ "GenSigTimeoutTime_EVCU2" SG_ 2654486592 CBV_bit5_1E384040 0;
BA_ "GenSigTimeoutTime_IDCM" SG_ 2654486592 CBV_bit5_1E384040 0;
BA_ "GenSigTimeoutTime_MCPA" SG_ 2654486592 CBV_bit5_1E384040 0;
BA_ "GenSigTimeoutTime_MCPB" SG_ 2654486592 CBV_bit5_1E384040 0;
BA_ "GenSigTimeoutTime_SGCP" SG_ 2654486592 CBV_bit5_1E384040 0;
BA_ "GenSigTimeoutTime_BPCM" SG_ 2654486592 CBV_bit4_ActiveWakeupBit_1E384040 0;
BA_ "GenSigTimeoutTime_ECM" SG_ 2654486592 CBV_bit4_ActiveWakeupBit_1E384040 0;
BA_ "GenSigTimeoutTime_EVCU2" SG_ 2654486592 CBV_bit4_ActiveWakeupBit_1E384040 0;
BA_ "GenSigTimeoutTime_IDCM" SG_ 2654486592 CBV_bit4_ActiveWakeupBit_1E384040 0;
BA_ "GenSigTimeoutTime_MCPA" SG_ 2654486592 CBV_bit4_ActiveWakeupBit_1E384040 0;
BA_ "GenSigTimeoutTime_MCPB" SG_ 2654486592 CBV_bit4_ActiveWakeupBit_1E384040 0;
BA_ "GenSigTimeoutTime_SGCP" SG_ 2654486592 CBV_bit4_ActiveWakeupBit_1E384040 0;
BA_ "GenSigTimeoutTime_BPCM" SG_ 2654486592 SourceNodeIdentifier_1E384040 0;
BA_ "GenSigTimeoutTime_ECM" SG_ 2654486592 SourceNodeIdentifier_1E384040 0;
BA_ "GenSigTimeoutTime_EVCU2" SG_ 2654486592 SourceNodeIdentifier_1E384040 0;
BA_ "GenSigTimeoutTime_IDCM" SG_ 2654486592 SourceNodeIdentifier_1E384040 0;
BA_ "GenSigTimeoutTime_MCPA" SG_ 2654486592 SourceNodeIdentifier_1E384040 0;
BA_ "GenSigTimeoutTime_MCPB" SG_ 2654486592 SourceNodeIdentifier_1E384040 0;
BA_ "GenSigTimeoutTime_SGCP" SG_ 2654486592 SourceNodeIdentifier_1E384040 0;
BA_ "GenSigTimeoutTime_BPCM" SG_ 2654486592 CBV_bit1_1E384040 0;
BA_ "GenSigTimeoutTime_ECM" SG_ 2654486592 CBV_bit1_1E384040 0;
BA_ "GenSigTimeoutTime_EVCU2" SG_ 2654486592 CBV_bit1_1E384040 0;
BA_ "GenSigTimeoutTime_IDCM" SG_ 2654486592 CBV_bit1_1E384040 0;
BA_ "GenSigTimeoutTime_MCPA" SG_ 2654486592 CBV_bit1_1E384040 0;
BA_ "GenSigTimeoutTime_MCPB" SG_ 2654486592 CBV_bit1_1E384040 0;
BA_ "GenSigTimeoutTime_SGCP" SG_ 2654486592 CBV_bit1_1E384040 0;
BA_ "GenSigTimeoutTime_BPCM" SG_ 2654486592 CBV_bit0_RepeatMessageRequestBit_1E384040 0;
BA_ "GenSigTimeoutTime_ECM" SG_ 2654486592 CBV_bit0_RepeatMessageRequestBit_1E384040 0;
BA_ "GenSigTimeoutTime_EVCU2" SG_ 2654486592 CBV_bit0_RepeatMessageRequestBit_1E384040 0;
BA_ "GenSigTimeoutTime_IDCM" SG_ 2654486592 CBV_bit0_RepeatMessageRequestBit_1E384040 0;
BA_ "GenSigTimeoutTime_MCPA" SG_ 2654486592 CBV_bit0_RepeatMessageRequestBit_1E384040 0;
BA_ "GenSigTimeoutTime_MCPB" SG_ 2654486592 CBV_bit0_RepeatMessageRequestBit_1E384040 0;
BA_ "GenSigTimeoutTime_SGCP" SG_ 2654486592 CBV_bit0_RepeatMessageRequestBit_1E384040 0;
BA_ "GenSigTimeoutTime_BPCM" SG_ 2654486592 CBV_bit7_1E384040 0;
BA_ "GenSigTimeoutTime_ECM" SG_ 2654486592 CBV_bit7_1E384040 0;
BA_ "GenSigTimeoutTime_EVCU2" SG_ 2654486592 CBV_bit7_1E384040 0;
BA_ "GenSigTimeoutTime_IDCM" SG_ 2654486592 CBV_bit7_1E384040 0;
BA_ "GenSigTimeoutTime_MCPA" SG_ 2654486592 CBV_bit7_1E384040 0;
BA_ "GenSigTimeoutTime_MCPB" SG_ 2654486592 CBV_bit7_1E384040 0;
BA_ "GenSigTimeoutTime_SGCP" SG_ 2654486592 CBV_bit7_1E384040 0;
BA_ "GenSigTimeoutTime_BPCM" SG_ 2654486592 CBV_bit6_PartialNtwInfBit_1E384040 0;
BA_ "GenSigTimeoutTime_ECM" SG_ 2654486592 CBV_bit6_PartialNtwInfBit_1E384040 0;
BA_ "GenSigTimeoutTime_EVCU2" SG_ 2654486592 CBV_bit6_PartialNtwInfBit_1E384040 0;
BA_ "GenSigTimeoutTime_IDCM" SG_ 2654486592 CBV_bit6_PartialNtwInfBit_1E384040 0;
BA_ "GenSigTimeoutTime_MCPA" SG_ 2654486592 CBV_bit6_PartialNtwInfBit_1E384040 0;
BA_ "GenSigTimeoutTime_MCPB" SG_ 2654486592 CBV_bit6_PartialNtwInfBit_1E384040 0;
BA_ "GenSigTimeoutTime_SGCP" SG_ 2654486592 CBV_bit6_PartialNtwInfBit_1E384040 0;
BA_ "GenSigTimeoutTime_BPCM" SG_ 2564455444 N_PDU_18DA7C14 0;
BA_ "GenSigTimeoutTime_ECM" SG_ 2564455444 N_PDU_18DA7C14 0;
BA_ "GenSigTimeoutTime_EVCU2" SG_ 2564455444 N_PDU_18DA7C14 0;
BA_ "GenSigTimeoutTime_IDCM" SG_ 2564455444 N_PDU_18DA7C14 0;
BA_ "GenSigTimeoutTime_MCPA" SG_ 2564455444 N_PDU_18DA7C14 0;
BA_ "GenSigTimeoutTime_MCPB" SG_ 2564455444 N_PDU_18DA7C14 0;
BA_ "GenSigTimeoutTime_SGCP" SG_ 2564455444 N_PDU_18DA7C14 0;
BA_ "GenSigTimeoutTime_BPCM" SG_ 2564455669 N_PDU_18DA7CF5 0;
BA_ "GenSigTimeoutTime_ECM" SG_ 2564455669 N_PDU_18DA7CF5 0;
BA_ "GenSigTimeoutTime_EVCU2" SG_ 2564455669 N_PDU_18DA7CF5 0;
BA_ "GenSigTimeoutTime_IDCM" SG_ 2564455669 N_PDU_18DA7CF5 0;
BA_ "GenSigTimeoutTime_MCPA" SG_ 2564455669 N_PDU_18DA7CF5 0;
BA_ "GenSigTimeoutTime_MCPB" SG_ 2564455669 N_PDU_18DA7CF5 0;
BA_ "GenSigTimeoutTime_SGCP" SG_ 2564455669 N_PDU_18DA7CF5 0;
BA_ "GenSigTimeoutTime_BPCM" SG_ 1046 V2H_HVCMS_EVSEMaxPowerLimit 0;
BA_ "GenSigTimeoutTime_ECM" SG_ 1046 V2H_HVCMS_EVSEMaxPowerLimit 0;
BA_ "GenSigTimeoutTime_IDCM" SG_ 1046 V2H_HVCMS_EVSEMaxPowerLimit 0;
BA_ "GenSigTimeoutTime_MCPA" SG_ 1046 V2H_HVCMS_EVSEMaxPowerLimit 0;
BA_ "GenSigTimeoutTime_MCPB" SG_ 1046 V2H_HVCMS_EVSEMaxPowerLimit 0;
BA_ "GenSigTimeoutTime_SGCP" SG_ 1046 V2H_HVCMS_EVSEMaxPowerLimit 0;
BA_ "GenSigTimeoutTime_BPCM" SG_ 1048 V2H_HVCMS_EVMax_P_Limit 0;
BA_ "GenSigTimeoutTime_ECM" SG_ 1048 V2H_HVCMS_EVMax_P_Limit 0;
BA_ "GenSigTimeoutTime_EVCU2" SG_ 1048 V2H_HVCMS_EVMax_P_Limit 0;
BA_ "GenSigTimeoutTime_MCPA" SG_ 1048 V2H_HVCMS_EVMax_P_Limit 0;
BA_ "GenSigTimeoutTime_MCPB" SG_ 1048 V2H_HVCMS_EVMax_P_Limit 0;
BA_ "GenSigTimeoutTime_SGCP" SG_ 1048 V2H_HVCMS_EVMax_P_Limit 0;
BA_ "GenSigTimeoutTime_BPCM" SG_ 1041 EVMinCurrent 0;
BA_ "GenSigTimeoutTime_ECM" SG_ 1041 EVMinCurrent 0;
BA_ "GenSigTimeoutTime_EVCU2" SG_ 1041 EVMinCurrent 0;
BA_ "GenSigTimeoutTime_MCPA" SG_ 1041 EVMinCurrent 0;
BA_ "GenSigTimeoutTime_MCPB" SG_ 1041 EVMinCurrent 0;
BA_ "GenSigTimeoutTime_SGCP" SG_ 1041 EVMinCurrent 0;
BA_ "GenSigTimeoutTime_BPCM" SG_ 1811 Real_Time_Clock 0;
BA_ "GenSigTimeoutTime_ECM" SG_ 1811 Real_Time_Clock 0;
BA_ "GenSigTimeoutTime_EVCU2" SG_ 1811 Real_Time_Clock 0;
BA_ "GenSigTimeoutTime_IDCM" SG_ 1811 Real_Time_Clock 0;
BA_ "GenSigTimeoutTime_BPCM" SG_ 1811 Real_Time_Validity 0;
BA_ "GenSigTimeoutTime_ECM" SG_ 1811 Real_Time_Validity 0;
BA_ "GenSigTimeoutTime_EVCU2" SG_ 1811 Real_Time_Validity 0;
BA_ "GenSigTimeoutTime_IDCM" SG_ 1811 Real_Time_Validity 0;
BA_ "GenSigTimeoutTime_BPCM" SG_ 1041 Eamount 0;
BA_ "GenSigTimeoutTime_ECM" SG_ 1041 Eamount 0;
BA_ "GenSigTimeoutTime_EVCU2" SG_ 1041 Eamount 0;
BA_ "GenSigTimeoutTime_MCPA" SG_ 1041 Eamount 0;
BA_ "GenSigTimeoutTime_MCPB" SG_ 1041 Eamount 0;
BA_ "GenSigTimeoutTime_SGCP" SG_ 1041 Eamount 0;
BA_ "GenSigTimeoutTime_BPCM" SG_ 1041 EVMaxCurrent 0;
BA_ "GenSigTimeoutTime_ECM" SG_ 1041 EVMaxCurrent 0;
BA_ "GenSigTimeoutTime_EVCU2" SG_ 1041 EVMaxCurrent 0;
BA_ "GenSigTimeoutTime_MCPA" SG_ 1041 EVMaxCurrent 0;
BA_ "GenSigTimeoutTime_MCPB" SG_ 1041 EVMaxCurrent 0;
BA_ "GenSigTimeoutTime_SGCP" SG_ 1041 EVMaxCurrent 0;
BA_ "GenSigTimeoutTime_BPCM" SG_ 1041 EVMaxVoltage 0;
BA_ "GenSigTimeoutTime_ECM" SG_ 1041 EVMaxVoltage 0;
BA_ "GenSigTimeoutTime_EVCU2" SG_ 1041 EVMaxVoltage 0;
BA_ "GenSigTimeoutTime_MCPA" SG_ 1041 EVMaxVoltage 0;
BA_ "GenSigTimeoutTime_MCPB" SG_ 1041 EVMaxVoltage 0;
BA_ "GenSigTimeoutTime_SGCP" SG_ 1041 EVMaxVoltage 0;
BA_ "GenSigTimeoutTime_IDCM" SG_ 216 BMS_HV_DC_Chrgng_Cntct_K_Cmd_PT 0;
BA_ "GenSigTimeoutTime_MCPA" SG_ 216 BMS_HV_DC_Chrgng_Cntct_K_Cmd_PT 0;
BA_ "GenSigTimeoutTime_MCPB" SG_ 216 BMS_HV_DC_Chrgng_Cntct_K_Cmd_PT 0;
BA_ "GenSigTimeoutTime_BPCM" SG_ 216 BatteryVoltage_Raw_PT 0;
BA_ "GenSigTimeoutTime_IDCM" SG_ 216 BatteryVoltage_Raw_PT 0;
BA_ "GenSigTimeoutTime_MCPA" SG_ 216 BatteryVoltage_Raw_PT 0;
BA_ "GenSigTimeoutTime_MCPB" SG_ 216 BatteryVoltage_Raw_PT 0;
BA_ "GenSigTimeoutTime_IDCM" SG_ 216 BMS_HV_TracCntctr_Cmd_PT 0;
BA_ "GenSigTimeoutTime_MCPA" SG_ 216 BMS_HV_TracCntctr_Cmd_PT 0;
BA_ "GenSigTimeoutTime_MCPB" SG_ 216 BMS_HV_TracCntctr_Cmd_PT 0;
BA_ "GenSigTimeoutTime_BPCM" SG_ 1042 EVSE_Offered_AC_Three_Phase 0;
BA_ "GenSigTimeoutTime_ECM" SG_ 1042 EVSE_Offered_AC_Three_Phase 0;
BA_ "GenSigTimeoutTime_IDCM" SG_ 1042 EVSE_Offered_AC_Three_Phase 0;
BA_ "GenSigTimeoutTime_MCPA" SG_ 1042 EVSE_Offered_AC_Three_Phase 0;
BA_ "GenSigTimeoutTime_MCPB" SG_ 1042 EVSE_Offered_AC_Three_Phase 0;
BA_ "GenSigTimeoutTime_SGCP" SG_ 1042 EVSE_Offered_AC_Three_Phase 0;
BA_ "GenSigTimeoutTime_MCPA" SG_ 1042 EVSE_Offered_AC_Single_Phase 0;
BA_ "GenSigTimeoutTime_MCPB" SG_ 1042 EVSE_Offered_AC_Single_Phase 0;
BA_ "GenSigTimeoutTime_SGCP" SG_ 1042 EVSE_Offered_AC_Single_Phase 0;
BA_ "GenSigTimeoutTime_BPCM" SG_ 1042 EVSE_Offered_AC_Single_Phase 0;
BA_ "GenSigTimeoutTime_ECM" SG_ 1042 EVSE_Offered_AC_Single_Phase 0;
BA_ "GenSigTimeoutTime_IDCM" SG_ 1042 EVSE_Offered_AC_Single_Phase 0;
BA_ "GenSigTimeoutTime_BPCM" SG_ 1042 Contract_Certificate_Present 0;
BA_ "GenSigTimeoutTime_ECM" SG_ 1042 Contract_Certificate_Present 0;
BA_ "GenSigTimeoutTime_IDCM" SG_ 1042 Contract_Certificate_Present 0;
BA_ "GenSigTimeoutTime_MCPA" SG_ 1042 Contract_Certificate_Present 0;
BA_ "GenSigTimeoutTime_MCPB" SG_ 1042 Contract_Certificate_Present 0;
BA_ "GenSigTimeoutTime_SGCP" SG_ 1042 Contract_Certificate_Present 0;
BA_ "GenSigStartValue" SG_ 263 HCPFuelDisable 1;
BA_ "GenSigTimeoutTime_BPCM" SG_ 263 HCPFuelDisable 0;
BA_ "GenSigTimeoutTime_EVCU2" SG_ 263 HCPFuelDisable 0;
BA_ "GenSigTimeoutTime_IDCM" SG_ 263 HCPFuelDisable 0;
BA_ "GenSigTimeoutTime_MCPA" SG_ 263 HCPFuelDisable 0;
BA_ "GenSigTimeoutTime_MCPB" SG_ 263 HCPFuelDisable 0;
BA_ "GenSigTimeoutTime_SGCP" SG_ 263 HCPFuelDisable 0;
BA_ "GenSigTimeoutTime_BPCM" SG_ 263 GearEngaged_PT 0;
BA_ "GenSigTimeoutTime_ECM" SG_ 263 GearEngaged_PT 0;
BA_ "GenSigTimeoutTime_EVCU2" SG_ 263 GearEngaged_PT 0;
BA_ "GenSigTimeoutTime_IDCM" SG_ 263 GearEngaged_PT 0;
BA_ "GenSigTimeoutTime_MCPA" SG_ 263 GearEngaged_PT 0;
BA_ "GenSigTimeoutTime_SGCP" SG_ 263 GearEngaged_PT 0;
BA_ "GenSigTimeoutTime_ECM" SG_ 263 GearEngagedForDisplay_PT 0;
BA_ "GenSigTimeoutTime_EVCU2" SG_ 263 GearEngagedForDisplay_PT 0;
BA_ "GenSigTimeoutTime_IDCM" SG_ 263 GearEngagedForDisplay_PT 0;
BA_ "GenSigTimeoutTime_ECM" SG_ 263 DriveReady_PT 0;
BA_ "GenSigTimeoutTime_EVCU2" SG_ 263 DriveReady_PT 0;
BA_ "GenSigTimeoutTime_IDCM" SG_ 263 DriveReady_PT 0;
BA_ "GenSigTimeoutTime_MCPA" SG_ 263 DriveReady_PT 0;
BA_ "GenSigTimeoutTime_MCPB" SG_ 263 DriveReady_PT 0;
BA_ "GenSigTimeoutTime_SGCP" SG_ 263 DriveReady_PT 0;
BA_ "GenSigTimeoutTime_BPCM" SG_ 263 Hyb_ProducingTorque 0;
BA_ "GenSigTimeoutTime_EVCU2" SG_ 263 Hyb_ProducingTorque 0;
BA_ "GenSigTimeoutTime_IDCM" SG_ 263 Hyb_ProducingTorque 0;
BA_ "GenSigTimeoutTime_MCPA" SG_ 263 Hyb_ProducingTorque 0;
BA_ "GenSigTimeoutTime_MCPB" SG_ 263 Hyb_ProducingTorque 0;
BA_ "GenSigTimeoutTime_SGCP" SG_ 263 Hyb_ProducingTorque 0;
BA_ "GenSigTimeoutTime_BPCM" SG_ 263 OptimdEngOnOffCmd 0;
BA_ "GenSigTimeoutTime_EVCU2" SG_ 263 OptimdEngOnOffCmd 0;
BA_ "GenSigTimeoutTime_IDCM" SG_ 263 OptimdEngOnOffCmd 0;
BA_ "GenSigTimeoutTime_MCPA" SG_ 263 OptimdEngOnOffCmd 0;
BA_ "GenSigTimeoutTime_MCPB" SG_ 263 OptimdEngOnOffCmd 0;
BA_ "GenSigTimeoutTime_SGCP" SG_ 263 OptimdEngOnOffCmd 0;
BA_ "GenSigTimeoutTime_BPCM" SG_ 263 OptimdEngStrtStpType 0;
BA_ "GenSigTimeoutTime_EVCU2" SG_ 263 OptimdEngStrtStpType 0;
BA_ "GenSigTimeoutTime_IDCM" SG_ 263 OptimdEngStrtStpType 0;
BA_ "GenSigTimeoutTime_MCPA" SG_ 263 OptimdEngStrtStpType 0;
BA_ "GenSigTimeoutTime_MCPB" SG_ 263 OptimdEngStrtStpType 0;
BA_ "GenSigTimeoutTime_SGCP" SG_ 263 OptimdEngStrtStpType 0;
BA_ "GenSigTimeoutTime_BPCM" SG_ 263 OptimdStrtReqdActr 0;
BA_ "GenSigTimeoutTime_EVCU2" SG_ 263 OptimdStrtReqdActr 0;
BA_ "GenSigTimeoutTime_IDCM" SG_ 263 OptimdStrtReqdActr 0;
BA_ "GenSigTimeoutTime_MCPA" SG_ 263 OptimdStrtReqdActr 0;
BA_ "GenSigTimeoutTime_MCPB" SG_ 263 OptimdStrtReqdActr 0;
BA_ "GenSigTimeoutTime_SGCP" SG_ 263 OptimdStrtReqdActr 0;
BA_ "GenSigTimeoutTime_BPCM" SG_ 2654339160 CurrentCanNMState_FD05_MCPA 0;
BA_ "GenSigTimeoutTime_BPCM" SG_ 2654339160 DES_FD05_MCPA 0;
BA_ "GenSigTimeoutTime_ECM" SG_ 2654339160 DES_FD05_MCPA 0;
BA_ "GenSigTimeoutTime_IDCM" SG_ 2654339160 DES_FD05_MCPA 0;
BA_ "GenSigTimeoutTime_MCPA" SG_ 2654339160 DES_FD05_MCPA 0;
BA_ "GenSigTimeoutTime_MCPB" SG_ 2654339160 DES_FD05_MCPA 0;
BA_ "GenSigTimeoutTime_SGCP" SG_ 2654339160 DES_FD05_MCPA 0;
BA_ "GenSigTimeoutTime_BPCM" SG_ 2654339160 EOL_FD05_MCPA 0;
BA_ "GenSigTimeoutTime_ECM" SG_ 2654339160 EOL_FD05_MCPA 0;
BA_ "GenSigTimeoutTime_IDCM" SG_ 2654339160 EOL_FD05_MCPA 0;
BA_ "GenSigTimeoutTime_MCPA" SG_ 2654339160 EOL_FD05_MCPA 0;
BA_ "GenSigTimeoutTime_MCPB" SG_ 2654339160 EOL_FD05_MCPA 0;
BA_ "GenSigTimeoutTime_SGCP" SG_ 2654339160 EOL_FD05_MCPA 0;
BA_ "GenSigTimeoutTime_BPCM" SG_ 2654339160 EOL_FD16_MCPA 0;
BA_ "GenSigTimeoutTime_ECM" SG_ 2654339160 EOL_FD16_MCPA 0;
BA_ "GenSigTimeoutTime_IDCM" SG_ 2654339160 EOL_FD16_MCPA 0;
BA_ "GenSigTimeoutTime_MCPA" SG_ 2654339160 EOL_FD16_MCPA 0;
BA_ "GenSigTimeoutTime_MCPB" SG_ 2654339160 EOL_FD16_MCPA 0;
BA_ "GenSigTimeoutTime_SGCP" SG_ 2654339160 EOL_FD16_MCPA 0;
BA_ "GenSigTimeoutTime_BPCM" SG_ 2654339160 GenericFailSts_FD05_MCPA 0;
BA_ "GenSigTimeoutTime_ECM" SG_ 2654339160 GenericFailSts_FD05_MCPA 0;
BA_ "GenSigTimeoutTime_IDCM" SG_ 2654339160 GenericFailSts_FD05_MCPA 0;
BA_ "GenSigTimeoutTime_MCPA" SG_ 2654339160 GenericFailSts_FD05_MCPA 0;
BA_ "GenSigTimeoutTime_MCPB" SG_ 2654339160 GenericFailSts_FD05_MCPA 0;
BA_ "GenSigTimeoutTime_SGCP" SG_ 2654339160 GenericFailSts_FD05_MCPA 0;
BA_ "GenSigTimeoutTime_BPCM" SG_ 2654339160 PreviousCanNMState_FD05_MCPA 0;
BA_ "GenSigTimeoutTime_ECM" SG_ 2654339160 PreviousCanNMState_FD05_MCPA 0;
BA_ "GenSigTimeoutTime_IDCM" SG_ 2654339160 PreviousCanNMState_FD05_MCPA 0;
BA_ "GenSigTimeoutTime_MCPA" SG_ 2654339160 PreviousCanNMState_FD05_MCPA 0;
BA_ "GenSigTimeoutTime_MCPB" SG_ 2654339160 PreviousCanNMState_FD05_MCPA 0;
BA_ "GenSigTimeoutTime_SGCP" SG_ 2654339160 PreviousCanNMState_FD05_MCPA 0;
BA_ "GenSigTimeoutTime_BPCM" SG_ 2654339160 PreviousCanNMState_FD16_MCPA 0;
BA_ "GenSigTimeoutTime_ECM" SG_ 2654339160 PreviousCanNMState_FD16_MCPA 0;
BA_ "GenSigTimeoutTime_IDCM" SG_ 2654339160 PreviousCanNMState_FD16_MCPA 0;
BA_ "GenSigTimeoutTime_MCPA" SG_ 2654339160 PreviousCanNMState_FD16_MCPA 0;
BA_ "GenSigTimeoutTime_MCPB" SG_ 2654339160 PreviousCanNMState_FD16_MCPA 0;
BA_ "GenSigTimeoutTime_SGCP" SG_ 2654339160 PreviousCanNMState_FD16_MCPA 0;
BA_ "GenSigTimeoutTime_BPCM" SG_ 2654339160 StayActiveSource_FD05_MCPA 0;
BA_ "GenSigTimeoutTime_ECM" SG_ 2654339160 StayActiveSource_FD05_MCPA 0;
BA_ "GenSigTimeoutTime_IDCM" SG_ 2654339160 StayActiveSource_FD05_MCPA 0;
BA_ "GenSigTimeoutTime_MCPA" SG_ 2654339160 StayActiveSource_FD05_MCPA 0;
BA_ "GenSigTimeoutTime_MCPB" SG_ 2654339160 StayActiveSource_FD05_MCPA 0;
BA_ "GenSigTimeoutTime_SGCP" SG_ 2654339160 StayActiveSource_FD05_MCPA 0;
BA_ "GenSigTimeoutTime_BPCM" SG_ 2654339160 StayActiveSource_FD16_MCPA 0;
BA_ "GenSigTimeoutTime_ECM" SG_ 2654339160 StayActiveSource_FD16_MCPA 0;
BA_ "GenSigTimeoutTime_IDCM" SG_ 2654339160 StayActiveSource_FD16_MCPA 0;
BA_ "GenSigTimeoutTime_MCPA" SG_ 2654339160 StayActiveSource_FD16_MCPA 0;
BA_ "GenSigTimeoutTime_MCPB" SG_ 2654339160 StayActiveSource_FD16_MCPA 0;
BA_ "GenSigTimeoutTime_SGCP" SG_ 2654339160 StayActiveSource_FD16_MCPA 0;
BA_ "GenSigTimeoutTime_BPCM" SG_ 2654339160 WakeupSource_FD05_MCPA 0;
BA_ "GenSigTimeoutTime_ECM" SG_ 2654339160 WakeupSource_FD05_MCPA 0;
BA_ "GenSigTimeoutTime_IDCM" SG_ 2654339160 WakeupSource_FD05_MCPA 0;
BA_ "GenSigTimeoutTime_MCPA" SG_ 2654339160 WakeupSource_FD05_MCPA 0;
BA_ "GenSigTimeoutTime_MCPB" SG_ 2654339160 WakeupSource_FD05_MCPA 0;
BA_ "GenSigTimeoutTime_SGCP" SG_ 2654339160 WakeupSource_FD05_MCPA 0;
BA_ "GenSigTimeoutTime_BPCM" SG_ 2654339160 WakeupSource_FD16_MCPA 0;
BA_ "GenSigTimeoutTime_ECM" SG_ 2654339160 WakeupSource_FD16_MCPA 0;
BA_ "GenSigTimeoutTime_IDCM" SG_ 2654339160 WakeupSource_FD16_MCPA 0;
BA_ "GenSigTimeoutTime_MCPA" SG_ 2654339160 WakeupSource_FD16_MCPA 0;
BA_ "GenSigTimeoutTime_MCPB" SG_ 2654339160 WakeupSource_FD16_MCPA 0;
BA_ "GenSigTimeoutTime_SGCP" SG_ 2654339160 WakeupSource_FD16_MCPA 0;
BA_ "GenSigTimeoutTime_BPCM" SG_ 2564485756 N_PDU_18DAF27C 0;
BA_ "GenSigTimeoutTime_ECM" SG_ 2564485756 N_PDU_18DAF27C 0;
BA_ "GenSigTimeoutTime_EVCU2" SG_ 2564485756 N_PDU_18DAF27C 0;
BA_ "GenSigTimeoutTime_IDCM" SG_ 2564485756 N_PDU_18DAF27C 0;
BA_ "GenSigTimeoutTime_MCPA" SG_ 2564485756 N_PDU_18DAF27C 0;
BA_ "GenSigTimeoutTime_MCPB" SG_ 2564485756 N_PDU_18DAF27C 0;
BA_ "GenSigTimeoutTime_SGCP" SG_ 2564485756 N_PDU_18DAF27C 0;
BA_ "GenSigTimeoutTime_BPCM" SG_ 2564455666 N_PDU_18DA7CF2 0;
BA_ "GenSigTimeoutTime_ECM" SG_ 2564455666 N_PDU_18DA7CF2 0;
BA_ "GenSigTimeoutTime_EVCU2" SG_ 2564455666 N_PDU_18DA7CF2 0;
BA_ "GenSigTimeoutTime_IDCM" SG_ 2564455666 N_PDU_18DA7CF2 0;
BA_ "GenSigTimeoutTime_MCPA" SG_ 2564455666 N_PDU_18DA7CF2 0;
BA_ "GenSigTimeoutTime_MCPB" SG_ 2564455666 N_PDU_18DA7CF2 0;
BA_ "GenSigTimeoutTime_SGCP" SG_ 2564455666 N_PDU_18DA7CF2 0;
BA_ "GenSigTimeoutTime_BPCM" SG_ 2564455665 N_PDU_18DA7CF1 0;
BA_ "GenSigTimeoutTime_ECM" SG_ 2564455665 N_PDU_18DA7CF1 0;
BA_ "GenSigTimeoutTime_EVCU2" SG_ 2564455665 N_PDU_18DA7CF1 0;
BA_ "GenSigTimeoutTime_IDCM" SG_ 2564455665 N_PDU_18DA7CF1 0;
BA_ "GenSigTimeoutTime_MCPA" SG_ 2564455665 N_PDU_18DA7CF1 0;
BA_ "GenSigTimeoutTime_MCPB" SG_ 2564455665 N_PDU_18DA7CF1 0;
BA_ "GenSigTimeoutTime_SGCP" SG_ 2564455665 N_PDU_18DA7CF1 0;
BA_ "GenSigTimeoutTime_BPCM" SG_ 263 CRC_PT_SYSTEM_FD_1 0;
BA_ "GenSigTimeoutTime_EVCU2" SG_ 263 CRC_PT_SYSTEM_FD_1 0;
BA_ "GenSigTimeoutTime_IDCM" SG_ 263 CRC_PT_SYSTEM_FD_1 0;
BA_ "GenSigTimeoutTime_BPCM" SG_ 2564682108 N_PDU_18DDF17C 0;
BA_ "GenSigTimeoutTime_ECM" SG_ 2564682108 N_PDU_18DDF17C 0;
BA_ "GenSigTimeoutTime_EVCU2" SG_ 2564682108 N_PDU_18DDF17C 0;
BA_ "GenSigTimeoutTime_IDCM" SG_ 2564682108 N_PDU_18DDF17C 0;
BA_ "GenSigTimeoutTime_MCPA" SG_ 2564682108 N_PDU_18DDF17C 0;
BA_ "GenSigTimeoutTime_MCPB" SG_ 2564682108 N_PDU_18DDF17C 0;
BA_ "GenSigTimeoutTime_SGCP" SG_ 2564682108 N_PDU_18DDF17C 0;
BA_ "GenSigTimeoutTime_BPCM" SG_ 2564485500 N_PDU_18DAF17C 0;
BA_ "GenSigTimeoutTime_ECM" SG_ 2564485500 N_PDU_18DAF17C 0;
BA_ "GenSigTimeoutTime_EVCU2" SG_ 2564485500 N_PDU_18DAF17C 0;
BA_ "GenSigTimeoutTime_IDCM" SG_ 2564485500 N_PDU_18DAF17C 0;
BA_ "GenSigTimeoutTime_MCPA" SG_ 2564485500 N_PDU_18DAF17C 0;
BA_ "GenSigTimeoutTime_MCPB" SG_ 2564485500 N_PDU_18DAF17C 0;
BA_ "GenSigTimeoutTime_SGCP" SG_ 2564485500 N_PDU_18DAF17C 0;
BA_ "GenSigTimeoutTime_BPCM" SG_ 2564682364 N_PDU_18DDF27C 0;
BA_ "GenSigTimeoutTime_ECM" SG_ 2564682364 N_PDU_18DDF27C 0;
BA_ "GenSigTimeoutTime_EVCU2" SG_ 2564682364 N_PDU_18DDF27C 0;
BA_ "GenSigTimeoutTime_IDCM" SG_ 2564682364 N_PDU_18DDF27C 0;
BA_ "GenSigTimeoutTime_MCPA" SG_ 2564682364 N_PDU_18DDF27C 0;
BA_ "GenSigTimeoutTime_MCPB" SG_ 2564682364 N_PDU_18DDF27C 0;
BA_ "GenSigTimeoutTime_SGCP" SG_ 2564682364 N_PDU_18DDF27C 0;
BA_ "GenSigTimeoutTime_BPCM" SG_ 2654339160 CurrentFailSts_FD16_MCPA 0;
BA_ "GenSigTimeoutTime_ECM" SG_ 2654339160 CurrentFailSts_FD16_MCPA 0;
BA_ "GenSigTimeoutTime_IDCM" SG_ 2654339160 CurrentFailSts_FD16_MCPA 0;
BA_ "GenSigTimeoutTime_MCPA" SG_ 2654339160 CurrentFailSts_FD16_MCPA 0;
BA_ "GenSigTimeoutTime_MCPB" SG_ 2654339160 CurrentFailSts_FD16_MCPA 0;
BA_ "GenSigTimeoutTime_SGCP" SG_ 2654339160 CurrentFailSts_FD16_MCPA 0;
BA_ "GenSigTimeoutTime_BPCM" SG_ 2654339160 DES_FD16_MCPA 0;
BA_ "GenSigTimeoutTime_ECM" SG_ 2654339160 DES_FD16_MCPA 0;
BA_ "GenSigTimeoutTime_IDCM" SG_ 2654339160 DES_FD16_MCPA 0;
BA_ "GenSigTimeoutTime_MCPA" SG_ 2654339160 DES_FD16_MCPA 0;
BA_ "GenSigTimeoutTime_MCPB" SG_ 2654339160 DES_FD16_MCPA 0;
BA_ "GenSigTimeoutTime_SGCP" SG_ 2654339160 DES_FD16_MCPA 0;
BA_ "GenSigTimeoutTime_BPCM" SG_ 263 MessageCounter_PT_SYSTEM_FD_1 0;
BA_ "GenSigTimeoutTime_EVCU2" SG_ 263 MessageCounter_PT_SYSTEM_FD_1 0;
BA_ "GenSigTimeoutTime_IDCM" SG_ 263 MessageCounter_PT_SYSTEM_FD_1 0;
BA_ "GenSigTimeoutTime_BPCM" SG_ 263 GasPedalPosition_PT 0;
BA_ "GenSigTimeoutTime_EVCU2" SG_ 263 GasPedalPosition_PT 0;
BA_ "GenSigTimeoutTime_IDCM" SG_ 263 GasPedalPosition_PT 0;
BA_ "GenSigTimeoutTime_MCPA" SG_ 263 GasPedalPosition_PT 0;
BA_ "GenSigTimeoutTime_MCPB" SG_ 263 GasPedalPosition_PT 0;
BA_ "GenSigTimeoutTime_SGCP" SG_ 263 GasPedalPosition_PT 0;
BA_ "GenSigTimeoutTime_BPCM" SG_ 263 GasPedalPositionFailSts_PT 0;
BA_ "GenSigTimeoutTime_EVCU2" SG_ 263 GasPedalPositionFailSts_PT 0;
BA_ "GenSigTimeoutTime_IDCM" SG_ 263 GasPedalPositionFailSts_PT 0;
BA_ "GenSigTimeoutTime_MCPA" SG_ 263 GasPedalPositionFailSts_PT 0;
BA_ "GenSigTimeoutTime_MCPB" SG_ 263 GasPedalPositionFailSts_PT 0;
BA_ "GenSigTimeoutTime_SGCP" SG_ 263 GasPedalPositionFailSts_PT 0;
BA_ "GenSigTimeoutTime_BPCM" SG_ 2654339160 GenericFailSts_FD16_MCPA 0;
BA_ "GenSigTimeoutTime_ECM" SG_ 2654339160 GenericFailSts_FD16_MCPA 0;
BA_ "GenSigTimeoutTime_IDCM" SG_ 2654339160 GenericFailSts_FD16_MCPA 0;
BA_ "GenSigTimeoutTime_MCPA" SG_ 2654339160 GenericFailSts_FD16_MCPA 0;
BA_ "GenSigTimeoutTime_MCPB" SG_ 2654339160 GenericFailSts_FD16_MCPA 0;
BA_ "GenSigTimeoutTime_SGCP" SG_ 2654339160 GenericFailSts_FD16_MCPA 0;
BA_ "GenSigTimeoutTime_BPCM" SG_ 263 PropulsionMode_PT 0;
BA_ "GenSigTimeoutTime_EVCU2" SG_ 263 PropulsionMode_PT 0;
BA_ "GenSigTimeoutTime_IDCM" SG_ 263 PropulsionMode_PT 0;
BA_ "GenSigTimeoutTime_MCPA" SG_ 263 PropulsionMode_PT 0;
BA_ "GenSigTimeoutTime_MCPB" SG_ 263 PropulsionMode_PT 0;
BA_ "GenSigTimeoutTime_SGCP" SG_ 263 PropulsionMode_PT 0;
BA_ "GenSigTimeoutTime_BPCM" SG_ 263 PropulsionSystemActive_PT 0;
BA_ "GenSigTimeoutTime_ECM" SG_ 263 PropulsionSystemActive_PT 0;
BA_ "GenSigTimeoutTime_EVCU2" SG_ 263 PropulsionSystemActive_PT 0;
BA_ "GenSigTimeoutTime_IDCM" SG_ 263 PropulsionSystemActive_PT 0;
BA_ "GenSigTimeoutTime_MCPA" SG_ 263 PropulsionSystemActive_PT 0;
BA_ "GenSigTimeoutTime_MCPB" SG_ 263 PropulsionSystemActive_PT 0;
BA_ "GenSigTimeoutTime_SGCP" SG_ 263 PropulsionSystemActive_PT 0;
BA_ "GenSigTimeoutTime_BPCM" SG_ 2654339161 CurrentFailSts_FD16_MCPB 0;
BA_ "GenSigTimeoutTime_ECM" SG_ 2654339161 CurrentFailSts_FD16_MCPB 0;
BA_ "GenSigTimeoutTime_IDCM" SG_ 2654339161 CurrentFailSts_FD16_MCPB 0;
BA_ "GenSigTimeoutTime_MCPA" SG_ 2654339161 CurrentFailSts_FD16_MCPB 0;
BA_ "GenSigTimeoutTime_MCPB" SG_ 2654339161 CurrentFailSts_FD16_MCPB 0;
BA_ "GenSigTimeoutTime_SGCP" SG_ 2654339161 CurrentFailSts_FD16_MCPB 0;
BA_ "GenSigTimeoutTime_BPCM" SG_ 2654339161 DES_FD16_MCPB 0;
BA_ "GenSigTimeoutTime_ECM" SG_ 2654339161 DES_FD16_MCPB 0;
BA_ "GenSigTimeoutTime_IDCM" SG_ 2654339161 DES_FD16_MCPB 0;
BA_ "GenSigTimeoutTime_BPCM" SG_ 2654339142 CurrentFailSts_FD05_BPCM 0;
BA_ "GenSigTimeoutTime_ECM" SG_ 2654339142 CurrentFailSts_FD05_BPCM 0;
BA_ "GenSigTimeoutTime_IDCM" SG_ 2654339142 CurrentFailSts_FD05_BPCM 0;
BA_ "GenSigTimeoutTime_MCPA" SG_ 2654339142 CurrentFailSts_FD05_BPCM 0;
BA_ "GenSigTimeoutTime_MCPB" SG_ 2654339142 CurrentFailSts_FD05_BPCM 0;
BA_ "GenSigTimeoutTime_SGCP" SG_ 2654339142 CurrentFailSts_FD05_BPCM 0;
BA_ "GenSigTimeoutTime_BPCM" SG_ 2654339142 CurrentCanNMState_FD05_BPCM 0;
BA_ "GenSigTimeoutTime_ECM" SG_ 2654339142 CurrentCanNMState_FD05_BPCM 0;
BA_ "GenSigTimeoutTime_IDCM" SG_ 2654339142 CurrentCanNMState_FD05_BPCM 0;
BA_ "GenSigTimeoutTime_MCPA" SG_ 2654339142 CurrentCanNMState_FD05_BPCM 0;
BA_ "GenSigTimeoutTime_MCPB" SG_ 2654339142 CurrentCanNMState_FD05_BPCM 0;
BA_ "GenSigTimeoutTime_SGCP" SG_ 2654339142 CurrentCanNMState_FD05_BPCM 0;
BA_ "GenSigTimeoutTime_BPCM" SG_ 2654339142 DES_FD05_BPCM 0;
BA_ "GenSigTimeoutTime_ECM" SG_ 2654339142 DES_FD05_BPCM 0;
BA_ "GenSigTimeoutTime_IDCM" SG_ 2654339142 DES_FD05_BPCM 0;
BA_ "GenSigTimeoutTime_MCPA" SG_ 2654339142 DES_FD05_BPCM 0;
BA_ "GenSigTimeoutTime_MCPB" SG_ 2654339142 DES_FD05_BPCM 0;
BA_ "GenSigTimeoutTime_SGCP" SG_ 2654339142 DES_FD05_BPCM 0;
BA_ "GenSigTimeoutTime_BPCM" SG_ 2654339142 EOL_FD05_BPCM 0;
BA_ "GenSigTimeoutTime_ECM" SG_ 2654339142 EOL_FD05_BPCM 0;
BA_ "GenSigTimeoutTime_IDCM" SG_ 2654339142 EOL_FD05_BPCM 0;
BA_ "GenSigTimeoutTime_MCPA" SG_ 2654339142 EOL_FD05_BPCM 0;
BA_ "GenSigTimeoutTime_MCPB" SG_ 2654339142 EOL_FD05_BPCM 0;
BA_ "GenSigTimeoutTime_SGCP" SG_ 2654339142 EOL_FD05_BPCM 0;
BA_ "GenSigTimeoutTime_BPCM" SG_ 2654339142 GenericFailSts_FD05_BPCM 0;
BA_ "GenSigTimeoutTime_ECM" SG_ 2654339142 GenericFailSts_FD05_BPCM 0;
BA_ "GenSigTimeoutTime_IDCM" SG_ 2654339142 GenericFailSts_FD05_BPCM 0;
BA_ "GenSigTimeoutTime_MCPA" SG_ 2654339142 GenericFailSts_FD05_BPCM 0;
BA_ "GenSigTimeoutTime_MCPB" SG_ 2654339142 GenericFailSts_FD05_BPCM 0;
BA_ "GenSigTimeoutTime_SGCP" SG_ 2654339142 GenericFailSts_FD05_BPCM 0;
BA_ "GenSigTimeoutTime_BPCM" SG_ 2654339142 PreviousCanNMState_FD05_BPCM 0;
BA_ "GenSigTimeoutTime_ECM" SG_ 2654339142 PreviousCanNMState_FD05_BPCM 0;
BA_ "GenSigTimeoutTime_IDCM" SG_ 2654339142 PreviousCanNMState_FD05_BPCM 0;
BA_ "GenSigTimeoutTime_MCPA" SG_ 2654339142 PreviousCanNMState_FD05_BPCM 0;
BA_ "GenSigTimeoutTime_MCPB" SG_ 2654339142 PreviousCanNMState_FD05_BPCM 0;
BA_ "GenSigTimeoutTime_SGCP" SG_ 2654339142 PreviousCanNMState_FD05_BPCM 0;
BA_ "GenSigTimeoutTime_BPCM" SG_ 2654339142 StayActiveSource_FD05_BPCM 0;
BA_ "GenSigTimeoutTime_ECM" SG_ 2654339142 StayActiveSource_FD05_BPCM 0;
BA_ "GenSigTimeoutTime_IDCM" SG_ 2654339142 StayActiveSource_FD05_BPCM 0;
BA_ "GenSigTimeoutTime_MCPA" SG_ 2654339142 StayActiveSource_FD05_BPCM 0;
BA_ "GenSigTimeoutTime_MCPB" SG_ 2654339142 StayActiveSource_FD05_BPCM 0;
BA_ "GenSigTimeoutTime_SGCP" SG_ 2654339142 StayActiveSource_FD05_BPCM 0;
BA_ "GenSigTimeoutTime_BPCM" SG_ 2654339142 WakeupSource_FD05_BPCM 0;
BA_ "GenSigTimeoutTime_ECM" SG_ 2654339142 WakeupSource_FD05_BPCM 0;
BA_ "GenSigTimeoutTime_IDCM" SG_ 2654339142 WakeupSource_FD05_BPCM 0;
BA_ "GenSigTimeoutTime_MCPA" SG_ 2654339142 WakeupSource_FD05_BPCM 0;
BA_ "GenSigTimeoutTime_MCPB" SG_ 2654339142 WakeupSource_FD05_BPCM 0;
BA_ "GenSigTimeoutTime_SGCP" SG_ 2654339142 WakeupSource_FD05_BPCM 0;
VAL_ 288 BPCM_HV_ChargingCurrentProfile 32767 "SNA";
VAL_ 288 BPCM_HV_Cell_MinDischrg_Imped 8191 "SNA";
VAL_ 288 BPCM_HV_Cell_MaxDischrg_Imped 8191 "SNA";
VAL_ 288 BPCM_CntctrsShtTrmOpeningWarn 0 "FALSE" 1 "TRUE";
VAL_ 288 BPCM_CntctrsMidTrmOpeningWarn 0 "FALSE" 1 "TRUE";
VAL_ 2654339273 WakeupSource_FD16_SGCP 0 "No_Wakeup";
VAL_ 2654339273 WakeupSource_FD05_SGCP 0 "No_Wakeup";
VAL_ 292 HVBatContactorWeldCheck 0 "Not_Complete" 1 "Complete";
VAL_ 292 HVBatReady 0 "False" 1 "True";
VAL_ 292 BPCM_DC_CntctrsMidTrmOpeningWarn 0 "False" 1 "True";
VAL_ 292 BPCM_DC_CntctrsShtTrmOpeningWarn 0 "False" 1 "True";
VAL_ 292 BPCM_HV_Char_Main_Contac_Sts 0 "Open" 1 "Closed" 3 "Error_Stuck_Open" 4 "Error_Stuck_Closed" 7 "SNA";
VAL_ 292 BPCM_HV_Trac_Main_Contac_Sts 0 "Open" 1 "Closed" 3 "Error_Stuck_Open" 4 "Error_Stuck_Closed" 7 "SNA";
VAL_ 292 BPCM_HV_BalancingMode 0 "No_balancing" 1 "Balancing_in_progress" 2 "Balancing_complete" 3 "Balancing_Error";
VAL_ 292 BPCM_HV_ChargingBusVoltage 2047 "SNA";
VAL_ 292 BPCM_HV_TractionBusVoltage 2047 "SNA";
VAL_ 292 BPCM_Pwr_Limp_Home_On 0 "Disable" 1 "Enable";
VAL_ 292 BPCM_HV_Trac_Bus_Sts 0 "Open" 1 "Closed" 2 "Precharging" 3 "Precharging_Failed" 4 "Precharging_Inhibited" 7 "SNA";
VAL_ 292 BPCM_HV_Char_Bus_Sts 0 "Open" 1 "Closed" 2 "Precharging" 3 "Precharging_Failed" 4 "Precharging_Inhibited" 7 "SNA";
VAL_ 292 BPCM_HV_SOH_Low 127 "SNA";
VAL_ 292 BPCM_HV_SOH 127 "SNA";
VAL_ 485 BPCM_HV_NumCellMinTemp 511 "SNA";
VAL_ 485 BPCM_HV_NumCellMaxTemp 511 "SNA";
VAL_ 485 BPCM_HV_NumCellMinVolt 511 "SNA";
VAL_ 485 BPCM_HV_NumCellMaxVolt 511 "SNA";
VAL_ 485 BPCM_Min_Pk_Volt_Allowed 2047 "SNA";
VAL_ 485 BPCM_Max_Pk_Volt_Allowed 2047 "SNA";
VAL_ 288 BPCM_HV_HVBatChargeStat 0 "NOT_READY" 1 "READY" 2 "ERROR_DETECTED" 3 "COMPLETE" 7 "SNA";
VAL_ 292 BPCMInterlockSts 0 "Not_Performed" 1 "OK" 2 "Fail" 3 "Invalid" 4 "Service_Disconnect";
VAL_ 292 BPCM_HV_BatIntrlk_InternalStat 0 "Not_Performed" 1 "OK" 2 "Fail" 3 "Invalid";
VAL_ 485 BPCM_OCV_Min_Cell_Volt 8191 "SNA";
VAL_ 485 BPCM_OCV_Max_Cell_Volt 8191 "SNA";
VAL_ 485 BPCM_OCV_Avg_Cell_Volt 8191 "SNA";
VAL_ 485 BPCM_Min_Cell_Volt_Allowed 8191 "SNA";
VAL_ 485 BPCM_Max_Cell_Volt_Allowed 8191 "SNA";
VAL_ 485 BPCM_Cell_Volt_Min 8191 "SNA";
VAL_ 485 BPCM_Cell_Volt_Max 8191 "SNA";
VAL_ 485 BPCM_Cell_Volt_Avg 8191 "SNA";
VAL_ 292 BPCM_HV_Temperature_Min 2047 "SNA";
VAL_ 292 BPCM_HV_Temperature_Max 2047 "SNA";
VAL_ 292 BPCM_HV_Temperature_Avg 2047 "SNA";
VAL_ 292 BPCM_HV_SOC 1023 "SNA";
VAL_ 292 BPCM_HV_Outlet_Temp 2047 "SNA";
VAL_ 292 BPCM_HV_InternalVoltage 16383 "SNA";
VAL_ 292 BPCM_HV_Inlet_Temp 2047 "SNA";
VAL_ 292 BPCM_HV_Current 65535 "SNA";
VAL_ 292 BPCM_HV_Capacity 4095 "SNA";
VAL_ 292 BPCM_HV_Battery_GFD_Sts 0 "GFD_Not_Performed" 1 "GFD_OK" 2 "GFD_Fail" 3 "GFD_INVALID_meas_noise" 4 "Disabled";
VAL_ 288 BPCM_HV_PwrLmtInstDschg 16383 "SNA";
VAL_ 288 BPCM_HV_PwrLmtInstChrg 16383 "SNA";
VAL_ 288 BPCM_HV_Pwr_MaxDischrg_ShrTrm 16383 "SNA";
VAL_ 288 BPCM_HV_Power_MaxDischarge_MdTrm 16383 "SNA";
VAL_ 288 BPCM_HV_Power_MaxDischarge_LgTrm 16383 "SNA";
VAL_ 288 BPCM_HV_Power_MaxCharge_ShrTrm 16383 "SNA";
VAL_ 288 BPCM_HV_Power_MaxCharge_MdTrm 16383 "SNA";
VAL_ 288 BPCM_HV_Power_MaxCharge_LgTrm 16383 "SNA";
VAL_ 288 BPCM_HV_CrntLmtInstDschg 32767 "SNA";
VAL_ 288 BPCM_HV_CrntLmtInstChrg 32767 "SNA";
VAL_ 2654339273 PreviousCanNMState_FD16_SGCP 0 "Uninitialized State" 1 "Bus-Sleep State" 2 "Prepare-Bus State" 3 "Ready-Sleep State" 4 "Normal Operation State" 5 "Repeat Message State" 6 "Synchronize State" 7 "Offline State";
VAL_ 2654339273 PreviousCanNMState_FD05_SGCP 0 "Uninitialized State" 1 "Bus-Sleep State" 2 "Prepare-Bus State" 3 "Ready-Sleep State" 4 "Normal Operation State" 5 "Repeat Message State" 6 "Synchronize State" 7 "Offline State";
VAL_ 2654339273 GenericFailSts_FD16_SGCP 0 "No_Fail_Present" 1 "Fail_Present";
VAL_ 2654339273 GenericFailSts_FD05_SGCP 0 "No_Fail_Present" 1 "Fail_Present";
VAL_ 2654339273 EOL_FD16_SGCP 0 "No_EOL_Programming" 1 "EOL_Programming";
VAL_ 2654339273 EOL_FD05_SGCP 0 "No_EOL_Programming" 1 "EOL_Programming";
VAL_ 2654339273 DES_FD16_SGCP 0 "Error_Active_state" 1 "Error_passive_warning_state" 2 "Bus_off_state" 3 "Not_used";
VAL_ 2654339273 DES_FD05_SGCP 0 "Error_Active_state" 1 "Error_passive_warning_state" 2 "Bus_off_state" 3 "Not_used";
VAL_ 2654339273 CurrentFailSts_FD16_SGCP 0 "No_Fail_Present" 1 "Fail_Present";
VAL_ 2654339273 CurrentFailSts_FD05_SGCP 0 "No_Fail_Present" 1 "Fail_Present";
VAL_ 2654339273 CurrentCanNMState_FD16_SGCP 0 "Uninitialized State" 1 "Bus-Sleep State" 2 "Prepare-Bus State" 3 "Ready-Sleep State" 4 "Normal Operation State" 5 "Repeat Message State" 6 "Synchronize State" 7 "Offline State";
VAL_ 2654339273 CurrentCanNMState_FD05_SGCP 0 "Uninitialized State" 1 "Bus-Sleep State" 2 "Prepare-Bus State" 3 "Ready-Sleep State" 4 "Normal Operation State" 5 "Repeat Message State" 6 "Synchronize State" 7 "Offline State";
VAL_ 2654339161 WakeupSource_FD16_MCPB 0 "No_Wakeup";
VAL_ 2654339161 WakeupSource_FD05_MCPB 0 "No_Wakeup";
VAL_ 2654339161 PreviousCanNMState_FD16_MCPB 0 "Uninitialized State" 1 "Bus-Sleep State" 2 "Prepare-Bus State" 3 "Ready-Sleep State" 4 "Normal Operation State" 5 "Repeat Message State" 6 "Synchronize State" 7 "Offline State";
VAL_ 2654339161 PreviousCanNMState_FD05_MCPB 0 "Uninitialized State" 1 "Bus-Sleep State" 2 "Prepare-Bus State" 3 "Ready-Sleep State" 4 "Normal Operation State" 5 "Repeat Message State" 6 "Synchronize State" 7 "Offline State";
VAL_ 2654339161 GenericFailSts_FD05_MCPB 0 "No_Fail_Present" 1 "Fail_Present";
VAL_ 2654339161 EOL_FD16_MCPB 0 "No_EOL_Programming" 1 "EOL_Programming";
VAL_ 2654339161 EOL_FD05_MCPB 0 "No_EOL_Programming" 1 "EOL_Programming";
VAL_ 2654339161 DES_FD05_MCPB 0 "Error_Active_state" 1 "Error_passive_warning_state" 2 "Bus_off_state" 3 "Not_used";
VAL_ 2654339161 CurrentFailSts_FD05_MCPB 0 "No_Fail_Present" 1 "Fail_Present";
VAL_ 2654339161 CurrentCanNMState_FD16_MCPB 0 "Uninitialized State" 1 "Bus-Sleep State" 2 "Prepare-Bus State" 3 "Ready-Sleep State" 4 "Normal Operation State" 5 "Repeat Message State" 6 "Synchronize State" 7 "Offline State";
VAL_ 2654339161 CurrentCanNMState_FD05_MCPB 0 "Uninitialized State" 1 "Bus-Sleep State" 2 "Prepare-Bus State" 3 "Ready-Sleep State" 4 "Normal Operation State" 5 "Repeat Message State" 6 "Synchronize State" 7 "Offline State";
VAL_ 2654339160 WakeupSource_FD16_MCPA 0 "No_Wakeup";
VAL_ 2654339160 WakeupSource_FD05_MCPA 0 "No_Wakeup";
VAL_ 2654339160 PreviousCanNMState_FD16_MCPA 0 "Uninitialized State" 1 "Bus-Sleep State" 2 "Prepare-Bus State" 3 "Ready-Sleep State" 4 "Normal Operation State" 5 "Repeat Message State" 6 "Synchronize State" 7 "Offline State";
VAL_ 2654339160 PreviousCanNMState_FD05_MCPA 0 "Uninitialized State" 1 "Bus-Sleep State" 2 "Prepare-Bus State" 3 "Ready-Sleep State" 4 "Normal Operation State" 5 "Repeat Message State" 6 "Synchronize State" 7 "Offline State";
VAL_ 2654339160 GenericFailSts_FD05_MCPA 0 "No_Fail_Present" 1 "Fail_Present";
VAL_ 2654339160 EOL_FD16_MCPA 0 "No_EOL_Programming" 1 "EOL_Programming";
VAL_ 2654339160 EOL_FD05_MCPA 0 "No_EOL_Programming" 1 "EOL_Programming";
VAL_ 2654339160 DES_FD05_MCPA 0 "Error_Active_state" 1 "Error_passive_warning_state" 2 "Bus_off_state" 3 "Not_used";
VAL_ 2654339160 CurrentFailSts_FD05_MCPA 0 "No_Fail_Present" 1 "Fail_Present";
VAL_ 2654339160 CurrentCanNMState_FD16_MCPA 0 "Uninitialized State" 1 "Bus-Sleep State" 2 "Prepare-Bus State" 3 "Ready-Sleep State" 4 "Normal Operation State" 5 "Repeat Message State" 6 "Synchronize State" 7 "Offline State";
VAL_ 2654339160 CurrentCanNMState_FD05_MCPA 0 "Uninitialized State" 1 "Bus-Sleep State" 2 "Prepare-Bus State" 3 "Ready-Sleep State" 4 "Normal Operation State" 5 "Repeat Message State" 6 "Synchronize State" 7 "Offline State";
VAL_ 263 OptimdStrtReqdActr 0 "No_Action" 1 "P1f" 2 "P1r" 3 "Starter_12V" 4 "P2" 7 "SNA";
VAL_ 292 HVBP_Busbar_Temp 255 "SNA";
VAL_ 292 HVBP_BDU_Busbar_Temp 255 "SNA";
VAL_ 1070 SGCP_DTC_Stat2 0 "Not_Supported" 1 "Critically_disabled" 2 "No_status_to_report" 3 "Diagnostic_passed" 4 "Diagnostic_failed" 5 "Reset_DTC_status" 7 "SNA";
VAL_ 263 OptimdEngStrtStpType 0 "No_Action" 1 "Hybrid_Torque_Start" 2 "Engine_Torque_Start" 3 "Low_Power_Start" 4 "Generic_Torque_Start" 5 "Smooth_AutoStart" 6 "Normal_AutoStart" 7 "Aggressive_Autostart" 8 "Generic_Autostart" 9 "Compression_Test" 10 "Green_Engine_Start" 11 "Controlled_Stop" 12 "Immediate_Stop" 13 "Reverse_Autostart" 14 "Clutch_Autostart" 15 "Imp_Autostart" 16 "EM_Autostart" 17 "EM_LowPower" 31 "SNA";
VAL_ 263 OptimdEngOnOffCmd 0 "Off_Command" 1 "On_Command";
VAL_ 263 Hyb_ProducingTorque 0 "Not_Producing_Torque" 1 "Producing_Torque";
VAL_ 263 HCPFuelDisable 0 "Do_Not_Disable_Fuel" 1 "Disable_Fuel";
VAL_ 263 PowertrainPrplsnActv_PT 0 "Not_Active" 1 "Active";
VAL_ 263 GearEngagedForDisplay_PT 0 "Initialize" 1 "Gear_1st" 2 "Gear_2nd" 3 "Gear_3rd" 4 "Gear_4th" 5 "Gear_5th" 6 "Gear_6th" 7 "Gear_7th" 8 "Gear_8th" 9 "Gear_9th" 12 "Park" 13 "Neutral" 14 "Reverse" 15 "Drive" 16 "Low" 17 "Manual" 18 "Sport_Mode" 31 "SNA";
VAL_ 263 GearEngaged_PT 0 "Neutral" 1 "ForwardGear_1" 2 "ForwardGear_2" 3 "ForwardGear_3" 4 "ForwardGear_4" 5 "ForwardGear_5" 6 "ForwardGear_6" 7 "ForwardGear_7" 8 "ForwardGear_8" 9 "ForwardGear_9" 13 "Parking" 14 "ReverseGear" 15 "SNA";
VAL_ 263 DriveReady_PT 0 "Default" 1 "Veh_Allwd_Shift_Out_Of_P_Or_N";
VAL_ 216 DCChargeInitialized_PT 0 "FALSE" 1 "TRUE";
VAL_ 216 DCChargeEnRq_PT 0 "ChargeNotEnabled" 1 "ChargeEnabled";
VAL_ 216 BPCM_OBCM_AC_ContactorCmd_PT 0 "OPEN" 1 "SYNC" 2 "CLOSE" 7 "SNA";
VAL_ 216 BMS_HV_TracCntctr_Cmd_PT 0 "OPEN" 1 "CLOSED" 2 "IMPACT_OPEN" 3 "FAST_OPEN" 7 "SNA";
VAL_ 216 BMS_HV_RefTracHVBus_V_Vldty_PT 0 "VALID" 1 "INVALID";
VAL_ 216 BMS_HV_RefTracHVBus_V_PT 1023 "SNA";
VAL_ 216 BMS_HV_GFD_Inhibition_PT 0 "GFD_Allowed" 1 "GFD_Inhibited";
VAL_ 216 BMS_HV_DC_Chrgng_Cntct_K_Cmd_PT 0 "OPEN" 2 "CLOSE" 7 "SNA";
VAL_ 216 APM_LV_VsetPoint_PT 2047 "SNA";
VAL_ 216 APM_LV_VActual_PT 511 "SNA";
VAL_ 216 APM_LV_IMax_PT 511 "SNA";
VAL_ 2654339142 WakeupSource_FD05_BPCM 0 "No_Wakeup";
VAL_ 2654339142 PreviousCanNMState_FD05_BPCM 0 "Uninitialized State" 1 "Bus-Sleep State" 2 "Prepare-Bus State" 3 "Ready-Sleep State" 4 "Normal Operation State" 5 "Repeat Message State" 6 "Synchronize State" 7 "Offline State";
VAL_ 2654339142 GenericFailSts_FD05_BPCM 0 "No_Fail_Present" 1 "Fail_Present";
VAL_ 2654339142 EOL_FD05_BPCM 0 "No_EOL_Programming" 1 "EOL_Programming";
VAL_ 2654339142 DES_FD05_BPCM 0 "Error_Active_state" 1 "Error_passive_warning_state" 2 "Bus_off_state" 3 "Not_used";
VAL_ 2654339142 CurrentFailSts_FD05_BPCM 0 "No_Fail_Present" 1 "Fail_Present";
VAL_ 2654339142 CurrentCanNMState_FD05_BPCM 0 "Uninitialized State" 1 "Bus-Sleep State" 2 "Prepare-Bus State" 3 "Ready-Sleep State" 4 "Normal Operation State" 5 "Repeat Message State" 6 "Synchronize State" 7 "Offline State";
VAL_ 292 BPCM_Wakeup_Request 0 "No_Event" 1 "Wakeup_Event";
VAL_ 292 BPCM_HV_ThermalRunaway 0 "Default" 1 "No_Thermal_Runaway" 2 "Thermal_Runaway_Detected" 3 "SNA";
VAL_ 2654339161 GenericFailSts_FD16_MCPB 0 "No_Fail_Present" 1 "Fail_Present";
VAL_ 2654339161 DES_FD16_MCPB 0 "Error_Active_state" 1 "Error_passive_warning_state" 2 "Bus_off_state" 3 "Not_used";
VAL_ 2654339161 CurrentFailSts_FD16_MCPB 0 "No_Fail_Present" 1 "Fail_Present";
VAL_ 2654339160 GenericFailSts_FD16_MCPA 0 "No_Fail_Present" 1 "Fail_Present";
VAL_ 2654339160 DES_FD16_MCPA 0 "Error_Active_state" 1 "Error_passive_warning_state" 2 "Bus_off_state" 3 "Not_used";
VAL_ 2654339160 CurrentFailSts_FD16_MCPA 0 "No_Fail_Present" 1 "Fail_Present";
VAL_ 263 GasPedalPositionFailSts_PT 0 "Fail_not_present" 1 "Fail_present";
VAL_ 263 GasPedalPosition_PT 255 "SNA";
VAL_ 2654486592 CBV_bit4_ActiveWakeupBit_1E384040 0 "PassiveWakeup" 1 "ActiveWakeup";
VAL_ 2654486729 CBV_bit0_RepeatMessageRequestBit_1E3840C9 0 "Repeat_Message_State_not_requested" 1 "Repeat_Message_State_requested";
VAL_ 2654486729 CBV_bit3_NMCoordinatorBit_1E3840C9 0 "Start_of_synchronized_shutdown_is_not_requested_by_main_coordinator" 1 "Start_of_synchronized_shutdown_is_requested_by_main_coordinator";
VAL_ 2654486729 CBV_bit4_ActiveWakeupBit_1E3840C9 0 "PassiveWakeup" 1 "ActiveWakeup";
VAL_ 2654486729 CBV_bit6_PartialNtwInfBit_1E3840C9 0 "NM_PDU_contains_no_Partial_Network_request_information" 1 "NM_PDU_contains_Partial_Network_request_information";
VAL_ 1041 EVMinCurrent 511 "SNA";
VAL_ 1041 EVMaxVoltage 1023 "SNA";
VAL_ 1041 EVMaxCurrent 511 "SNA";
VAL_ 1041 Eamount 262143 "SNA";
VAL_ 1811 Real_Time_Validity 0 "Valid" 1 "Not_Valid";
VAL_ 1811 Real_Time_Clock 4294967295 "SNA";
VAL_ 216 APM_TypeCtrl_PT 0 "IDLE" 1 "Buck_CV" 2 "Buck_CC" 3 "Buck_CP" 4 "Buck_Special" 6 "PreCharge" 7 "DisCharge" 8 "OFF" 15 "SNA";
VAL_ 1070 SGCP_DTC_Stat1 0 "Not_Supported" 1 "Critically_disabled" 2 "No_status_to_report" 3 "Diagnostic_passed" 4 "Diagnostic_failed" 5 "Reset_DTC_status" 7 "SNA";
VAL_ 1070 SGCP_DTC_Idx2 31 "SNA";
VAL_ 1070 SGCP_DTC_Idx1 31 "SNA";
VAL_ 1070 SGCP_CalChar 255 "SNA";
VAL_ 1070 SGCP_Cal_ID_Idx 63 "SNA";
VAL_ 263 PropulsionMode_PT 0 "Hybrid_Parallel" 1 "EV_Only" 2 "Hybrid_Series" 7 "SNA";
VAL_ 216 EVCU_Resp_AUX_LoadTurned_Off 0 "FALSE" 1 "TRUE";
VAL_ 216 DC_Charge_Type_Command 1 "Plugged_into_800V" 2 "Plugged_into_400V" 3 "SNA";
VAL_ 1065 MCPB_DTC_Stat2 0 "Not_Supported" 1 "Critically_disabled" 2 "No_status_to_report" 3 "Diagnostic_passed" 4 "Diagnostic_failed" 5 "Reset_DTC_status" 7 "SNA";
VAL_ 1065 MCPB_DTC_Stat1 0 "Not_Supported" 1 "Critically_disabled" 2 "No_status_to_report" 3 "Diagnostic_passed" 4 "Diagnostic_failed" 5 "Reset_DTC_status" 7 "SNA";
VAL_ 1065 MCPB_DTC_Idx2 31 "SNA";
VAL_ 1065 MCPB_DTC_Idx1 31 "SNA";
VAL_ 1065 MCPB_CalChar 255 "SNA";
VAL_ 1065 MCPB_Cal_ID_Idx 63 "SNA";
VAL_ 1057 MCPA_DTC_Stat2 0 "Not_Supported" 1 "Critically_disabled" 2 "No_status_to_report" 3 "Diagnostic_passed" 4 "Diagnostic_failed" 5 "Reset_DTC_status" 7 "SNA";
VAL_ 1057 MCPA_DTC_Stat1 0 "Not_Supported" 1 "Critically_disabled" 2 "No_status_to_report" 3 "Diagnostic_passed" 4 "Diagnostic_failed" 5 "Reset_DTC_status" 7 "SNA";
VAL_ 1057 MCPA_DTC_Idx2 31 "SNA";
VAL_ 1057 MCPA_DTC_Idx1 31 "SNA";
VAL_ 1057 MCPA_CalChar 255 "SNA";
VAL_ 1057 MCPA_Cal_ID_Idx 63 "SNA";
VAL_ 292 DC_Charge_Type_Status 1 "Ready_to_charge_at_800V" 2 "Ready_to_charge_at_400V" 3 "FAILED" 4 "Weldcheck_in_progress_800V" 7 "SNA";
VAL_ 292 BPCM_Request_for_Aux_Load_off 0 "False" 1 "True";
VAL_ 292 BPCM_HV_Trac_Main_Contac_Config 1 "Closed_Parallel" 2 "Closed_Single_B1" 3 "Closed_Single_B2" 7 "SNA";
VAL_ 263 PropulsionSystemActive_PT 0 "NOT_ACTIVE" 1 "ACTIVE";
VAL_ 292 BPCM_HV_DCFC_Isolation_Sts 0 "Not_Performed" 1 "No_Failure" 3 "Failure" 4 "Error" 7 "SNA";
VAL_ 216 BMS_HV_Char_Main_Contac_Cmd_PT 0 "Open" 1 "Close" 2 "Impact_Open" 3 "Fast_Open" 7 "INV";
VAL_ 292 BPCM_HV_Trac_PreCha_Contac_Sts 0 "Not_Performed" 1 "No_Failure" 3 "Failure" 4 "Error" 7 "SNA";
VAL_ 1042 Contract_Certificate_Present 0 "Not_Available" 1 "Available";
VAL_ 1042 EVSE_Offered_AC_Single_Phase 0 "Not_offered" 1 "Offered";
VAL_ 1042 EVSE_Offered_AC_Three_Phase 0 "Not_offered" 1 "Offered";
VAL_ 292 BPCM_HV_Current_String2 65535 "SNA";
SIG_GROUP_ 292 BATTERY_HV_STATUS1_Pkt 1 : MessageCounter_BATT_HV_STATUS1 CRC_BATT_HV_STATUS1 HVBatContactorWeldCheck HVBatReady BPCM_DC_CntctrsMidTrmOpeningWarn BPCM_DC_CntctrsShtTrmOpeningWarn BPCM_HV_Char_Main_Contac_Sts BPCM_HV_Trac_Main_Contac_Sts BPCM_HV_BalancingMode BPCM_HV_ChargingBusVoltage BPCM_HV_TractionBusVoltage BPCM_Pwr_Limp_Home_On BPCM_HV_Trac_Bus_Sts BPCM_HV_Char_Bus_Sts BPCM_HV_SOH_Low BPCM_HV_SOH HVBatContactorOpenTime HVBatLastSlept BPCMInterlockSts BPCM_HV_BatIntrlk_InternalStat BPCM_HV_Temperature_Min BPCM_HV_Temperature_Max BPCM_HV_Temperature_Avg BPCM_HV_SOC BPCM_HV_Outlet_Temp BPCM_HV_InternalVoltage BPCM_HV_Inlet_Temp BPCM_HV_Current BPCM_HV_Capacity BPCM_HV_Battery_GFD_Sts BPCM_Wakeup_Request BPCM_HV_ThermalRunaway HVBP_Busbar_Temp HVBP_BDU_Busbar_Temp DC_Charge_Type_Status BPCM_Series_Voltage BPCM_Request_for_Aux_Load_off BPCM_HV_Trac_Main_Contac_Config BPCM_HV_InternalVoltageString2 BPCM_HV_InternalVoltageString1 BPCM_HV_DCFC_Isolation_Sts BPCM_HV_Trac_PreCha_Contac_Sts BPCM_HV_Current_String2;
SIG_GROUP_ 485 BATTERY_HV_VLIMITS_Pkt 1 : MessageCounter_BATT_HV_VLIMITS CRC_BATT_HV_VLIMITS BPCM_HV_NumCellMinTemp BPCM_HV_NumCellMaxTemp BPCM_HV_NumCellMinVolt BPCM_HV_NumCellMaxVolt BPCM_Min_Pk_Volt_Allowed BPCM_Max_Pk_Volt_Allowed BPCM_OCV_Min_Cell_Volt BPCM_OCV_Max_Cell_Volt BPCM_OCV_Avg_Cell_Volt BPCM_Min_Cell_Volt_Allowed BPCM_Max_Cell_Volt_Allowed BPCM_HV_Insulation_Resistance BPCM_Cell_Volt_Min BPCM_Cell_Volt_Max BPCM_Cell_Volt_Avg;
SIG_GROUP_ 288 BATTERY_HV_POWERLIMITS_Pkt 1 : BPCM_HV_HVBatChargeStat BPCM_HV_PwrLmtInstDschg BPCM_HV_PwrLmtInstChrg BPCM_HV_Pwr_MaxDischrg_ShrTrm BPCM_HV_Power_MaxDischarge_MdTrm BPCM_HV_Power_MaxDischarge_LgTrm BPCM_HV_Power_MaxCharge_ShrTrm BPCM_HV_Power_MaxCharge_MdTrm BPCM_HV_Power_MaxCharge_LgTrm BPCM_HV_CrntLmtInstDschg BPCM_HV_CrntLmtInstChrg BPCM_HV_ChargingCurrentProfile BPCM_HV_Cell_MinDischrg_Imped BPCM_HV_Cell_MaxDischrg_Imped BPCM_CntctrsShtTrmOpeningWarn BPCM_CntctrsMidTrmOpeningWarn MessageCounter_BATT_HV_POWERLIMS CRC_BATT_HV_POWERLIMS;
SIG_GROUP_ 263 PT_SYSTEM_FD_1_Pkt 1 : OptimdStrtReqdActr OptimdEngStrtStpType OptimdEngOnOffCmd Hyb_ProducingTorque HCPFuelDisable PowertrainPrplsnActv_PT GearEngagedForDisplay_PT GearEngaged_PT DriveReady_PT MessageCounter_PT_SYSTEM_FD_1 GasPedalPositionFailSts_PT GasPedalPosition_PT CRC_PT_SYSTEM_FD_1 PropulsionMode_PT PropulsionSystemActive_PT;
SIG_GROUP_ 216 PT_ENERGY_FD_1_Pkt 1 : MC_PT_ENERGY_FD_1 DCChrgVoltMin_PT DCChrgVoltMax_PT DCChrgPwrLim_PT DCChrgCurrentRq_PT DCChrgCurrentLimit_PT DCChargeInitialized_PT DCChargeEnRq_PT CRC_PT_ENERGY_FD_1 BPCM_OBCM_AC_ContactorCmd_PT BMS_HV_TracCntctr_Cmd_PT BMS_HV_RefTracHVBus_V_Vldty_PT BMS_HV_RefTracHVBus_V_PT BMS_HV_GFD_Inhibition_PT BMS_HV_DC_Chrgng_Cntct_K_Cmd_PT BatteryVoltage_Raw_PT APM_LV_VsetPoint_PT APM_LV_VActual_PT APM_LV_IMax_PT APM_HV_IMax_PT APM_TypeCtrl_PT EVCU_Resp_AUX_LoadTurned_Off DC_Charge_Type_Command BMS_HV_Char_Main_Contac_Cmd_PT;
SIG_GROUP_ 1070 SGCP_OBD_DTC_Pkt 1 : SGCP_DTC_Stat2 SGCP_DTC_Stat1 SGCP_DTC_Idx2 SGCP_DTC_Idx1 SGCP_CalChar SGCP_Cal_ID_Idx MessageCounter_SGCP_OBD_DTC CRC_SGCP_OBD_DTC;
SIG_GROUP_ 1065 MCPB_OBD_DTC_Pkt 1 : MessageCounter_MCPB_OBD_DTC MCPB_DTC_Stat2 MCPB_DTC_Stat1 MCPB_DTC_Idx2 MCPB_DTC_Idx1 MCPB_CalChar MCPB_Cal_ID_Idx CRC_MCPB_OBD_DTC;
SIG_GROUP_ 1057 MCPA_OBD_DTC_Pkt 1 : MessageCounter_MCPA_OBD_DTC MCPA_DTC_Stat2 MCPA_DTC_Stat1 MCPA_DTC_Idx2 MCPA_DTC_Idx1 MCPA_CalChar MCPA_Cal_ID_Idx CRC_MCPA_OBD_DTC;
